VERSION "dbc-export 1 2025.20.8"

NS_ :

BS_:

BU_: ADSP APB APP APS BB BMS CC CP DAS DI DIF DIR EPAS3P EPAS3S EPBL EPBR GTW HVP ICR IDB PCS PM TCU UI UIS VC VCFRONT VCLEFT VCRIGHT VCSEC

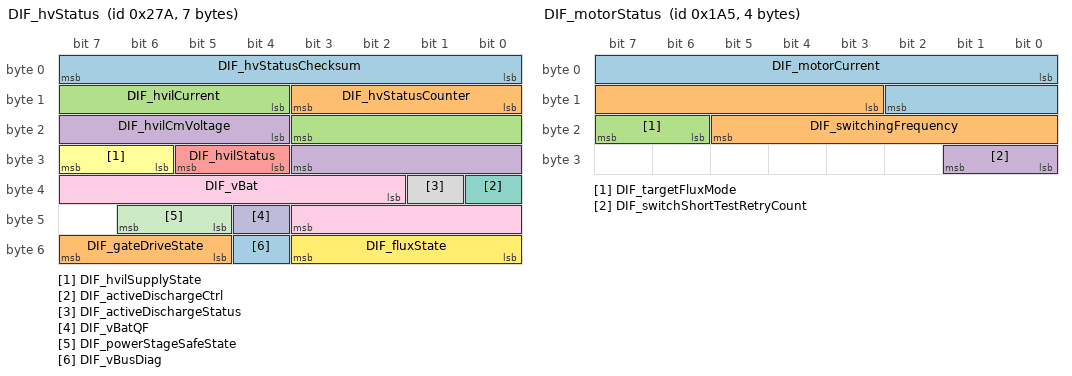
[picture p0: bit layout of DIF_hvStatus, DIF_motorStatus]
BO_ 634 DIF_hvStatus: 7 DIF
 SG_ DIF_hvStatusChecksum : 0|8@1+ (1,0) [0|255] "" Vector__XXX
 SG_ DIF_hvStatusCounter : 8|4@1+ (1,0) [0|15] "" Vector__XXX
 SG_ DIF_hvilCurrent : 12|8@1+ (0.1,0) [0|25.5] "mA" Vector__XXX
 SG_ DIF_hvilCmVoltage : 20|8@1+ (0.08,0) [0|20.4] "V" Vector__XXX
 SG_ DIF_hvilStatus : 28|2@1+ (1,0) [0|2] "" Vector__XXX
 SG_ DIF_hvilSupplyState : 30|2@1+ (1,0) [0|3] "" Vector__XXX
 SG_ DIF_activeDischargeCtrl : 32|1@1+ (1,0) [0|1] "" Vector__XXX
 SG_ DIF_activeDischargeStatus : 33|1@1+ (1,0) [0|1] "" Vector__XXX
 SG_ DIF_vBat : 34|10@1+ (1,0) [0|1023] "V" Vector__XXX
 SG_ DIF_vBatQF : 44|1@1+ (1,0) [0|1] "" Vector__XXX
 SG_ DIF_powerStageSafeState : 45|2@1+ (1,0) [0|3] "" Vector__XXX
 SG_ DIF_fluxState : 48|4@1+ (1,0) [0|15] "" Vector__XXX
 SG_ DIF_vBusDiag : 52|1@1+ (1,0) [0|1] "" Vector__XXX
 SG_ DIF_gateDriveState : 53|3@1+ (1,0) [0|7] "" Vector__XXX

BO_ 1622 DIF_info: 8 DIF
 SG_ DIF_infoIndex M : 0|8@1+ (1,0) [0|255] "" Vector__XXX
 SG_ DIF_buildType m10 : 8|3@1+ (1,0) [0|7] "" Vector__XXX
 SG_ DIF_buildConfigurationId m10 : 16|16@1+ (1,0) [0|65535] "" Vector__XXX
 SG_ DIF_hardwareId m10 : 32|8@1+ (1,0) [0|252] "" Vector__XXX
 SG_ DIF_componentId m10 : 48|16@1+ (1,0) [0|65535] "" Vector__XXX
 SG_ DIF_pcbaId m11 : 16|8@1+ (1,0) [0|255] "" Vector__XXX
 SG_ DIF_assemblyId m11 : 24|8@1+ (1,0) [0|255] "" Vector__XXX
 SG_ DIF_usageId m11 : 32|16@1+ (1,0) [0|65535] "" Vector__XXX
 SG_ DIF_subUsageId m11 : 48|16@1+ (1,0) [0|65535] "" Vector__XXX
 SG_ DIF_motorType m12 : 8|5@1+ (1,0) [1|31] "" Vector__XXX
 SG_ DIF_siliconType m12 : 16|1@1+ (1,0) [0|1] "" Vector__XXX
 SG_ DIF_mechSafeStateType m12 : 24|2@1+ (1,0) [1|3] "" Vector__XXX
 SG_ DIF_applicationCrc m13 : 32|32@1+ (1,0) [0|4294967295] "" Vector__XXX
 SG_ DIF_oilPumpBuildType m16 : 8|3@1+ (1,0) [0|7] "" Vector__XXX
 SG_ DIF_oilPumpAppCrc m16 : 16|32@1+ (1,0) [0|4294967295] "" Vector__XXX
 SG_ DIF_FPGA_version m16 : 48|8@1+ (1,0) [0|254] "" Vector__XXX
 SG_ DIF_appGitHash m17 : 8|56@1+ (1,0) [0|7.20575940379e+16] "" Vector__XXX
 SG_ DIF_bootGitHash m18 : 8|56@1+ (1,0) [0|7.20575940379e+16] "" Vector__XXX
 SG_ DIF_platformTyp m19 : 8|8@1+ (1,0) [0|255] "" Vector__XXX
 SG_ DIF_infoBootLdUdsProtocolVersion m20 : 8|8@1+ (1,0) [0|255] "" Vector__XXX
 SG_ DIF_bootloaderCrc m20 : 32|32@1+ (1,0) [0|4294967295] "" Vector__XXX
 SG_ DIF_oilPumpPcbaId m33 : 8|8@1+ (1,0) [0|255] "" Vector__XXX
 SG_ DIF_oilPumpAssemblyId m33 : 16|8@1+ (1,0) [0|255] "" Vector__XXX
 SG_ DIF_oilPumpUsageId m33 : 24|16@1+ (1,0) [0|65535] "" Vector__XXX
 SG_ DIF_refRotorFlux m35 : 8|16@1+ (0.0001,0) [0|6.5535] "Wb" Vector__XXX
 SG_ DIF_refRotorOffset m35 : 24|12@1- (0.1,0) [-180|180] "deg" Vector__XXX
 SG_ DIF_speedWearTotal m36 : 8|8@1+ (0.4,0) [0|100] "%" Vector__XXX
 SG_ DIF_torqueWearTotal m36 : 24|8@1+ (0.02,0) [0|5.08] "1" Vector__XXX

BO_ 421 DIF_motorStatus: 4 DIF
 SG_ DIF_motorCurrent : 0|11@1+ (1,0) [0|2047] "A" Vector__XXX
 SG_ DIF_switchingFrequency : 11|11@1+ (0.01,0) [0|20] "kHz" Vector__XXX
 SG_ DIF_targetFluxMode : 22|2@1+ (1,0) [0|3] "" Vector__XXX
 SG_ DIF_switchShortTestRetryCount : 24|2@1+ (1,0) [0|3] "" Vector__XXX

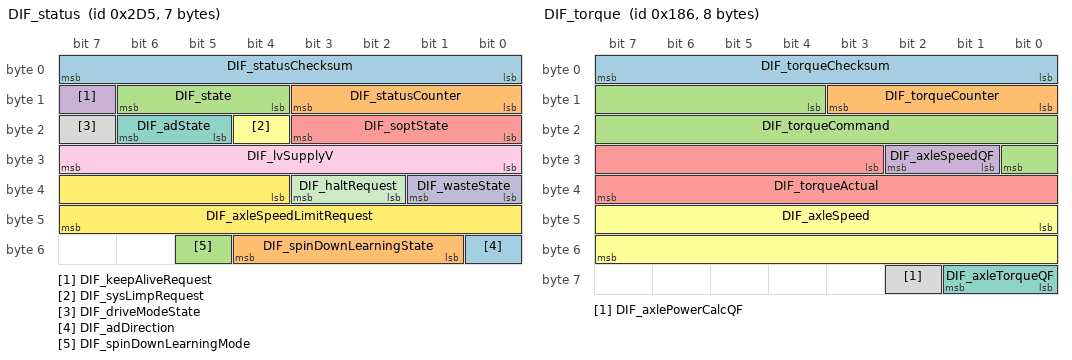
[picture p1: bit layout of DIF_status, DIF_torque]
BO_ 725 DIF_status: 7 DIF
 SG_ DIF_statusChecksum : 0|8@1+ (1,0) [0|255] "" Vector__XXX
 SG_ DIF_statusCounter : 8|4@1+ (1,0) [0|15] "" Vector__XXX
 SG_ DIF_state : 12|3@1+ (1,0) [0|7] "" Vector__XXX
 SG_ DIF_keepAliveRequest : 15|1@1+ (1,0) [0|1] "" Vector__XXX
 SG_ DIF_soptState : 16|4@1+ (1,0) [0|15] "" Vector__XXX
 SG_ DIF_sysLimpRequest : 20|1@1+ (1,0) [0|1] "" Vector__XXX
 SG_ DIF_adState : 21|2@1+ (1,0) [0|3] "" Vector__XXX
 SG_ DIF_driveModeState : 23|1@1+ (1,0) [0|1] "" Vector__XXX
 SG_ DIF_lvSupplyV : 24|8@1+ (0.1,0) [0|25.5] "V" Vector__XXX
 SG_ DIF_wasteState : 32|2@1+ (1,0) [0|3] "" Vector__XXX
 SG_ DIF_haltRequest : 34|2@1+ (1,0) [0|3] "" Vector__XXX
 SG_ DIF_axleSpeedLimitRequest : 36|12@1+ (1,40) [40|2750] "RPM" Vector__XXX
 SG_ DIF_adDirection : 48|1@1+ (1,0) [0|1] "" Vector__XXX
 SG_ DIF_spinDownLearningState : 49|4@1+ (1,0) [0|15] "" Vector__XXX
 SG_ DIF_spinDownLearningMode : 53|1@1+ (1,0) [0|1] "" Vector__XXX

BO_ 886 DIF_temperature: 8 DIF
 SG_ DIF_tempIndex M : 0|3@1+ (1,0) [0|7] "" Vector__XXX
 SG_ DIF_inverterTQF m0 : 3|2@1+ (1,0) [0|3] "" Vector__XXX
 SG_ DIF_pcbT m0 : 8|8@1+ (1,-40) [-39|215] "DegC" Vector__XXX
 SG_ DIF_inverterT m0 : 16|8@1+ (1,-40) [-40|215] "DegC" Vector__XXX
 SG_ DIF_statorT m0 : 24|8@1+ (1,-40) [-39|215] "DegC" Vector__XXX
 SG_ DIF_dcCapT m0 : 32|8@1+ (1,-40) [-39|215] "DegC" Vector__XXX
 SG_ DIF_heatsinkT m0 : 40|8@1+ (1,-40) [-39|215] "DegC" Vector__XXX
 SG_ DIF_inverterTpct m0 : 48|8@1+ (0.4,0) [0|100] "%" Vector__XXX
 SG_ DIF_statorTpct m0 : 56|8@1+ (0.4,0) [0|100] "%" Vector__XXX
 SG_ DIF_fluidInTemp m2 : 8|8@1+ (1,-40) [-39|215] "DegC" Vector__XXX
 SG_ DIF_normalFetBurnIn m2 : 16|16@1+ (0.00763,0) [0|500] "Hours" Vector__XXX
 SG_ DIF_additionalFetBurnIn m2 : 32|16@1+ (0.00763,0) [0|500] "Hours" Vector__XXX
 SG_ DIF_currentWeibullMiles m3 : 3|16@1+ (8,0) [0|500000] "miles" Vector__XXX
 SG_ DIF_endOfServiceWeibullMiles m3 : 19|16@1+ (8,0) [0|500000] "miles" Vector__XXX
 SG_ DIF_burnInDamageRatio m3 : 35|9@1+ (0.01,0) [0|5] "1" Vector__XXX
 SG_ DIF_inverterSensorEst m3 : 44|8@1+ (1,-40) [-40|120] "C" Vector__XXX
 SG_ DIF_inverterHS1Est m3 : 52|8@1+ (1,-40) [-40|120] "C" Vector__XXX
 SG_ DIF_initialBurnInVehicleOdometer m4 : 8|32@1+ (0.001,0) [0|4294967.294] "km" Vector__XXX
 SG_ DIF_inverterHS2Est m4 : 40|8@1+ (1,-40) [-40|120] "C" Vector__XXX
 SG_ DIF_inverterInletEst m4 : 48|8@1+ (1,-40) [-40|120] "C" Vector__XXX

BO_ 390 DIF_torque: 8 DIF
 SG_ DIF_torqueChecksum : 0|8@1+ (1,0) [0|255] "" Vector__XXX
 SG_ DIF_torqueCounter : 8|4@1+ (1,0) [0|15] "" Vector__XXX
 SG_ DIF_torqueCommand : 12|13@1- (2,0) [-7500|7500] "Nm" Vector__XXX
 SG_ DIF_axleSpeedQF : 25|2@1+ (1,0) [0|3] "" Vector__XXX
 SG_ DIF_torqueActual : 27|13@1- (2,0) [-7500|7500] "Nm" Vector__XXX
 SG_ DIF_axleSpeed : 40|16@1- (0.1,0) [-2750|2750] "RPM" Vector__XXX
 SG_ DIF_axleTorqueQF : 56|2@1+ (1,0) [0|3] "" Vector__XXX
 SG_ DIF_axlePowerCalcQF : 58|1@1+ (1,0) [0|1] "" Vector__XXX

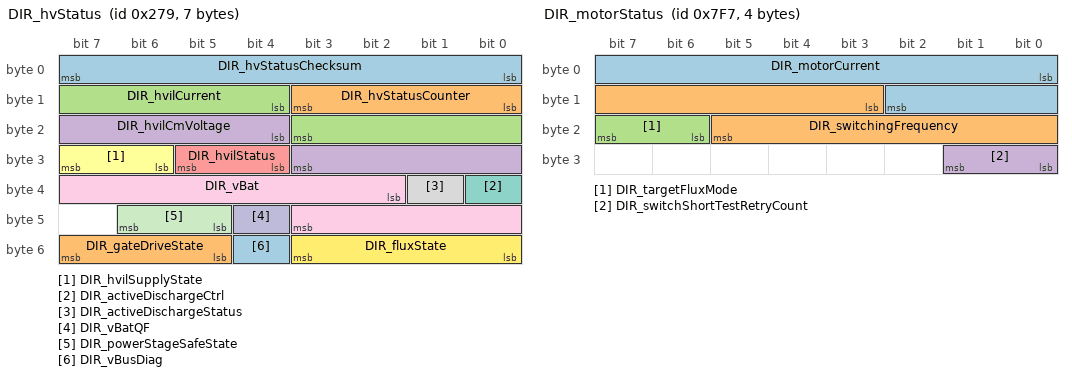
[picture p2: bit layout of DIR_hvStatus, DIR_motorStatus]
BO_ 633 DIR_hvStatus: 7 DIR
 SG_ DIR_hvStatusChecksum : 0|8@1+ (1,0) [0|255] "" Vector__XXX
 SG_ DIR_hvStatusCounter : 8|4@1+ (1,0) [0|15] "" Vector__XXX
 SG_ DIR_hvilCurrent : 12|8@1+ (0.1,0) [0|25.5] "mA" Vector__XXX
 SG_ DIR_hvilCmVoltage : 20|8@1+ (0.08,0) [0|20.4] "V" Vector__XXX
 SG_ DIR_hvilStatus : 28|2@1+ (1,0) [0|2] "" Vector__XXX
 SG_ DIR_hvilSupplyState : 30|2@1+ (1,0) [0|3] "" Vector__XXX
 SG_ DIR_activeDischargeCtrl : 32|1@1+ (1,0) [0|1] "" Vector__XXX
 SG_ DIR_activeDischargeStatus : 33|1@1+ (1,0) [0|1] "" Vector__XXX
 SG_ DIR_vBat : 34|10@1+ (1,0) [0|1023] "V" Vector__XXX
 SG_ DIR_vBatQF : 44|1@1+ (1,0) [0|1] "" Vector__XXX
 SG_ DIR_powerStageSafeState : 45|2@1+ (1,0) [0|3] "" Vector__XXX
 SG_ DIR_fluxState : 48|4@1+ (1,0) [0|15] "" Vector__XXX
 SG_ DIR_vBusDiag : 52|1@1+ (1,0) [0|1] "" Vector__XXX
 SG_ DIR_gateDriveState : 53|3@1+ (1,0) [0|7] "" Vector__XXX

BO_ 821 DIR_info: 8 DIR
 SG_ DIR_infoIndex M : 0|8@1+ (1,0) [0|255] "" Vector__XXX
 SG_ DIR_buildType m10 : 8|3@1+ (1,0) [0|7] "" Vector__XXX
 SG_ DIR_buildConfigurationId m10 : 16|16@1+ (1,0) [0|65535] "" Vector__XXX
 SG_ DIR_hardwareId m10 : 32|8@1+ (1,0) [0|252] "" Vector__XXX
 SG_ DIR_componentId m10 : 48|16@1+ (1,0) [0|65535] "" Vector__XXX
 SG_ DIR_pcbaId m11 : 16|8@1+ (1,0) [0|255] "" Vector__XXX
 SG_ DIR_assemblyId m11 : 24|8@1+ (1,0) [0|255] "" Vector__XXX
 SG_ DIR_usageId m11 : 32|16@1+ (1,0) [0|65535] "" Vector__XXX
 SG_ DIR_subUsageId m11 : 48|16@1+ (1,0) [0|65535] "" Vector__XXX
 SG_ DIR_motorType m12 : 8|5@1+ (1,0) [1|31] "" Vector__XXX
 SG_ DIR_siliconType m12 : 16|1@1+ (1,0) [0|1] "" Vector__XXX
 SG_ DIR_mechSafeStateType m12 : 24|2@1+ (1,0) [1|3] "" Vector__XXX
 SG_ DIR_applicationCrc m13 : 32|32@1+ (1,0) [0|4294967295] "" Vector__XXX
 SG_ DIR_oilPumpBuildType m16 : 8|3@1+ (1,0) [0|7] "" Vector__XXX
 SG_ DIR_oilPumpAppCrc m16 : 16|32@1+ (1,0) [0|4294967295] "" Vector__XXX
 SG_ DIR_FPGA_version m16 : 48|8@1+ (1,0) [0|254] "" Vector__XXX
 SG_ DIR_bootGitHash m18 : 8|56@1+ (1,0) [0|7.20575940379e+16] "" Vector__XXX
 SG_ DIR_infoBootLdUdsProtocolVersion m20 : 8|8@1+ (1,0) [0|255] "" Vector__XXX
 SG_ DIR_bootloaderCrc m20 : 32|32@1+ (1,0) [0|4294967295] "" Vector__XXX
 SG_ DIR_oilPumpPcbaId m33 : 8|8@1+ (1,0) [0|255] "" Vector__XXX
 SG_ DIR_oilPumpAssemblyId m33 : 16|8@1+ (1,0) [0|255] "" Vector__XXX
 SG_ DIR_oilPumpUsageId m33 : 24|16@1+ (1,0) [0|65535] "" Vector__XXX
 SG_ DIR_refRotorFlux m35 : 8|16@1+ (0.0001,0) [0|6.5535] "Wb" Vector__XXX
 SG_ DIR_refRotorOffset m35 : 24|12@1- (0.1,0) [-180|180] "deg" Vector__XXX
 SG_ DIR_speedWearTotal m36 : 8|8@1+ (0.4,0) [0|100] "%" Vector__XXX
 SG_ DIR_torqueWearTotal m36 : 24|8@1+ (0.02,0) [0|5.08] "1" Vector__XXX

BO_ 2039 DIR_motorStatus: 4 DIR
 SG_ DIR_motorCurrent : 0|11@1+ (1,0) [0|2047] "A" Vector__XXX
 SG_ DIR_switchingFrequency : 11|11@1+ (0.01,0) [0|20] "kHz" Vector__XXX
 SG_ DIR_targetFluxMode : 22|2@1+ (1,0) [0|3] "" Vector__XXX
 SG_ DIR_switchShortTestRetryCount : 24|2@1+ (1,0) [0|3] "" Vector__XXX

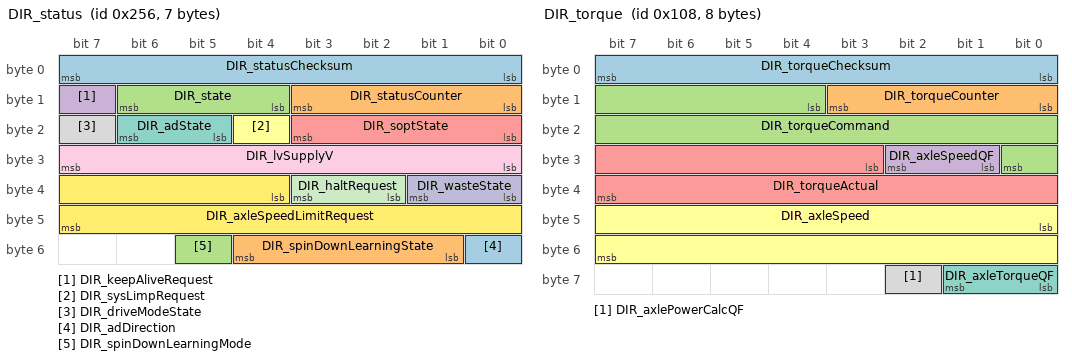
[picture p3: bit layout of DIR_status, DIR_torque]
BO_ 598 DIR_status: 7 DIR
 SG_ DIR_statusChecksum : 0|8@1+ (1,0) [0|255] "" Vector__XXX
 SG_ DIR_statusCounter : 8|4@1+ (1,0) [0|15] "" Vector__XXX
 SG_ DIR_state : 12|3@1+ (1,0) [0|7] "" Vector__XXX
 SG_ DIR_keepAliveRequest : 15|1@1+ (1,0) [0|1] "" Vector__XXX
 SG_ DIR_soptState : 16|4@1+ (1,0) [0|15] "" Vector__XXX
 SG_ DIR_sysLimpRequest : 20|1@1+ (1,0) [0|1] "" Vector__XXX
 SG_ DIR_adState : 21|2@1+ (1,0) [0|3] "" Vector__XXX
 SG_ DIR_driveModeState : 23|1@1+ (1,0) [0|1] "" Vector__XXX
 SG_ DIR_lvSupplyV : 24|8@1+ (0.1,0) [0|25.5] "V" Vector__XXX
 SG_ DIR_wasteState : 32|2@1+ (1,0) [0|3] "" Vector__XXX
 SG_ DIR_haltRequest : 34|2@1+ (1,0) [0|3] "" Vector__XXX
 SG_ DIR_axleSpeedLimitRequest : 36|12@1+ (1,40) [400|2750] "RPM" Vector__XXX
 SG_ DIR_adDirection : 48|1@1+ (1,0) [0|1] "" Vector__XXX
 SG_ DIR_spinDownLearningState : 49|4@1+ (1,0) [0|15] "" Vector__XXX
 SG_ DIR_spinDownLearningMode : 53|1@1+ (1,0) [0|1] "" Vector__XXX

BO_ 789 DIR_temperature: 8 DIR
 SG_ DIR_tempIndex M : 0|3@1+ (1,0) [0|7] "" Vector__XXX
 SG_ DIR_inverterTQF m0 : 3|2@1+ (1,0) [0|3] "" Vector__XXX
 SG_ DIR_pcbT m0 : 8|8@1+ (1,-40) [-39|215] "DegC" Vector__XXX
 SG_ DIR_inverterT m0 : 16|8@1+ (1,-40) [-40|215] "DegC" Vector__XXX
 SG_ DIR_statorT m0 : 24|8@1+ (1,-40) [-39|215] "DegC" Vector__XXX
 SG_ DIR_dcCapT m0 : 32|8@1+ (1,-40) [-39|215] "DegC" Vector__XXX
 SG_ DIR_heatsinkT m0 : 40|8@1+ (1,-40) [-39|215] "DegC" Vector__XXX
 SG_ DIR_inverterTpct m0 : 48|8@1+ (0.4,0) [0|100] "%" Vector__XXX
 SG_ DIR_statorTpct m0 : 56|8@1+ (0.4,0) [0|100] "%" Vector__XXX
 SG_ DIR_fluidInTemp m2 : 8|8@1+ (1,-40) [-39|215] "DegC" Vector__XXX
 SG_ DIR_normalFetBurnIn m2 : 16|16@1+ (0.00763,0) [0|500] "Hours" Vector__XXX
 SG_ DIR_additionalFetBurnIn m2 : 32|16@1+ (0.00763,0) [0|500] "Hours" Vector__XXX
 SG_ DIR_currentWeibullMiles m3 : 3|16@1+ (8,0) [0|500000] "miles" Vector__XXX
 SG_ DIR_endOfServiceWeibullMiles m3 : 19|16@1+ (8,0) [0|500000] "miles" Vector__XXX
 SG_ DIR_burnInDamageRatio m3 : 35|9@1+ (0.01,0) [0|5] "1" Vector__XXX
 SG_ DIR_inverterSensorEst m3 : 44|8@1+ (1,-40) [-40|120] "C" Vector__XXX
 SG_ DIR_inverterHS1Est m3 : 52|8@1+ (1,-40) [-40|120] "C" Vector__XXX
 SG_ DIR_initialBurnInVehicleOdometer m4 : 8|32@1+ (0.001,0) [0|4294967.294] "km" Vector__XXX
 SG_ DIR_inverterHS2Est m4 : 40|8@1+ (1,-40) [-40|120] "C" Vector__XXX
 SG_ DIR_inverterInletEst m4 : 48|8@1+ (1,-40) [-40|120] "C" Vector__XXX

BO_ 264 DIR_torque: 8 DIR
 SG_ DIR_torqueChecksum : 0|8@1+ (1,0) [0|255] "" Vector__XXX
 SG_ DIR_torqueCounter : 8|4@1+ (1,0) [0|15] "" Vector__XXX
 SG_ DIR_torqueCommand : 12|13@1- (2,0) [-7500|7500] "Nm" Vector__XXX
 SG_ DIR_axleSpeedQF : 25|2@1+ (1,0) [0|3] "" Vector__XXX
 SG_ DIR_torqueActual : 27|13@1- (2,0) [-7500|7500] "Nm" Vector__XXX
 SG_ DIR_axleSpeed : 40|16@1- (0.1,0) [-2750|2750] "RPM" Vector__XXX
 SG_ DIR_axleTorqueQF : 56|2@1+ (1,0) [0|3] "" Vector__XXX
 SG_ DIR_axlePowerCalcQF : 58|1@1+ (1,0) [0|1] "" Vector__XXX

BO_ 1861 DI_chassisControl2: 8 DI
 SG_ DI_gradeAngle : 0|6@1- (0.01,0) [-0.3125|0.31] "rad" Vector__XXX
 SG_ DI_bankAngle : 6|6@1- (0.01,0) [-0.3125|0.31] "rad" Vector__XXX
 SG_ DI_chassisControlVideoRequest : 12|4@1+ (1,0) [0|15] "" Vector__XXX
 SG_ DI_tireUtilizationRatioFrL : 17|5@1+ (0.0625,0) [0|1.9375] "-" Vector__XXX
 SG_ DI_tireUtilizationRatioFrR : 22|5@1+ (0.0625,0) [0|1.9375] "-" Vector__XXX
 SG_ DI_tireUtilizationRatioReL : 27|5@1+ (0.0625,0) [0|1.9375] "-" Vector__XXX
 SG_ DI_tireUtilizationRatioReR : 32|5@1+ (0.0625,0) [0|1.9375] "-" Vector__XXX
 SG_ DI_counterSteerTarget : 37|2@1+ (1,0) [0|3] "" Vector__XXX
 SG_ DI_splitMuProbability : 39|2@1+ (0.334,0) [0|1] "-" Vector__XXX
 SG_ DI_mzError : 41|2@1+ (1667,0) [0|5000] "Nm" Vector__XXX
 SG_ DI_slipDifferenceFrontRear : 43|3@1- (0.133,0) [-0.52|0.399] "rad" Vector__XXX
 SG_ DI_highFreqYawRate : 46|2@1+ (0.334,0) [0|1] "-" Vector__XXX
 SG_ DI_turnDirection : 48|1@1+ (1,0) [0|1] "" Vector__XXX
 SG_ DI_absolutePreControlRequest : 49|2@1+ (5000,0) [0|15000] "Nm" Vector__XXX
 SG_ DI_oppositeBuildDirFrontAxle : 51|1@1+ (1,0) [0|1] "" Vector__XXX
 SG_ DI_oppositeBuildDirRearAxle : 52|1@1+ (1,0) [0|1] "" Vector__XXX
 SG_ DI_saturatedEffectiveness : 53|1@1+ (1,0) [0|1] "" Vector__XXX
 SG_ DI_driverPanicIndex : 54|2@1+ (0.334,0) [0|1] "-" Vector__XXX
 SG_ DI_learnDownMu : 56|2@1+ (0.334,0) [0|1] "mu" Vector__XXX
 SG_ DI_preControlOpposingTurnDir : 58|1@1+ (1,0) [0|1] "" Vector__XXX
 SG_ DI_driverFxError : 59|2@1+ (1000,0) [0|3000] "N" Vector__XXX
 SG_ DI_targetSaturation : 61|3@1+ (0.572,0) [0|4] "G" Vector__XXX

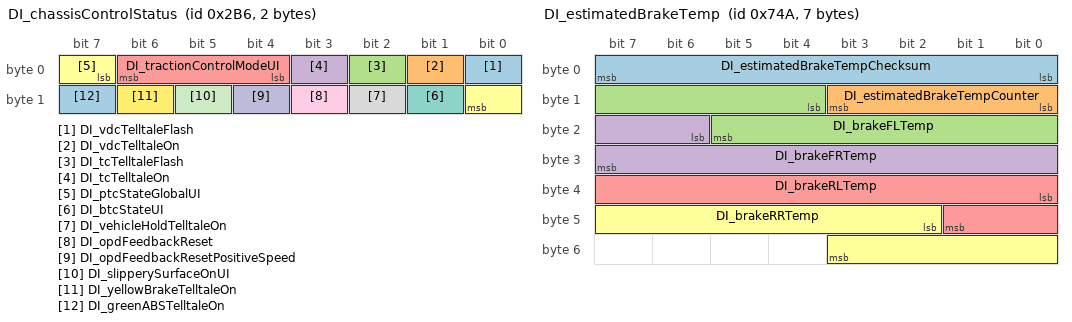
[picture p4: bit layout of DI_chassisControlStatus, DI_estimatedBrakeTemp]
BO_ 694 DI_chassisControlStatus: 2 DI
 SG_ DI_vdcTelltaleFlash : 0|1@1+ (1,0) [0|1] "" Vector__XXX
 SG_ DI_vdcTelltaleOn : 1|1@1+ (1,0) [0|1] "" Vector__XXX
 SG_ DI_tcTelltaleFlash : 2|1@1+ (1,0) [0|1] "" Vector__XXX
 SG_ DI_tcTelltaleOn : 3|1@1+ (1,0) [0|1] "" Vector__XXX
 SG_ DI_tractionControlModeUI : 4|3@1+ (1,0) [0|7] "" Vector__XXX
 SG_ DI_ptcStateGlobalUI : 7|2@1+ (1,0) [0|2] "" Vector__XXX
 SG_ DI_btcStateUI : 9|1@1+ (1,0) [0|1] "" Vector__XXX
 SG_ DI_vehicleHoldTelltaleOn : 10|1@1+ (1,0) [0|1] "" Vector__XXX
 SG_ DI_opdFeedbackReset : 11|1@1+ (1,0) [0|1] "" Vector__XXX
 SG_ DI_opdFeedbackResetPositiveSpeed : 12|1@1+ (1,0) [0|1] "" Vector__XXX
 SG_ DI_slipperySurfaceOnUI : 13|1@1+ (1,0) [0|1] "" Vector__XXX
 SG_ DI_yellowBrakeTelltaleOn : 14|1@1+ (1,0) [0|1] "" Vector__XXX
 SG_ DI_greenABSTelltaleOn : 15|1@1+ (1,0) [0|1] "" Vector__XXX

BO_ 1866 DI_estimatedBrakeTemp: 7 DI
 SG_ DI_estimatedBrakeTempChecksum : 0|8@1+ (1,0) [0|255] "" Vector__XXX
 SG_ DI_estimatedBrakeTempCounter : 8|4@1+ (1,0) [0|15] "" Vector__XXX
 SG_ DI_brakeFLTemp : 12|10@1+ (1,-40) [-40|982] "DegC" Vector__XXX
 SG_ DI_brakeFRTemp : 22|10@1+ (1,-40) [-40|982] "DegC" Vector__XXX
 SG_ DI_brakeRLTemp : 32|10@1+ (1,-40) [-40|982] "DegC" Vector__XXX
 SG_ DI_brakeRRTemp : 42|10@1+ (1,-40) [-40|982] "DegC" Vector__XXX

BO_ 1623 DI_info: 8 DI
 SG_ DI_infoIndex M : 0|8@1+ (1,0) [0|255] "" Vector__XXX
 SG_ DI_buildType m10 : 8|3@1+ (1,0) [0|7] "" Vector__XXX
 SG_ DI_buildConfigurationId m10 : 16|16@1+ (1,0) [0|65535] "" Vector__XXX
 SG_ DI_hardwareId m10 : 32|8@1+ (1,0) [0|252] "" Vector__XXX
 SG_ DI_componentId m10 : 48|16@1+ (1,0) [0|65535] "" Vector__XXX
 SG_ DI_pcbaId m11 : 16|8@1+ (1,0) [0|255] "" Vector__XXX
 SG_ DI_assemblyId m11 : 24|8@1+ (1,0) [0|255] "" Vector__XXX
 SG_ DI_usageId m11 : 32|16@1+ (1,0) [0|65535] "" Vector__XXX
 SG_ DI_subUsageId m11 : 48|16@1+ (1,0) [0|65535] "" Vector__XXX
 SG_ DI_applicationCrc m13 : 32|32@1+ (1,0) [0|4294967295] "" Vector__XXX
 SG_ DI_bootGitHash m18 : 8|56@1+ (1,0) [0|7.20575940379e+16] "" Vector__XXX

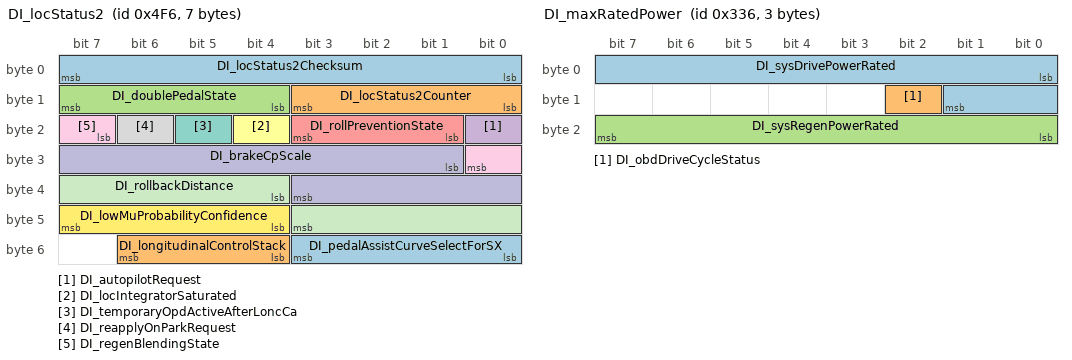
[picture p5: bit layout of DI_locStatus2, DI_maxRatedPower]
BO_ 1270 DI_locStatus2: 7 DI
 SG_ DI_locStatus2Checksum : 0|8@1+ (1,0) [0|255] "" Vector__XXX
 SG_ DI_locStatus2Counter : 8|4@1+ (1,0) [0|15] "" Vector__XXX
 SG_ DI_doublePedalState : 12|4@1+ (1,0) [0|15] "" Vector__XXX
 SG_ DI_autopilotRequest : 16|1@1+ (1,0) [0|1] "" Vector__XXX
 SG_ DI_rollPreventionState : 17|3@1+ (1,0) [0|7] "" Vector__XXX
 SG_ DI_locIntegratorSaturated : 20|1@1+ (1,0) [0|1] "" Vector__XXX
 SG_ DI_temporaryOpdActiveAfterLoncCa : 21|1@1+ (1,0) [0|1] "" Vector__XXX
 SG_ DI_reapplyOnParkRequest : 22|1@1+ (1,0) [0|1] "" Vector__XXX
 SG_ DI_regenBlendingState : 23|2@1+ (1,0) [0|3] "" Vector__XXX
 SG_ DI_brakeCpScale : 25|11@1+ (0.005,0) [0|10] "N/N" Vector__XXX
 SG_ DI_rollbackDistance : 36|8@1+ (0.005,0) [0|1.275] "m" Vector__XXX
 SG_ DI_lowMuProbabilityConfidence : 44|4@1+ (0.06666667,0) [0|1] "-" Vector__XXX
 SG_ DI_pedalAssistCurveSelectForSX : 48|4@1+ (1,0) [0|15] "" Vector__XXX
 SG_ DI_longitudinalControlStack : 52|3@1+ (1,0) [1|7] "" Vector__XXX

BO_ 822 DI_maxRatedPower: 3 DI
 SG_ DI_sysDrivePowerRated : 0|10@1+ (1,0) [0|1023] "kW" Vector__XXX
 SG_ DI_obdDriveCycleStatus : 10|1@1+ (1,0) [0|1] "" Vector__XXX
 SG_ DI_sysRegenPowerRated : 16|8@1+ (1,-100) [-100|0] "kW" Vector__XXX

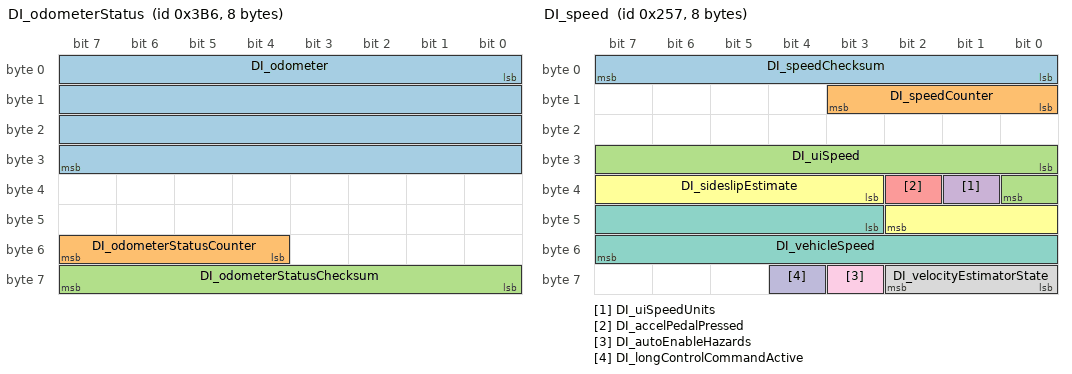
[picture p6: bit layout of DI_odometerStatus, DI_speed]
BO_ 950 DI_odometerStatus: 8 DI
 SG_ DI_odometer : 0|32@1+ (0.001,0) [0|4294967.294] "km" Vector__XXX
 SG_ DI_odometerStatusCounter : 52|4@1+ (1,0) [0|15] "" Vector__XXX
 SG_ DI_odometerStatusChecksum : 56|8@1+ (1,0) [0|255] "" Vector__XXX

BO_ 599 DI_speed: 8 DI
 SG_ DI_speedChecksum : 0|8@1+ (1,0) [0|255] "" Vector__XXX
 SG_ DI_speedCounter : 8|4@1+ (1,0) [0|15] "" Vector__XXX
 SG_ DI_uiSpeed : 24|9@1+ (1,0) [0|510] "" Vector__XXX
 SG_ DI_uiSpeedUnits : 33|1@1+ (1,0) [0|1] "" Vector__XXX
 SG_ DI_accelPedalPressed : 34|1@1+ (1,0) [0|1] "" Vector__XXX
 SG_ DI_sideslipEstimate : 35|8@1- (0.0025,0) [-0.32|0.3175] "rad" Vector__XXX
 SG_ DI_vehicleSpeed : 43|13@1+ (0.08,-40) [-40|480] "kph" Vector__XXX
 SG_ DI_velocityEstimatorState : 56|3@1+ (1,0) [0|7] "" Vector__XXX
 SG_ DI_autoEnableHazards : 59|1@1+ (1,0) [0|1] "" Vector__XXX
 SG_ DI_longControlCommandActive : 60|1@1+ (1,0) [0|1] "" Vector__XXX

BO_ 296 DI_systemLimits: 4 DI
 SG_ DI_limitRegenPower : 0|1@1+ (1,0) [0|1] "" Vector__XXX
 SG_ DI_limitIBat : 1|1@1+ (1,0) [0|1] "" Vector__XXX
 SG_ DI_limitVBatLow : 2|1@1+ (1,0) [0|1] "" Vector__XXX
 SG_ DI_limitVBatHigh : 3|1@1+ (1,0) [0|1] "" Vector__XXX
 SG_ DI_limitObstacleDetection : 4|1@1+ (1,0) [0|1] "" Vector__XXX
 SG_ DI_limitSystemLimp : 5|1@1+ (1,0) [0|1] "" Vector__XXX
 SG_ DI_limitSystemGPO : 6|1@1+ (1,0) [0|1] "" Vector__XXX
 SG_ DI_limitShift : 7|1@1+ (1,0) [0|1] "" Vector__XXX
 SG_ DI_limitDriveTorque : 8|1@1+ (1,0) [0|1] "" Vector__XXX
 SG_ DI_limitRegenTorque : 9|1@1+ (1,0) [0|1] "" Vector__XXX
 SG_ DI_limitVehicleSpeed : 10|1@1+ (1,0) [0|1] "" Vector__XXX
 SG_ DI_limitBmsMiaFreeze : 11|1@1+ (1,0) [0|1] "" Vector__XXX
 SG_ DI_limitSystemSpinDownLearning : 12|1@1+ (1,0) [0|1] "" Vector__XXX
 SG_ DI_limitCdp : 13|1@1+ (1,0) [0|1] "" Vector__XXX
 SG_ DI_vehicleSpeedLimitType : 14|2@1+ (1,0) [0|3] "" Vector__XXX
 SG_ DI_vehicleSpeedLimit : 16|9@1+ (1,0) [0|510] "kph" Vector__XXX
 SG_ DI_vehicleSpeedLimitReason : 25|4@1+ (1,0) [0|15] "" Vector__XXX
 SG_ DI_limitClosureNotClosed : 29|1@1+ (1,0) [0|1] "" Vector__XXX
 SG_ DI_proximity : 30|1@1+ (1,0) [0|1] "" Vector__XXX
 SG_ DI_undersideAbuse : 31|1@1+ (1,0) [0|1] "" Vector__XXX

BO_ 280 DI_systemStatus: 8 DI
 SG_ DI_systemStatusChecksum : 0|8@1+ (1,0) [0|255] "" Vector__XXX
 SG_ DI_systemStatusCounter : 8|4@1+ (1,0) [0|15] "" Vector__XXX
 SG_ DI_secondaryGearControlStatus : 12|1@1+ (1,0) [0|1] "" Vector__XXX
 SG_ DI_immobilizerState : 13|3@1+ (1,0) [1|7] "" Vector__XXX
 SG_ DI_systemState : 16|3@1+ (1,0) [0|7] "" Vector__XXX
 SG_ DI_brakePedalState : 19|2@1+ (1,0) [0|3] "" Vector__XXX
 SG_ DI_gear : 21|3@1+ (1,0) [0|6] "" Vector__XXX
 SG_ DI_driveBlocked : 24|3@1+ (1,0) [0|7] "" Vector__XXX
 SG_ DI_hvilSystemStatus : 27|2@1+ (1,0) [0|2] "" Vector__XXX
 SG_ DI_driveModeState : 29|1@1+ (1,0) [0|1] "" Vector__XXX
 SG_ DI_shiftRequestType : 30|2@1+ (1,0) [0|3] "" Vector__XXX
 SG_ DI_accelPedalPos : 32|8@1+ (0.4,0) [0|100] "%" Vector__XXX
 SG_ DI_tractionControlMode : 40|3@1+ (1,0) [0|7] "" Vector__XXX
 SG_ DI_dynoModeAvailable : 43|1@1+ (1,0) [0|1] "" Vector__XXX
 SG_ DI_epbRequest : 44|2@1+ (1,0) [0|3] "" Vector__XXX
 SG_ DI_eepDeliveryBitStatus : 46|1@1+ (1,0) [0|1] "" Vector__XXX
 SG_ DI_keepDrivePowerStateRequest : 47|1@1+ (1,0) [0|1] "" Vector__XXX
 SG_ DI_trackModeState : 48|2@1+ (1,0) [0|3] "" Vector__XXX
 SG_ DI_regenLight : 51|1@1+ (1,0) [0|1] "" Vector__XXX
 SG_ DI_vehicleAcceleration : 52|12@1- (0.01,0) [-20.47|20.47] "m/s^2" Vector__XXX

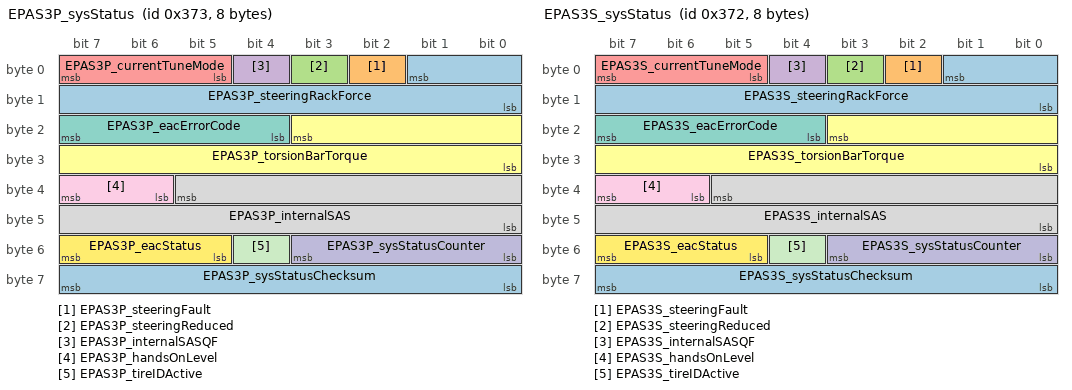
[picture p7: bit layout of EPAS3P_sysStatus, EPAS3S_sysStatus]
BO_ 883 EPAS3P_sysStatus: 8 EPAS3P
 SG_ EPAS3P_steeringRackForce : 1|10@0+ (50,-25575) [-25575|25525] "N" Vector__XXX
 SG_ EPAS3P_steeringFault : 2|1@1+ (1,0) [0|1] "" Vector__XXX
 SG_ EPAS3P_steeringReduced : 3|1@1+ (1,0) [0|1] "" Vector__XXX
 SG_ EPAS3P_internalSASQF : 4|1@1+ (1,0) [0|1] "" Vector__XXX
 SG_ EPAS3P_currentTuneMode : 5|3@1+ (1,0) [0|7] "" Vector__XXX
 SG_ EPAS3P_torsionBarTorque : 19|12@0+ (0.01,-20.5) [-20.5|20.44] "Nm" Vector__XXX
 SG_ EPAS3P_eacErrorCode : 20|4@1+ (1,0) [0|14] "" Vector__XXX
 SG_ EPAS3P_internalSAS : 37|14@0+ (0.1,-819.2) [-819.2|819] "deg" Vector__XXX
 SG_ EPAS3P_handsOnLevel : 38|2@1+ (1,0) [0|3] "" Vector__XXX
 SG_ EPAS3P_sysStatusCounter : 48|4@1+ (1,0) [0|15] "" Vector__XXX
 SG_ EPAS3P_tireIDActive : 52|1@1+ (1,0) [0|1] "" Vector__XXX
 SG_ EPAS3P_eacStatus : 53|3@1+ (1,0) [0|7] "" Vector__XXX
 SG_ EPAS3P_sysStatusChecksum : 56|8@1+ (1,0) [0|255] "" Vector__XXX

BO_ 882 EPAS3S_sysStatus: 8 EPAS3S
 SG_ EPAS3S_steeringRackForce : 1|10@0+ (50,-25575) [-25575|25525] "N" Vector__XXX
 SG_ EPAS3S_steeringFault : 2|1@1+ (1,0) [0|1] "" Vector__XXX
 SG_ EPAS3S_steeringReduced : 3|1@1+ (1,0) [0|1] "" Vector__XXX
 SG_ EPAS3S_internalSASQF : 4|1@1+ (1,0) [0|1] "" Vector__XXX
 SG_ EPAS3S_currentTuneMode : 5|3@1+ (1,0) [0|7] "" Vector__XXX
 SG_ EPAS3S_torsionBarTorque : 19|12@0+ (0.01,-20.5) [-20.5|20.44] "Nm" Vector__XXX
 SG_ EPAS3S_eacErrorCode : 20|4@1+ (1,0) [0|14] "" Vector__XXX
 SG_ EPAS3S_internalSAS : 37|14@0+ (0.1,-819.2) [-819.2|819] "deg" Vector__XXX
 SG_ EPAS3S_handsOnLevel : 38|2@1+ (1,0) [0|3] "" Vector__XXX
 SG_ EPAS3S_sysStatusCounter : 48|4@1+ (1,0) [0|15] "" Vector__XXX
 SG_ EPAS3S_tireIDActive : 52|1@1+ (1,0) [0|1] "" Vector__XXX
 SG_ EPAS3S_eacStatus : 53|3@1+ (1,0) [0|7] "" Vector__XXX
 SG_ EPAS3S_sysStatusChecksum : 56|8@1+ (1,0) [0|255] "" Vector__XXX

BO_ 681 EPBL_status: 8 EPBL
 SG_ EPBL_systemStatus : 0|4@1+ (1,0) [0|15] "" Vector__XXX
 SG_ EPBL_freeRollModeStatus : 4|2@1+ (1,0) [0|3] "" Vector__XXX
 SG_ EPBL_driverIsLeaving : 6|1@1+ (1,0) [0|1] "" Vector__XXX
 SG_ EPBL_driverIsLeavingAnySpeed : 7|1@1+ (1,0) [0|1] "" Vector__XXX
 SG_ EPBL_systemCdpAvailable : 8|1@1+ (1,0) [0|1] "" Vector__XXX
 SG_ EPBL_chimeRequest : 9|3@1+ (1,0) [0|7] "" Vector__XXX
 SG_ EPBL_telltale : 12|3@1+ (1,0) [0|6] "" Vector__XXX
 SG_ EPBL_contactorCycleNotNeededForW : 15|1@1+ (1,0) [0|1] "" Vector__XXX
 SG_ EPBL_redundantBrakingEnabled : 16|1@1+ (1,0) [0|1] "" Vector__XXX
 SG_ EPBL_summonEnabled : 17|1@1+ (1,0) [0|1] "" Vector__XXX
 SG_ EPBL_brakeLight : 18|1@1+ (1,0) [0|1] "" Vector__XXX
 SG_ EPBL_epbConfigMismatch : 19|1@1+ (1,0) [0|1] "" Vector__XXX
 SG_ EPBL_brakeConfirmedPressed : 20|1@1+ (1,0) [0|1] "" Vector__XXX
 SG_ EPBL_requestUserConfirmation : 21|1@1+ (1,0) [0|1] "" Vector__XXX
 SG_ EPBL_uiWinchModeMiscBlocking : 22|1@1+ (1,0) [0|1] "" Vector__XXX
 SG_ EPBL_winchModeActive : 23|1@1+ (1,0) [0|1] "" Vector__XXX
 SG_ EPBL_updateMode : 24|1@1+ (1,0) [0|1] "" Vector__XXX
 SG_ EPBL_winchModePermissive : 25|1@1+ (1,0) [0|1] "" Vector__XXX
 SG_ EPBL_winchModePending : 26|1@1+ (1,0) [0|1] "" Vector__XXX
 SG_ EPBL_cdpRequest : 27|1@1+ (1,0) [0|1] "" Vector__XXX
 SG_ EPBL_uiParkAvailable : 28|2@1+ (1,0) [0|3] "" Vector__XXX
 SG_ EPBL_brakeDiscWipeRequest : 30|2@1+ (1,0) [0|2] "" Vector__XXX
 SG_ EPBL_showUiGearShifter : 32|1@1+ (1,0) [0|1] "" Vector__XXX
 SG_ EPBL_uiWinchModeLvStatus : 33|2@1+ (1,0) [0|3] "" Vector__XXX
 SG_ EPBL_showStalkFaultedOnUi : 45|1@1+ (1,0) [0|1] "" Vector__XXX
 SG_ EPBL_espPowerRequest : 46|1@1+ (1,0) [0|1] "" Vector__XXX
 SG_ EPBL_okToPark : 47|1@1+ (1,0) [0|1] "" Vector__XXX
 SG_ EPBL_hornRequest : 48|1@1+ (1,0) [0|1] "" Vector__XXX
 SG_ EPBL_winchModeAvailable : 49|1@1+ (1,0) [0|1] "" Vector__XXX
 SG_ EPBL_bothDisconnected : 50|1@1+ (1,0) [0|1] "" Vector__XXX
 SG_ EPBL_blockDrive : 51|1@1+ (1,0) [0|1] "" Vector__XXX
 SG_ EPBL_statusCounter : 52|4@1+ (1,0) [0|15] "" Vector__XXX
 SG_ EPBL_statusChecksum : 56|8@1+ (1,0) [0|255] "" Vector__XXX

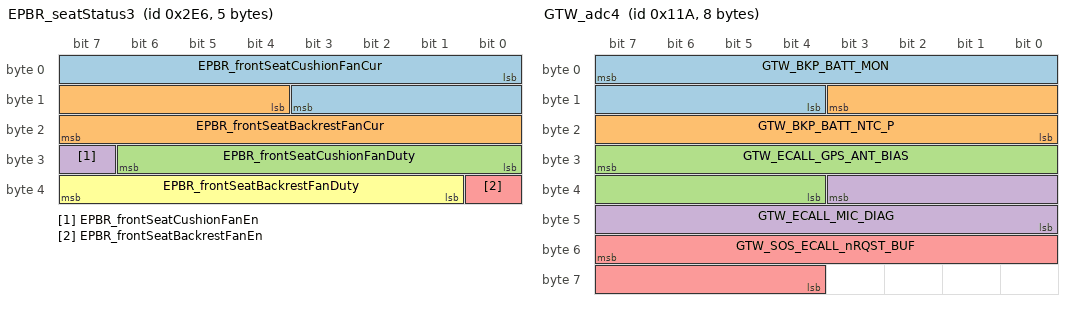
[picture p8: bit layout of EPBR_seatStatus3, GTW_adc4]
BO_ 742 EPBR_seatStatus3: 5 EPBR
 SG_ EPBR_frontSeatCushionFanCur : 0|12@1+ (0.01,0) [0|40.95] "A" Vector__XXX
 SG_ EPBR_frontSeatBackrestFanCur : 12|12@1+ (0.01,0) [0|40.95] "A" Vector__XXX
 SG_ EPBR_frontSeatCushionFanDuty : 24|7@1+ (1,0) [0|100] "%" Vector__XXX
 SG_ EPBR_frontSeatCushionFanEn : 31|1@1+ (1,0) [0|1] "" Vector__XXX
 SG_ EPBR_frontSeatBackrestFanEn : 32|1@1+ (1,0) [0|1] "" Vector__XXX
 SG_ EPBR_frontSeatBackrestFanDuty : 33|7@1+ (1,0) [0|100] "%" Vector__XXX

BO_ 744 EPBR_status: 8 EPBR
 SG_ EPBR_systemStatus : 0|4@1+ (1,0) [0|15] "" Vector__XXX
 SG_ EPBR_freeRollModeStatus : 4|2@1+ (1,0) [0|3] "" Vector__XXX
 SG_ EPBR_driverIsLeaving : 6|1@1+ (1,0) [0|1] "" Vector__XXX
 SG_ EPBR_driverIsLeavingAnySpeed : 7|1@1+ (1,0) [0|1] "" Vector__XXX
 SG_ EPBR_systemCdpAvailable : 8|1@1+ (1,0) [0|1] "" Vector__XXX
 SG_ EPBR_chimeRequest : 9|3@1+ (1,0) [0|7] "" Vector__XXX
 SG_ EPBR_telltale : 12|3@1+ (1,0) [0|6] "" Vector__XXX
 SG_ EPBR_audioCurrentSpikeDetected : 15|1@1+ (1,0) [0|1] "" Vector__XXX
 SG_ EPBR_redundantBrakingEnabled : 16|1@1+ (1,0) [0|1] "" Vector__XXX
 SG_ EPBR_summonEnabled : 17|1@1+ (1,0) [0|1] "" Vector__XXX
 SG_ EPBR_brakeLight : 18|1@1+ (1,0) [0|1] "" Vector__XXX
 SG_ EPBR_epbConfigMismatch : 19|1@1+ (1,0) [0|1] "" Vector__XXX
 SG_ EPBR_brakeConfirmedPressed : 20|1@1+ (1,0) [0|1] "" Vector__XXX
 SG_ EPBR_requestUserConfirmation : 21|1@1+ (1,0) [0|1] "" Vector__XXX
 SG_ EPBR_uiWinchModeMiscBlocking : 22|1@1+ (1,0) [0|1] "" Vector__XXX
 SG_ EPBR_winchModeActive : 23|1@1+ (1,0) [0|1] "" Vector__XXX
 SG_ EPBR_updateMode : 24|1@1+ (1,0) [0|1] "" Vector__XXX
 SG_ EPBR_winchModePermissive : 25|1@1+ (1,0) [0|1] "" Vector__XXX
 SG_ EPBR_winchModePending : 26|1@1+ (1,0) [0|1] "" Vector__XXX
 SG_ EPBR_cdpRequest : 27|1@1+ (1,0) [0|1] "" Vector__XXX
 SG_ EPBR_uiParkAvailable : 28|2@1+ (1,0) [0|3] "" Vector__XXX
 SG_ EPBR_brakeDiscWipeRequest : 30|2@1+ (1,0) [0|2] "" Vector__XXX
 SG_ EPBR_showUiGearShifter : 32|1@1+ (1,0) [0|1] "" Vector__XXX
 SG_ EPBR_uiWinchModeLvStatus : 33|2@1+ (1,0) [0|3] "" Vector__XXX
 SG_ EPBR_contactorCycleNotNeededForW : 35|1@1+ (1,0) [0|1] "" Vector__XXX
 SG_ EPBR_showStalkFaultedOnUi : 45|1@1+ (1,0) [0|1] "" Vector__XXX
 SG_ EPBR_espPowerRequest : 46|1@1+ (1,0) [0|1] "" Vector__XXX
 SG_ EPBR_okToPark : 47|1@1+ (1,0) [0|1] "" Vector__XXX
 SG_ EPBR_hornRequest : 48|1@1+ (1,0) [0|1] "" Vector__XXX
 SG_ EPBR_winchModeAvailable : 49|1@1+ (1,0) [0|1] "" Vector__XXX
 SG_ EPBR_bothDisconnected : 50|1@1+ (1,0) [0|1] "" Vector__XXX
 SG_ EPBR_blockDrive : 51|1@1+ (1,0) [0|1] "" Vector__XXX
 SG_ EPBR_statusCounter : 52|4@1+ (1,0) [0|15] "" Vector__XXX
 SG_ EPBR_statusChecksum : 56|8@1+ (1,0) [0|255] "" Vector__XXX

BO_ 888 GTW_ECall: 1 GTW
 SG_ GTW_GTW_SOS_ECALL_RQST : 0|1@1+ (1,0) [0|1] "" Vector__XXX
 SG_ GTW_LTE_ECALL_LOCK : 1|1@1+ (1,0) [0|1] "" Vector__XXX

BO_ 282 GTW_adc4: 8 GTW
 SG_ GTW_BKP_BATT_MON : 7|12@0+ (1,0) [0|4094] "mV" Vector__XXX
 SG_ GTW_BKP_BATT_NTC_P : 11|12@0+ (1,0) [0|4094] "mV" Vector__XXX
 SG_ GTW_ECALL_GPS_ANT_BIAS : 31|12@0+ (1,0) [0|4094] "mV" Vector__XXX
 SG_ GTW_ECALL_MIC_DIAG : 35|12@0+ (1,0) [0|4094] "mV" Vector__XXX
 SG_ GTW_SOS_ECALL_nRQST_BUF : 55|12@0+ (1,0) [0|4094] "mV" Vector__XXX

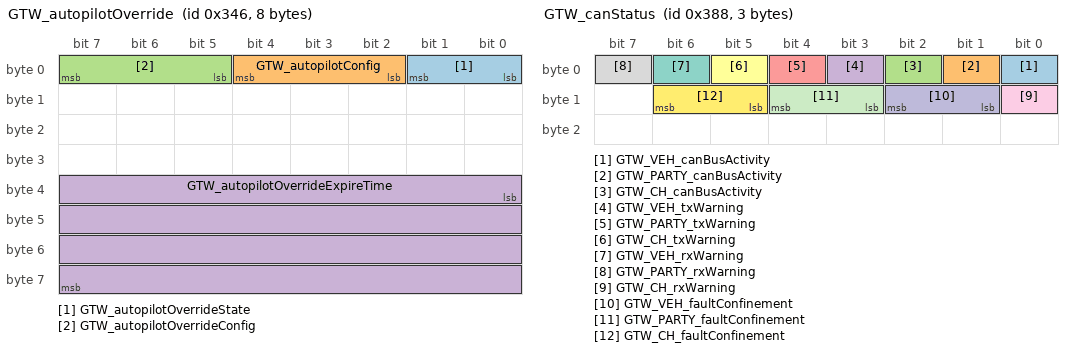
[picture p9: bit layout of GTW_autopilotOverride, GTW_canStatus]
BO_ 838 GTW_autopilotOverride: 8 GTW
 SG_ GTW_autopilotOverrideState : 0|2@1+ (1,0) [0|3] "" Vector__XXX
 SG_ GTW_autopilotConfig : 2|3@1+ (1,0) [0|7] "" Vector__XXX
 SG_ GTW_autopilotOverrideConfig : 5|3@1+ (1,0) [0|7] "" Vector__XXX
 SG_ GTW_autopilotOverrideExpireTime : 32|32@1+ (1,0) [0|4294967295] "" Vector__XXX

BO_ 904 GTW_canStatus: 3 GTW
 SG_ GTW_VEH_canBusActivity : 0|1@1+ (1,0) [0|1] "" Vector__XXX
 SG_ GTW_PARTY_canBusActivity : 1|1@1+ (1,0) [0|1] "" Vector__XXX
 SG_ GTW_CH_canBusActivity : 2|1@1+ (1,0) [0|1] "" Vector__XXX
 SG_ GTW_VEH_txWarning : 3|1@1+ (1,0) [0|1] "" Vector__XXX
 SG_ GTW_PARTY_txWarning : 4|1@1+ (1,0) [0|1] "" Vector__XXX
 SG_ GTW_CH_txWarning : 5|1@1+ (1,0) [0|1] "" Vector__XXX
 SG_ GTW_VEH_rxWarning : 6|1@1+ (1,0) [0|1] "" Vector__XXX
 SG_ GTW_PARTY_rxWarning : 7|1@1+ (1,0) [0|1] "" Vector__XXX
 SG_ GTW_CH_rxWarning : 8|1@1+ (1,0) [0|1] "" Vector__XXX
 SG_ GTW_VEH_faultConfinement : 9|2@1+ (1,0) [0|3] "" Vector__XXX
 SG_ GTW_PARTY_faultConfinement : 11|2@1+ (1,0) [0|3] "" Vector__XXX
 SG_ GTW_CH_faultConfinement : 13|2@1+ (1,0) [0|3] "" Vector__XXX

BO_ 2047 GTW_carConfig: 8 GTW
 SG_ GTW_carConfigMultiplexer M : 0|8@1+ (1,0) [0|255] "" Vector__XXX
 SG_ GTW_deliveryStatus m1 : 8|1@1+ (1,0) [0|1] "" Vector__XXX
 SG_ GTW_cabinPTCHeaterType m1 : 10|1@1+ (1,0) [0|1] "" Vector__XXX
 SG_ GTW_rightHandDrive m1 : 11|1@1+ (1,0) [0|1] "" Vector__XXX
 SG_ GTW_rearLightType m1 : 12|2@1+ (1,0) [0|3] "" Vector__XXX
 SG_ GTW_headlamps m1 : 14|2@1+ (1,0) [0|3] "" Vector__XXX
 SG_ GTW_country m1 : 16|16@1+ (1,0) [0|65535] "" Vector__XXX
 SG_ GTW_tireType m1 : 32|6@1+ (1,0) [0|63] "" Vector__XXX
 SG_ GTW_roofGlassType m1 : 38|2@1+ (1,0) [0|3] "" Vector__XXX
 SG_ GTW_dasHw m1 : 40|3@1+ (1,0) [3|5] "" Vector__XXX
 SG_ GTW_brakeHWType m1 : 43|5@1+ (1,0) [0|31] "" Vector__XXX
 SG_ GTW_restraintsHardwareType m1 : 48|8@1+ (1,0) [0|255] "" Vector__XXX
 SG_ GTW_drivetrainType m1 : 56|4@1+ (1,0) [0|4] "" Vector__XXX
 SG_ GTW_radarHeaterType m1 : 60|3@1+ (1,0) [0|5] "" Vector__XXX
 SG_ GTW_exteriorTrimType m2 : 8|1@1+ (1,0) [0|1] "" Vector__XXX
 SG_ GTW_frontSeatHeaters m2 : 9|1@1+ (1,0) [0|1] "" Vector__XXX
 SG_ GTW_rearSeatHeaters m2 : 10|1@1+ (1,0) [0|1] "" Vector__XXX
 SG_ GTW_eCallAntennaHW m2 : 12|1@1+ (1,0) [0|1] "" Vector__XXX
 SG_ GTW_homelinkType m2 : 13|1@1+ (1,0) [0|1] "" Vector__XXX
 SG_ GTW_vdcType m2 : 14|1@1+ (1,0) [0|1] "" Vector__XXX
 SG_ GTW_memoryMirrors m2 : 17|1@1+ (1,0) [0|1] "" Vector__XXX
 SG_ GTW_powerLiftgateType m2 : 18|2@1+ (1,0) [0|2] "" Vector__XXX
 SG_ GTW_lumbarECUType m2 : 20|4@1+ (1,0) [0|15] "" Vector__XXX
 SG_ GTW_rearSeatHeaterType m2 : 24|2@1+ (1,0) [0|3] "" Vector__XXX
 SG_ GTW_auxParkLamps m2 : 26|2@1+ (1,0) [0|3] "" Vector__XXX
 SG_ GTW_interiorCabinRadarType m2 : 28|1@1+ (1,0) [0|1] "" Vector__XXX
 SG_ GTW_hvacPanelVaneType m2 : 29|1@1+ (1,0) [0|1] "" Vector__XXX
 SG_ GTW_intakeAirFilterType m2 : 30|2@1+ (1,0) [0|2] "" Vector__XXX
 SG_ GTW_eBuckConfig m2 : 32|1@1+ (1,0) [0|1] "" Vector__XXX
 SG_ GTW_steeringHeaterEnabled m2 : 33|1@1+ (1,0) [0|1] "" Vector__XXX
 SG_ GTW_activeHighBeam m2 : 34|1@1+ (1,0) [0|1] "" Vector__XXX
 SG_ GTW_airbagCutoffSwitch m2 : 35|1@1+ (1,0) [0|1] "" Vector__XXX
 SG_ GTW_intrusionSensorType m2 : 36|1@1+ (1,0) [0|1] "" Vector__XXX
 SG_ GTW_spoilerType m2 : 37|1@1+ (1,0) [0|1] "" Vector__XXX
 SG_ GTW_rearFogLamps m2 : 39|1@1+ (1,0) [0|1] "" Vector__XXX
 SG_ GTW_roofType m2 : 40|1@1+ (1,0) [0|1] "" Vector__XXX
 SG_ GTW_thirdRowSeatType m2 : 41|1@1+ (1,0) [0|1] "" Vector__XXX
 SG_ GTW_autopilot m2 : 42|3@1+ (1,0) [0|7] "" Vector__XXX
 SG_ GTW_superchargingAccess m2 : 45|2@1+ (1,0) [0|3] "" Vector__XXX
 SG_ GTW_exteriorColor m2 : 48|5@1+ (1,0) [0|31] "" Vector__XXX
 SG_ GTW_pedestrianWarningSound m2 : 53|2@1+ (1,0) [0|3] "" Vector__XXX
 SG_ GTW_steeringColumnUJointType m2 : 55|1@1+ (1,0) [0|1] "" Vector__XXX
 SG_ GTW_bPillarNFCParam m2 : 56|1@1+ (1,0) [0|1] "" Vector__XXX
 SG_ GTW_interiorLighting m2 : 57|3@1+ (1,0) [0|7] "" Vector__XXX
 SG_ GTW_headlightLevelerType m2 : 60|2@1+ (1,0) [0|3] "" Vector__XXX
 SG_ GTW_numberHVILNodes m2 : 62|2@1+ (1,0) [0|3] "" Vector__XXX
 SG_ GTW_mapRegion m3 : 8|4@1+ (1,0) [0|15] "" Vector__XXX
 SG_ GTW_performancePackage m3 : 12|3@1+ (1,0) [0|7] "" Vector__XXX
 SG_ GTW_chassisType m3 : 18|4@1+ (1,0) [0|15] "" Vector__XXX
 SG_ GTW_airSuspension m3 : 22|2@1+ (1,0) [0|3] "" Vector__XXX
 SG_ GTW_centerConsoleControllerType m3 : 24|2@1+ (1,0) [0|3] "" Vector__XXX
 SG_ GTW_autopilotCameraType m3 : 26|1@1+ (1,0) [0|1] "" Vector__XXX
 SG_ GTW_connectivityPackage m3 : 27|1@1+ (1,0) [0|1] "" Vector__XXX
 SG_ GTW_plcSupportType m3 : 28|2@1+ (1,0) [0|3] "" Vector__XXX
 SG_ GTW_packEnergy m3 : 32|5@1+ (1,0) [0|31] "" Vector__XXX
 SG_ GTW_frontSeatReclinerHardware m3 : 37|2@1+ (1,0) [0|3] "" Vector__XXX
 SG_ GTW_brakeLineSwitchType m3 : 39|1@1+ (1,0) [0|1] "" Vector__XXX
 SG_ GTW_softRange m3 : 42|3@1+ (1,0) [0|7] "" Vector__XXX
 SG_ GTW_refrigerantType m3 : 45|2@1+ (1,0) [0|3] "" Vector__XXX
 SG_ GTW_wheelType m3 : 48|7@1+ (1,0) [0|127] "" Vector__XXX
 SG_ GTW_brakeActuationType m3 : 57|3@1+ (1,0) [0|4] "" Vector__XXX
 SG_ GTW_secondRowSeatType m3 : 60|3@1+ (1,0) [0|7] "" Vector__XXX
 SG_ GTW_secondRowSeatMotorType m3 : 63|1@1+ (1,0) [0|1] "" Vector__XXX
 SG_ GTW_birthday m4 : 8|32@1+ (1,0) [0|4294967295] "" Vector__XXX
 SG_ GTW_eCallEnabled m4 : 40|2@1+ (1,0) [0|3] "" Vector__XXX
 SG_ GTW_parkAssistECUType m4 : 42|2@1+ (1,0) [0|3] "" Vector__XXX
 SG_ GTW_passengerAirbagType m4 : 44|2@1+ (1,0) [0|3] "" Vector__XXX
 SG_ GTW_forwardRadarHw m4 : 46|2@1+ (1,0) [0|2] "" Vector__XXX
 SG_ GTW_frontSeatType m4 : 48|4@1+ (1,0) [0|15] "" Vector__XXX
 SG_ GTW_secondRowDisplayType m4 : 52|1@1+ (1,0) [0|1] "" Vector__XXX
 SG_ GTW_wirelessPhoneChargerType m4 : 53|2@1+ (1,0) [0|3] "" Vector__XXX
 SG_ GTW_ethernetTunerType m4 : 55|2@1+ (1,0) [0|3] "" Vector__XXX
 SG_ GTW_interiorTrimType m4 : 60|4@1+ (1,0) [0|15] "" Vector__XXX
 SG_ GTW_gloveboxUSBType m5 : 8|2@1+ (1,0) [0|3] "" Vector__XXX
 SG_ GTW_coolantPumpType m5 : 10|3@1+ (1,0) [0|7] "" Vector__XXX
 SG_ GTW_epblHwType m5 : 13|4@1+ (1,0) [0|15] "" Vector__XXX
 SG_ GTW_epbrHwType m5 : 17|4@1+ (1,0) [0|15] "" Vector__XXX
 SG_ GTW_blowerMotorType m5 : 21|2@1+ (1,0) [0|3] "" Vector__XXX
 SG_ GTW_frontUsbHubType m5 : 27|3@1+ (1,0) [0|5] "" Vector__XXX
 SG_ GTW_superManifoldType m5 : 30|2@1+ (1,0) [0|3] "" Vector__XXX
 SG_ GTW_rcmLocation m5 : 32|1@1+ (1,0) [0|1] "" Vector__XXX
 SG_ GTW_interiorCamFanType m5 : 33|2@1+ (1,0) [0|3] "" Vector__XXX
 SG_ GTW_sirenType m5 : 37|1@1+ (1,0) [0|1] "" Vector__XXX
 SG_ GTW_hornType m5 : 38|1@1+ (1,0) [0|1] "" Vector__XXX
 SG_ GTW_badgingVersion m5 : 40|1@1+ (1,0) [0|1] "" Vector__XXX
 SG_ GTW_steeringColumnMotorType m5 : 42|2@1+ (1,0) [0|3] "" Vector__XXX
 SG_ GTW_refrigACLineType m5 : 48|2@1+ (1,0) [0|3] "" Vector__XXX
 SG_ GTW_refrigFilterType m5 : 50|2@1+ (1,0) [0|3] "" Vector__XXX
 SG_ GTW_diBurnInType m5 : 52|1@1+ (1,0) [0|1] "" Vector__XXX
 SG_ GTW_specialBadgingType m5 : 53|2@1+ (1,0) [0|3] "" Vector__XXX
 SG_ GTW_chassisSubType m5 : 55|2@1+ (1,0) [0|3] "" Vector__XXX
 SG_ GTW_frontSeatVentilationType m5 : 57|1@1+ (1,0) [0|1] "" Vector__XXX
 SG_ GTW_towPackage m5 : 58|2@1+ (1,0) [0|3] "" Vector__XXX
 SG_ GTW_refrigLccType m5 : 60|1@1+ (1,0) [0|1] "" Vector__XXX
 SG_ GTW_caliperColorType m5 : 62|2@1+ (1,0) [0|3] "" Vector__XXX
 SG_ GTW_wiperMotorType m6 : 9|1@1+ (1,0) [0|1] "" Vector__XXX
 SG_ GTW_frontOverheadConsoleType m6 : 10|2@1+ (1,0) [0|3] "" Vector__XXX
 SG_ GTW_shifterType m6 : 12|1@1+ (1,0) [0|1] "" Vector__XXX
 SG_ GTW_compressorType m6 : 13|4@1+ (1,0) [0|15] "" Vector__XXX
 SG_ GTW_twelveVBatteryType m6 : 17|3@1+ (1,0) [0|7] "" Vector__XXX
 SG_ GTW_efuseSWConfig m6 : 20|3@1+ (1,0) [0|7] "" Vector__XXX
 SG_ GTW_tollCollectionModuleType m6 : 23|1@1+ (1,0) [0|1] "" Vector__XXX
 SG_ GTW_bleEndpointUpdateMethod m6 : 24|1@1+ (1,0) [0|1] "" Vector__XXX
 SG_ GTW_steeringWheelControllerType m6 : 25|3@1+ (1,0) [0|7] "" Vector__XXX
 SG_ GTW_frontSeatVentilationEnabled m6 : 28|1@1+ (1,0) [0|1] "" Vector__XXX
 SG_ GTW_gloveboxActuatorType m6 : 29|2@1+ (1,0) [0|3] "" Vector__XXX
 SG_ GTW_epasType m6 : 32|4@1+ (1,0) [0|11] "" Vector__XXX
 SG_ GTW_homologationRegionOverride m6 : 36|2@1+ (1,0) [0|3] "" Vector__XXX
 SG_ GTW_windowCommandsPermissionType m6 : 38|2@1+ (1,0) [0|3] "" Vector__XXX
 SG_ GTW_rgbInteriorLightingEnabled m6 : 43|2@1+ (1,0) [0|3] "" Vector__XXX
 SG_ GTW_windshieldWiperHeaterType m6 : 45|1@1+ (1,0) [0|1] "" Vector__XXX
 SG_ GTW_driveInterfaceType m6 : 47|1@1+ (1,0) [0|1] "" Vector__XXX
 SG_ GTW_efficiencyPackage m6 : 49|6@1+ (1,0) [0|63] "" Vector__XXX
 SG_ GTW_visorLightType m6 : 55|1@1+ (1,0) [0|1] "" Vector__XXX
 SG_ GTW_gnssAntennaType m6 : 58|2@1+ (1,0) [0|3] "" Vector__XXX
 SG_ GTW_frontSeatHeatersEnabled m6 : 62|1@1+ (1,0) [0|1] "" Vector__XXX
 SG_ GTW_windshieldWiperHeaterEnabled m6 : 63|1@1+ (1,0) [0|1] "" Vector__XXX
 SG_ GTW_tcuType m7 : 8|1@1+ (1,0) [0|1] "" Vector__XXX
 SG_ GTW_fasciaType m7 : 9|4@1+ (1,0) [0|15] "" Vector__XXX
 SG_ GTW_powerSteeringColumn m7 : 13|1@1+ (1,0) [0|1] "" Vector__XXX
 SG_ GTW_frontSeatHeaterType m7 : 14|1@1+ (1,0) [0|1] "" Vector__XXX
 SG_ GTW_softPerformanceLimit m7 : 15|4@1+ (1,0) [0|15] "" Vector__XXX
 SG_ GTW_alcoholInterlockType m7 : 22|1@1+ (1,0) [0|1] "" Vector__XXX
 SG_ GTW_immersiveAudio m7 : 23|2@1+ (1,0) [0|3] "" Vector__XXX
 SG_ GTW_passengerOccupancySensorType m7 : 26|3@1+ (1,0) [0|7] "" Vector__XXX
 SG_ GTW_packPerformanceDeviation m7 : 30|3@1+ (1,0) [0|7] "" Vector__XXX
 SG_ GTW_frontFogLamps m7 : 35|1@1+ (1,0) [0|1] "" Vector__XXX
 SG_ GTW_driverOccupancySensorType m7 : 36|1@1+ (1,0) [0|1] "" Vector__XXX
 SG_ GTW_audioType m7 : 37|3@1+ (1,0) [0|7] "" Vector__XXX
 SG_ GTW_occupancyClassificationFeatu m7 : 42|1@1+ (1,0) [0|1] "" Vector__XXX
 SG_ GTW_domeLightType m7 : 47|2@1+ (1,0) [0|3] "" Vector__XXX
 SG_ GTW_tpmsType m7 : 49|2@1+ (1,0) [0|3] "" Vector__XXX
 SG_ GTW_authenticationEndpointLayout m7 : 52|3@1+ (1,0) [0|6] "" Vector__XXX
 SG_ GTW_socSleepOverride m7 : 57|2@1+ (1,0) [0|3] "" Vector__XXX
 SG_ GTW_r79BehaviorOverride m7 : 59|1@1+ (1,0) [0|1] "" Vector__XXX
 SG_ GTW_steeringHeaterType m7 : 60|3@1+ (1,0) [0|7] "" Vector__XXX
 SG_ GTW_sohRegulatoryStatus m8 : 10|1@1+ (1,0) [0|1] "" Vector__XXX
 SG_ GTW_m3yBusArchitecture m8 : 17|2@1+ (1,0) [0|3] "" Vector__XXX
 SG_ GTW_blindSpotIndicatorLightType m8 : 20|1@1+ (1,0) [0|1] "" Vector__XXX
 SG_ GTW_hvacCaseDoorType m8 : 28|1@1+ (1,0) [0|1] "" Vector__XXX
 SG_ GTW_rduCableType m8 : 31|1@1+ (1,0) [0|1] "" Vector__XXX
 SG_ GTW_interiorCameraType m8 : 39|2@1+ (1,0) [0|2] "" Vector__XXX
 SG_ GTW_frontFasciaCameraType m8 : 41|2@1+ (1,0) [0|3] "" Vector__XXX

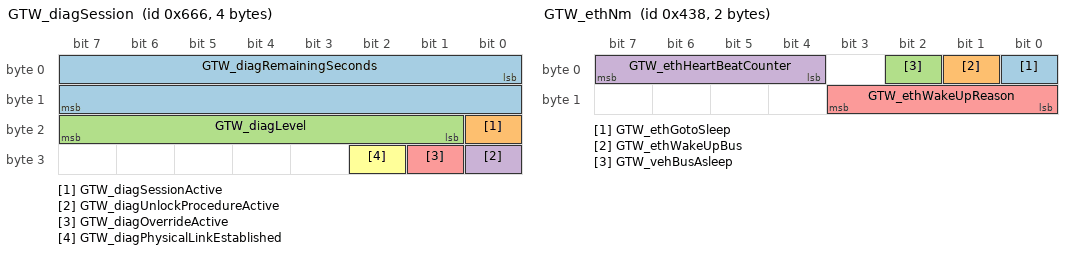
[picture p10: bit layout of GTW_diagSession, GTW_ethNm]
BO_ 1638 GTW_diagSession: 4 GTW
 SG_ GTW_diagRemainingSeconds : 0|16@1+ (1,0) [0|65535] "seconds" Vector__XXX
 SG_ GTW_diagSessionActive : 16|1@1+ (1,0) [0|1] "" Vector__XXX
 SG_ GTW_diagLevel : 17|7@1+ (1,0) [0|127] "" Vector__XXX
 SG_ GTW_diagUnlockProcedureActive : 24|1@1+ (1,0) [0|1] "" Vector__XXX
 SG_ GTW_diagOverrideActive : 25|1@1+ (1,0) [0|1] "" Vector__XXX
 SG_ GTW_diagPhysicalLinkEstablished : 26|1@1+ (1,0) [0|1] "" Vector__XXX

BO_ 1080 GTW_ethNm: 2 GTW
 SG_ GTW_ethGotoSleep : 0|1@1+ (1,0) [0|1] "" Vector__XXX
 SG_ GTW_ethWakeUpBus : 1|1@1+ (1,0) [0|1] "" Vector__XXX
 SG_ GTW_vehBusAsleep : 2|1@1+ (1,0) [0|1] "" Vector__XXX
 SG_ GTW_ethHeartBeatCounter : 4|4@1+ (1,0) [0|15] "" Vector__XXX
 SG_ GTW_ethWakeUpReason : 8|4@1+ (1,0) [0|15] "" Vector__XXX

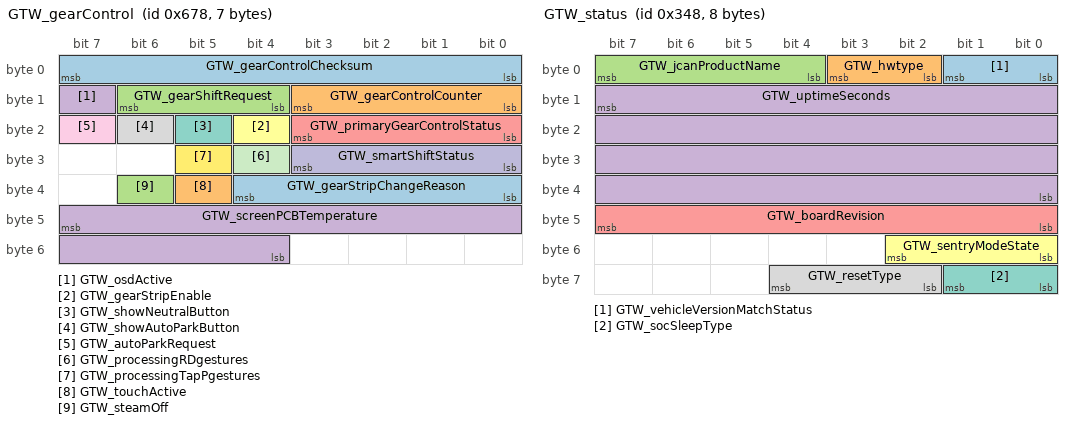
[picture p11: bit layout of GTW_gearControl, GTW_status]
BO_ 1656 GTW_gearControl: 7 GTW
 SG_ GTW_gearControlChecksum : 0|8@1+ (1,0) [0|255] "" Vector__XXX
 SG_ GTW_gearControlCounter : 8|4@1+ (1,0) [0|15] "" Vector__XXX
 SG_ GTW_gearShiftRequest : 12|3@1+ (1,0) [1|7] "" Vector__XXX
 SG_ GTW_osdActive : 15|1@1+ (1,0) [0|1] "" Vector__XXX
 SG_ GTW_primaryGearControlStatus : 16|4@1+ (1,0) [0|15] "" Vector__XXX
 SG_ GTW_gearStripEnable : 20|1@1+ (1,0) [0|1] "" Vector__XXX
 SG_ GTW_showNeutralButton : 21|1@1+ (1,0) [0|1] "" Vector__XXX
 SG_ GTW_showAutoParkButton : 22|1@1+ (1,0) [0|1] "" Vector__XXX
 SG_ GTW_autoParkRequest : 23|1@1+ (1,0) [0|1] "" Vector__XXX
 SG_ GTW_smartShiftStatus : 24|4@1+ (1,0) [1|15] "" Vector__XXX
 SG_ GTW_processingRDgestures : 28|1@1+ (1,0) [0|1] "" Vector__XXX
 SG_ GTW_processingTapPgestures : 29|1@1+ (1,0) [0|1] "" Vector__XXX
 SG_ GTW_gearStripChangeReason : 32|5@1+ (1,0) [1|31] "" Vector__XXX
 SG_ GTW_touchActive : 37|1@1+ (1,0) [0|1] "" Vector__XXX
 SG_ GTW_steamOff : 38|1@1+ (1,0) [0|1] "" Vector__XXX
 SG_ GTW_screenPCBTemperature : 47|12@0- (0.0625,0) [-128|127.875] "degC" Vector__XXX

BO_ 2033 GTW_hrl: 7 GTW
 SG_ GTW_hrlIndex M : 0|2@1+ (1,0) [0|3] "" Vector__XXX
 SG_ GTW_hrlState m2 : 2|1@1+ (1,0) [0|1] "" Vector__XXX
 SG_ GTW_hrlTriggerDuration m2 : 15|16@0+ (1,0) [0|65535] "seconds" Vector__XXX
 SG_ GTW_hrlTriggerType m2 : 24|4@1+ (1,0) [0|15] "" Vector__XXX
 SG_ GTW_hrlTriggerId m2 : 39|16@0+ (1,0) [0|65535] "" Vector__XXX
 SG_ GTW_hrlTriggerBus m2 : 53|3@1+ (1,0) [0|7] "" Vector__XXX

BO_ 60 GTW_info: 8 GTW
 SG_ GTW_infoIndex M : 0|8@1+ (1,0) [0|255] "" Vector__XXX
 SG_ GTW_buildType m10 : 8|3@1+ (1,0) [0|7] "" Vector__XXX
 SG_ GTW_hardwareId m10 : 32|16@1+ (1,0) [0|65535] "" Vector__XXX
 SG_ GTW_platformType m13 : 8|8@1+ (1,0) [0|255] "" Vector__XXX
 SG_ GTW_appCrc m13 : 32|32@1+ (1,0) [0|4294967295] "" Vector__XXX
 SG_ GTW_applicationGitHash m17 : 8|56@1+ (1,0) [0|7.20575940379e+16] "" Vector__XXX
 SG_ GTW_bootGitHash m18 : 8|56@1+ (1,0) [0|7.20575940379e+16] "" Vector__XXX

BO_ 1370 GTW_mismatchFault: 8 GTW
 SG_ GTW_mismatchFaultIndex M : 0|3@1+ (1,0) [0|7] "" Vector__XXX
 SG_ GTW_mismatchFaultChecksum : 3|8@1+ (1,0) [0|255] "" Vector__XXX
 SG_ GTW_mismatchFaultCounter : 11|4@1+ (1,0) [0|15] "" Vector__XXX
 SG_ GTW_GTWmismatchFault m1 : 15|1@1+ (1,0) [0|1] "" Vector__XXX
 SG_ GTW_BMSmismatchFault m1 : 16|1@1+ (1,0) [0|1] "" Vector__XXX
 SG_ GTW_APSmismatchFault m1 : 17|1@1+ (1,0) [0|1] "" Vector__XXX
 SG_ GTW_BLEEPCENTERmismatchFault m1 : 18|1@1+ (1,0) [0|1] "" Vector__XXX
 SG_ GTW_BLEEPLEFTmismatchFault m1 : 19|1@1+ (1,0) [0|1] "" Vector__XXX
 SG_ GTW_BLEEPREARmismatchFault m1 : 20|1@1+ (1,0) [0|1] "" Vector__XXX
 SG_ GTW_BLEEPRIGHTmismatchFault m1 : 21|1@1+ (1,0) [0|1] "" Vector__XXX
 SG_ GTW_CBCmismatchFault m1 : 22|1@1+ (1,0) [0|1] "" Vector__XXX
 SG_ GTW_CMPmismatchFault m1 : 23|1@1+ (1,0) [0|1] "" Vector__XXX
 SG_ GTW_CPmismatchFault m1 : 24|1@1+ (1,0) [0|1] "" Vector__XXX
 SG_ GTW_DIFmismatchFault m1 : 25|1@1+ (1,0) [0|1] "" Vector__XXX
 SG_ GTW_DIRmismatchFault m1 : 26|1@1+ (1,0) [0|1] "" Vector__XXX
 SG_ GTW_EPAS3PmismatchFault m1 : 27|1@1+ (1,0) [0|1] "" Vector__XXX
 SG_ GTW_EPAS3SmismatchFault m1 : 28|1@1+ (1,0) [0|1] "" Vector__XXX
 SG_ GTW_EPBLmismatchFault m1 : 29|1@1+ (1,0) [0|1] "" Vector__XXX
 SG_ GTW_EPBRmismatchFault m1 : 30|1@1+ (1,0) [0|1] "" Vector__XXX
 SG_ GTW_ESPCALmismatchFault m1 : 31|1@1+ (1,0) [0|1] "" Vector__XXX
 SG_ GTW_ESPmismatchFault m1 : 32|1@1+ (1,0) [0|1] "" Vector__XXX
 SG_ GTW_HCM3LmismatchFault m1 : 33|1@1+ (1,0) [0|1] "" Vector__XXX
 SG_ GTW_HCM3RmismatchFault m1 : 34|1@1+ (1,0) [0|1] "" Vector__XXX
 SG_ GTW_HCMLmismatchFault m1 : 35|1@1+ (1,0) [0|1] "" Vector__XXX
 SG_ GTW_HCMRmismatchFault m1 : 36|1@1+ (1,0) [0|1] "" Vector__XXX
 SG_ GTW_HVPmismatchFault m1 : 37|1@1+ (1,0) [0|1] "" Vector__XXX
 SG_ GTW_IBSTCALmismatchFault m1 : 38|1@1+ (1,0) [0|1] "" Vector__XXX
 SG_ GTW_IBSTmismatchFault m1 : 39|1@1+ (1,0) [0|1] "" Vector__XXX
 SG_ GTW_LVBMSmismatchFault m1 : 40|1@1+ (1,0) [0|1] "" Vector__XXX
 SG_ GTW_OCS1PmismatchFault m1 : 41|1@1+ (1,0) [0|1] "" Vector__XXX
 SG_ GTW_OPCFmismatchFault m1 : 42|1@1+ (1,0) [0|1] "" Vector__XXX
 SG_ GTW_OPCRmismatchFault m1 : 43|1@1+ (1,0) [0|1] "" Vector__XXX
 SG_ GTW_PARKmismatchFault m1 : 44|1@1+ (1,0) [0|1] "" Vector__XXX
 SG_ GTW_PCSCPU2mismatchFault m1 : 45|1@1+ (1,0) [0|1] "" Vector__XXX
 SG_ GTW_PCSmismatchFault m1 : 46|1@1+ (1,0) [0|1] "" Vector__XXX
 SG_ GTW_PMFmismatchFault m1 : 47|1@1+ (1,0) [0|1] "" Vector__XXX
 SG_ GTW_PMRmismatchFault m1 : 48|1@1+ (1,0) [0|1] "" Vector__XXX
 SG_ GTW_PTCmismatchFault m1 : 49|1@1+ (1,0) [0|1] "" Vector__XXX
 SG_ GTW_RCMCALmismatchFault m1 : 50|1@1+ (1,0) [0|1] "" Vector__XXX
 SG_ GTW_RCMmismatchFault m1 : 51|1@1+ (1,0) [0|1] "" Vector__XXX
 SG_ GTW_SCCMmismatchFault m1 : 52|1@1+ (1,0) [0|1] "" Vector__XXX
 SG_ GTW_SDCRmismatchFault m1 : 53|1@1+ (1,0) [0|1] "" Vector__XXX
 SG_ GTW_SWCmismatchFault m1 : 54|1@1+ (1,0) [0|1] "" Vector__XXX
 SG_ GTW_THSmismatchFault m1 : 55|1@1+ (1,0) [0|1] "" Vector__XXX
 SG_ GTW_VCFRONTmismatchFault m1 : 56|1@1+ (1,0) [0|1] "" Vector__XXX
 SG_ GTW_VCLEFTmismatchFault m1 : 57|1@1+ (1,0) [0|1] "" Vector__XXX
 SG_ GTW_VCRIGHTmismatchFault m1 : 58|1@1+ (1,0) [0|1] "" Vector__XXX
 SG_ GTW_VCSECmismatchFault m1 : 59|1@1+ (1,0) [0|1] "" Vector__XXX
 SG_ GTW_PMmismatchFault m1 : 60|1@1+ (1,0) [0|1] "" Vector__XXX

BO_ 840 GTW_status: 8 GTW
 SG_ GTW_vehicleVersionMatchStatus : 0|2@1+ (1,0) [0|3] "" Vector__XXX
 SG_ GTW_hwtype : 2|2@1+ (1,0) [1|3] "" Vector__XXX
 SG_ GTW_jcanProductName : 4|4@1+ (1,0) [1|15] "" Vector__XXX
 SG_ GTW_uptimeSeconds : 15|32@0+ (1,0) [0|4294967295] "s" Vector__XXX
 SG_ GTW_boardRevision : 40|8@1+ (1,0) [0|255] "" Vector__XXX
 SG_ GTW_sentryModeState : 48|3@1+ (1,0) [0|7] "" Vector__XXX
 SG_ GTW_socSleepType : 56|2@1+ (1,0) [1|3] "" Vector__XXX
 SG_ GTW_resetType : 58|3@1+ (1,0) [1|7] "" Vector__XXX

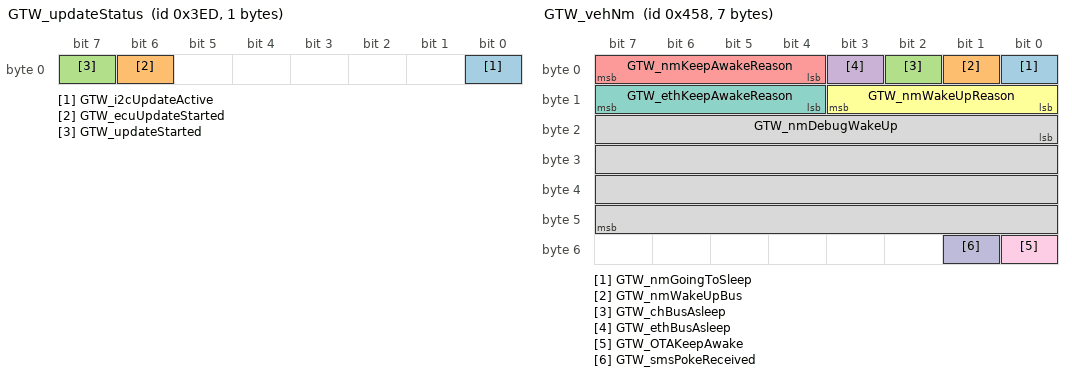
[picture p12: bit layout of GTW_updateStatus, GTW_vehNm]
BO_ 1005 GTW_updateStatus: 1 GTW
 SG_ GTW_i2cUpdateActive : 0|1@1+ (1,0) [0|1] "" Vector__XXX
 SG_ GTW_ecuUpdateStarted : 6|1@1+ (1,0) [0|1] "" Vector__XXX
 SG_ GTW_updateStarted : 7|1@1+ (1,0) [0|1] "" Vector__XXX

BO_ 1112 GTW_vehNm: 7 GTW
 SG_ GTW_nmGoingToSleep : 0|1@1+ (1,0) [0|1] "" Vector__XXX
 SG_ GTW_nmWakeUpBus : 1|1@1+ (1,0) [0|1] "" Vector__XXX
 SG_ GTW_chBusAsleep : 2|1@1+ (1,0) [0|1] "" Vector__XXX
 SG_ GTW_ethBusAsleep : 3|1@1+ (1,0) [0|1] "" Vector__XXX
 SG_ GTW_nmKeepAwakeReason : 4|4@1+ (1,0) [1|15] "" Vector__XXX
 SG_ GTW_nmWakeUpReason : 8|4@1+ (1,0) [0|15] "" Vector__XXX
 SG_ GTW_ethKeepAwakeReason : 12|4@1+ (1,0) [1|15] "" Vector__XXX
 SG_ GTW_nmDebugWakeUp : 16|32@1+ (1,0) [0|4294967295] "" Vector__XXX
 SG_ GTW_OTAKeepAwake : 48|1@1+ (1,0) [0|1] "" Vector__XXX
 SG_ GTW_smsPokeReceived : 49|1@1+ (1,0) [0|1] "" Vector__XXX

BO_TX_BU_ 634 : DIF;
BO_TX_BU_ 1622 : DIF;
BO_TX_BU_ 421 : DIF;
BO_TX_BU_ 725 : DIF;
BO_TX_BU_ 886 : DIF;
BO_TX_BU_ 390 : DIF;
BO_TX_BU_ 633 : DIR;
BO_TX_BU_ 821 : DIR;
BO_TX_BU_ 2039 : DIR;
BO_TX_BU_ 598 : DIR;
BO_TX_BU_ 789 : DIR;
BO_TX_BU_ 264 : DIR;
BO_TX_BU_ 1861 : DI;
BO_TX_BU_ 694 : DI;
BO_TX_BU_ 1866 : DI;
BO_TX_BU_ 1623 : DI;
BO_TX_BU_ 1270 : DI;
BO_TX_BU_ 822 : DI;
BO_TX_BU_ 950 : DI;
BO_TX_BU_ 599 : DI;
BO_TX_BU_ 296 : DI;
BO_TX_BU_ 280 : DI;
BO_TX_BU_ 883 : EPAS3P;
BO_TX_BU_ 882 : EPAS3S;
BO_TX_BU_ 681 : EPBL;
BO_TX_BU_ 742 : EPBR;
BO_TX_BU_ 744 : EPBR;
BO_TX_BU_ 888 : GTW;
BO_TX_BU_ 282 : GTW;
BO_TX_BU_ 838 : GTW;
BO_TX_BU_ 904 : GTW;
BO_TX_BU_ 2047 : GTW;
BO_TX_BU_ 1638 : GTW;
BO_TX_BU_ 1080 : GTW;
BO_TX_BU_ 1656 : GTW;
BO_TX_BU_ 2033 : GTW;
BO_TX_BU_ 60 : GTW;
BO_TX_BU_ 1370 : GTW;
BO_TX_BU_ 840 : GTW;
BO_TX_BU_ 1005 : GTW;
BO_TX_BU_ 1112 : GTW;
CM_ BO_ 634 "Front drive inverter message: hv status";
CM_ SG_ 634 DIF_hvStatusChecksum "Front drive inverter: hv status checksum";
CM_ SG_ 634 DIF_hvStatusCounter "Front drive inverter: hv status counter";
CM_ SG_ 634 DIF_hvilCurrent "HVIL Current";
CM_ SG_ 634 DIF_hvilCmVoltage "HVIL Common Mode Voltage";
CM_ SG_ 634 DIF_hvilStatus "Aggregated hardware and measured HVIL unit status; raw 3 = signal not available (SNA)";
CM_ SG_ 634 DIF_hvilSupplyState "Front drive inverter: hvil supply state";
CM_ SG_ 634 DIF_activeDischargeCtrl "Front drive inverter: active discharge ctrl";
CM_ SG_ 634 DIF_activeDischargeStatus "Active discharge status from HVIL_FAULT signal.";
CM_ SG_ 634 DIF_vBat "Reports the battery voltage measured by the Drive Inverter's local Analog to Digital Converter (ADC).";
CM_ SG_ 634 DIF_vBatQF "Front drive inverter: v bat QF";
CM_ SG_ 634 DIF_powerStageSafeState "Front drive inverter: power stage safe state";
CM_ SG_ 634 DIF_fluxState "Front drive inverter: flux state";
CM_ SG_ 634 DIF_vBusDiag "Front drive inverter: v bus diag";
CM_ SG_ 634 DIF_gateDriveState "Front drive inverter: gate drive state";
CM_ BO_ 1622 "Front drive inverter message: info";
CM_ SG_ 1622 DIF_infoIndex "Front drive inverter: info index";
CM_ SG_ 1622 DIF_buildType "Front drive inverter: build type";
CM_ SG_ 1622 DIF_buildConfigurationId "Front drive inverter: build configuration id";
CM_ SG_ 1622 DIF_hardwareId "Front drive inverter: hardware id";
CM_ SG_ 1622 DIF_componentId "Front drive inverter: component id";
CM_ SG_ 1622 DIF_pcbaId "Front drive inverter: pcba id";
CM_ SG_ 1622 DIF_assemblyId "Front drive inverter: assembly id";
CM_ SG_ 1622 DIF_usageId "Front drive inverter: usage id";
CM_ SG_ 1622 DIF_subUsageId "Front drive inverter: sub usage id";
CM_ SG_ 1622 DIF_motorType "Front drive inverter: motor type; raw 0 = signal not available (SNA)";
CM_ SG_ 1622 DIF_siliconType "Front drive inverter: silicon type";
CM_ SG_ 1622 DIF_mechSafeStateType "Front drive inverter: mech safe state type; raw 0 = signal not available (SNA)";
CM_ SG_ 1622 DIF_applicationCrc "Front drive inverter: application crc";
CM_ SG_ 1622 DIF_oilPumpBuildType "Front drive inverter: oil pump build type";
CM_ SG_ 1622 DIF_oilPumpAppCrc "Front drive inverter: oil pump app crc";
CM_ SG_ 1622 DIF_FPGA_version "Front drive inverter: FPGA version; raw 255 = signal not available (SNA)";
CM_ SG_ 1622 DIF_appGitHash "Front drive inverter: app git hash";
CM_ SG_ 1622 DIF_bootGitHash "Front drive inverter: boot git hash";
CM_ SG_ 1622 DIF_platformTyp "Front drive inverter: platform typ";
CM_ SG_ 1622 DIF_infoBootLdUdsProtocolVersion "Front drive inverter: info boot ld uds protocol version";
CM_ SG_ 1622 DIF_bootloaderCrc "Front drive inverter: bootloader crc";
CM_ SG_ 1622 DIF_oilPumpPcbaId "Front drive inverter: oil pump pcba id";
CM_ SG_ 1622 DIF_oilPumpAssemblyId "Front drive inverter: oil pump assembly id";
CM_ SG_ 1622 DIF_oilPumpUsageId "Front drive inverter: oil pump usage id";
CM_ SG_ 1622 DIF_refRotorFlux "Front drive inverter: ref rotor flux";
CM_ SG_ 1622 DIF_refRotorOffset "Front drive inverter: ref rotor offset; raw 2048 = signal not available (SNA)";
CM_ SG_ 1622 DIF_speedWearTotal "Front drive inverter: speed wear total; raw 255 = signal not available (SNA)";
CM_ SG_ 1622 DIF_torqueWearTotal "Front drive inverter: torque wear total; raw 255 = signal not available (SNA)";
CM_ BO_ 421 "Front drive inverter message: motor status";
CM_ SG_ 421 DIF_motorCurrent "Drive Inverer measured motor RMS phase current.";
CM_ SG_ 421 DIF_switchingFrequency "Front drive inverter: switching frequency";
CM_ SG_ 421 DIF_targetFluxMode "Front drive inverter: target flux mode";
CM_ SG_ 421 DIF_switchShortTestRetryCount "Front drive inverter: switch short test retry count";
CM_ BO_ 725 "Front drive inverter message: status";
CM_ SG_ 725 DIF_statusChecksum "Front drive inverter: status checksum";
CM_ SG_ 725 DIF_statusCounter "Front drive inverter: status counter";
CM_ SG_ 725 DIF_state "DI unit state machine state.";
CM_ SG_ 725 DIF_keepAliveRequest "Used to detect that the Drive Inverter (DI) expects 12V and High Voltage (HV) to be kept up in order to protect hardware.";
CM_ SG_ 725 DIF_soptState "Detects the state of the the Switch Off Path Test (SOPT); raw 8 = signal not available (SNA)";
CM_ SG_ 725 DIF_sysLimpRequest "Front drive inverter: sys limp request";
CM_ SG_ 725 DIF_adState "Front drive inverter: ad state";
CM_ SG_ 725 DIF_driveModeState "Reports the system drive mode state.";
CM_ SG_ 725 DIF_lvSupplyV "Front drive inverter: lv supply v";
CM_ SG_ 725 DIF_wasteState "Reports the Drive Inverter (DI) waste heat state.";
CM_ SG_ 725 DIF_haltRequest "Front drive inverter: halt request";
CM_ SG_ 725 DIF_axleSpeedLimitRequest "Front drive inverter: axle speed limit request";
CM_ SG_ 725 DIF_adDirection "Front drive inverter: ad direction";
CM_ SG_ 725 DIF_spinDownLearningState "Front drive inverter: spin down learning state";
CM_ SG_ 725 DIF_spinDownLearningMode "Front drive inverter: spin down learning mode";
CM_ BO_ 886 "Front drive inverter message: temperature";
CM_ SG_ 886 DIF_tempIndex "Front drive inverter: temp index";
CM_ SG_ 886 DIF_inverterTQF "Detects the Drive Inverter (DI) outlet temperature qualifier.";
CM_ SG_ 886 DIF_pcbT "Front drive inverter: pcb t; raw 0 = signal not available (SNA)";
CM_ SG_ 886 DIF_inverterT "Drive Inverter measured outlet temperature";
CM_ SG_ 886 DIF_statorT "Drive Inverter measured stator temperature; raw 0 = signal not available (SNA)";
CM_ SG_ 886 DIF_dcCapT "Front drive inverter: dc cap t; raw 0 = signal not available (SNA)";
CM_ SG_ 886 DIF_heatsinkT "Drive Inverter measured heatsink temperature; raw 0 = signal not available (SNA)";
CM_ SG_ 886 DIF_inverterTpct "Front drive inverter: inverter tpct";
CM_ SG_ 886 DIF_statorTpct "Front drive inverter: stator tpct";
CM_ SG_ 886 DIF_fluidInTemp "Inlet fluid temperature; raw 0 = signal not available (SNA)";
CM_ SG_ 886 DIF_normalFetBurnIn "Front drive inverter: normal fet burn in; raw 65535 = signal not available (SNA)";
CM_ SG_ 886 DIF_additionalFetBurnIn "Front drive inverter: additional fet burn in; raw 65535 = signal not available (SNA)";
CM_ SG_ 886 DIF_currentWeibullMiles "Front drive inverter: current weibull miles; raw 32767 = signal not available (SNA)";
CM_ SG_ 886 DIF_endOfServiceWeibullMiles "Front drive inverter: end of service weibull miles; raw 32767 = signal not available (SNA)";
CM_ SG_ 886 DIF_burnInDamageRatio "Front drive inverter: burn in damage ratio; raw 511 = signal not available (SNA)";
CM_ SG_ 886 DIF_inverterSensorEst "Front drive inverter: inverter sensor est";
CM_ SG_ 886 DIF_inverterHS1Est "Front drive inverter: inverter HS1 est";
CM_ SG_ 886 DIF_initialBurnInVehicleOdometer "Front drive inverter: initial burn in vehicle odometer; raw 4294967295 = signal not available (SNA)";
CM_ SG_ 886 DIF_inverterHS2Est "Front drive inverter: inverter HS2 est";
CM_ SG_ 886 DIF_inverterInletEst "Front drive inverter: inverter inlet est";
CM_ BO_ 390 "Front drive inverter message: torque";
CM_ SG_ 390 DIF_torqueChecksum "Front drive inverter: torque checksum";
CM_ SG_ 390 DIF_torqueCounter "Front drive inverter: torque counter";
CM_ SG_ 390 DIF_torqueCommand "Torque commanded to the drive unit, referred to the axle/wheel; raw 4096 = signal not available (SNA)";
CM_ SG_ 390 DIF_axleSpeedQF "Front drive inverter: axle speed QF";
CM_ SG_ 390 DIF_torqueActual "Actual torque the drive unit is controlling to referred to the axle/wheel; raw 4096 = signal not available (SNA)";
CM_ SG_ 390 DIF_axleSpeed "Drive Inverter motor speed normalized at axle level; raw 32768 = signal not available (SNA)";
CM_ SG_ 390 DIF_axleTorqueQF "Front drive inverter: axle torque QF";
CM_ SG_ 390 DIF_axlePowerCalcQF "Front drive inverter: axle power calc QF";
CM_ BO_ 633 "Rear drive inverter message: hv status";
CM_ SG_ 633 DIR_hvStatusChecksum "Rear drive inverter: hv status checksum";
CM_ SG_ 633 DIR_hvStatusCounter "Rear drive inverter: hv status counter";
CM_ SG_ 633 DIR_hvilCurrent "HVIL Current";
CM_ SG_ 633 DIR_hvilCmVoltage "HVIL Common Mode Voltage";
CM_ SG_ 633 DIR_hvilStatus "Aggregated hardware and measured HVIL unit status; raw 3 = signal not available (SNA)";
CM_ SG_ 633 DIR_hvilSupplyState "Rear drive inverter: hvil supply state";
CM_ SG_ 633 DIR_activeDischargeCtrl "Rear drive inverter: active discharge ctrl";
CM_ SG_ 633 DIR_activeDischargeStatus "Active discharge status from HVIL_FAULT signal.";
CM_ SG_ 633 DIR_vBat "Reports the battery voltage measured by the Drive Inverter's local Analog to Digital Converter (ADC).";
CM_ SG_ 633 DIR_vBatQF "Rear drive inverter: v bat QF";
CM_ SG_ 633 DIR_powerStageSafeState "Rear drive inverter: power stage safe state";
CM_ SG_ 633 DIR_fluxState "Rear drive inverter: flux state";
CM_ SG_ 633 DIR_vBusDiag "Rear drive inverter: v bus diag";
CM_ SG_ 633 DIR_gateDriveState "Rear drive inverter: gate drive state";
CM_ BO_ 821 "Rear drive inverter message: info";
CM_ SG_ 821 DIR_infoIndex "Rear drive inverter: info index";
CM_ SG_ 821 DIR_buildType "Rear drive inverter: build type";
CM_ SG_ 821 DIR_buildConfigurationId "Rear drive inverter: build configuration id";
CM_ SG_ 821 DIR_hardwareId "Rear drive inverter: hardware id";
CM_ SG_ 821 DIR_componentId "Rear drive inverter: component id";
CM_ SG_ 821 DIR_pcbaId "Rear drive inverter: pcba id";
CM_ SG_ 821 DIR_assemblyId "Rear drive inverter: assembly id";
CM_ SG_ 821 DIR_usageId "Rear drive inverter: usage id";
CM_ SG_ 821 DIR_subUsageId "Rear drive inverter: sub usage id";
CM_ SG_ 821 DIR_motorType "Rear drive inverter: motor type; raw 0 = signal not available (SNA)";
CM_ SG_ 821 DIR_siliconType "Rear drive inverter: silicon type";
CM_ SG_ 821 DIR_mechSafeStateType "Rear drive inverter: mech safe state type; raw 0 = signal not available (SNA)";
CM_ SG_ 821 DIR_applicationCrc "Rear drive inverter: application crc";
CM_ SG_ 821 DIR_oilPumpBuildType "Rear drive inverter: oil pump build type";
CM_ SG_ 821 DIR_oilPumpAppCrc "Rear drive inverter: oil pump app crc";
CM_ SG_ 821 DIR_FPGA_version "Rear drive inverter: FPGA version; raw 255 = signal not available (SNA)";
CM_ SG_ 821 DIR_bootGitHash "Rear drive inverter: boot git hash";
CM_ SG_ 821 DIR_infoBootLdUdsProtocolVersion "Rear drive inverter: info boot ld uds protocol version";
CM_ SG_ 821 DIR_bootloaderCrc "Rear drive inverter: bootloader crc";
CM_ SG_ 821 DIR_oilPumpPcbaId "Rear drive inverter: oil pump pcba id";
CM_ SG_ 821 DIR_oilPumpAssemblyId "Rear drive inverter: oil pump assembly id";
CM_ SG_ 821 DIR_oilPumpUsageId "Rear drive inverter: oil pump usage id";
CM_ SG_ 821 DIR_refRotorFlux "Rear drive inverter: ref rotor flux";
CM_ SG_ 821 DIR_refRotorOffset "Rear drive inverter: ref rotor offset; raw 2048 = signal not available (SNA)";
CM_ SG_ 821 DIR_speedWearTotal "Rear drive inverter: speed wear total; raw 255 = signal not available (SNA)";
CM_ SG_ 821 DIR_torqueWearTotal "Rear drive inverter: torque wear total; raw 255 = signal not available (SNA)";
CM_ BO_ 2039 "Rear drive inverter message: motor status";
CM_ SG_ 2039 DIR_motorCurrent "Drive Inverer measured motor RMS phase current.";
CM_ SG_ 2039 DIR_switchingFrequency "Rear drive inverter: switching frequency";
CM_ SG_ 2039 DIR_targetFluxMode "Rear drive inverter: target flux mode";
CM_ SG_ 2039 DIR_switchShortTestRetryCount "Rear drive inverter: switch short test retry count";
CM_ BO_ 598 "Rear drive inverter message: status";
CM_ SG_ 598 DIR_statusChecksum "Rear drive inverter: status checksum";
CM_ SG_ 598 DIR_statusCounter "Rear drive inverter: status counter";
CM_ SG_ 598 DIR_state "DI unit state machine state.";
CM_ SG_ 598 DIR_keepAliveRequest "Used to detect that the Drive Inverter (DI) expects 12V and High Voltage (HV) to be kept up in order to protect hardware.";
CM_ SG_ 598 DIR_soptState "Detects the state of the the Switch Off Path Test (SOPT); raw 8 = signal not available (SNA)";
CM_ SG_ 598 DIR_sysLimpRequest "Rear drive inverter: sys limp request";
CM_ SG_ 598 DIR_adState "Rear drive inverter: ad state";
CM_ SG_ 598 DIR_driveModeState "Rear drive inverter: drive mode state";
CM_ SG_ 598 DIR_lvSupplyV "Rear drive inverter: lv supply v";
CM_ SG_ 598 DIR_wasteState "Reports the Drive Inverter (DI) waste heat state.";
CM_ SG_ 598 DIR_haltRequest "Rear drive inverter: halt request";
CM_ SG_ 598 DIR_axleSpeedLimitRequest "Rear drive inverter: axle speed limit request";
CM_ SG_ 598 DIR_adDirection "Rear drive inverter: ad direction";
CM_ SG_ 598 DIR_spinDownLearningState "Rear drive inverter: spin down learning state";
CM_ SG_ 598 DIR_spinDownLearningMode "Rear drive inverter: spin down learning mode";
CM_ BO_ 789 "Rear drive inverter message: temperature";
CM_ SG_ 789 DIR_tempIndex "Rear drive inverter: temp index";
CM_ SG_ 789 DIR_inverterTQF "Detects the Drive Inverter (DI) outlet temperature qualifier.";
CM_ SG_ 789 DIR_pcbT "Rear drive inverter: pcb t; raw 0 = signal not available (SNA)";
CM_ SG_ 789 DIR_inverterT "Drive Inverter measured outlet temperature";
CM_ SG_ 789 DIR_statorT "Drive Inverter measured stator temperature; raw 0 = signal not available (SNA)";
CM_ SG_ 789 DIR_dcCapT "Rear drive inverter: dc cap t; raw 0 = signal not available (SNA)";
CM_ SG_ 789 DIR_heatsinkT "Drive Inverter measured heatsink temperature; raw 0 = signal not available (SNA)";
CM_ SG_ 789 DIR_inverterTpct "Rear drive inverter: inverter tpct";
CM_ SG_ 789 DIR_statorTpct "Rear drive inverter: stator tpct";
CM_ SG_ 789 DIR_fluidInTemp "Inlet fluid temperature; raw 0 = signal not available (SNA)";
CM_ SG_ 789 DIR_normalFetBurnIn "Rear drive inverter: normal fet burn in; raw 65535 = signal not available (SNA)";
CM_ SG_ 789 DIR_additionalFetBurnIn "Rear drive inverter: additional fet burn in; raw 65535 = signal not available (SNA)";
CM_ SG_ 789 DIR_currentWeibullMiles "Rear drive inverter: current weibull miles; raw 32767 = signal not available (SNA)";
CM_ SG_ 789 DIR_endOfServiceWeibullMiles "Rear drive inverter: end of service weibull miles; raw 32767 = signal not available (SNA)";
CM_ SG_ 789 DIR_burnInDamageRatio "Rear drive inverter: burn in damage ratio; raw 511 = signal not available (SNA)";
CM_ SG_ 789 DIR_inverterSensorEst "Rear drive inverter: inverter sensor est";
CM_ SG_ 789 DIR_inverterHS1Est "Rear drive inverter: inverter HS1 est";
CM_ SG_ 789 DIR_initialBurnInVehicleOdometer "Rear drive inverter: initial burn in vehicle odometer; raw 4294967295 = signal not available (SNA)";
CM_ SG_ 789 DIR_inverterHS2Est "Rear drive inverter: inverter HS2 est";
CM_ SG_ 789 DIR_inverterInletEst "Rear drive inverter: inverter inlet est";
CM_ BO_ 264 "Rear drive inverter message: torque";
CM_ SG_ 264 DIR_torqueChecksum "Rear drive inverter: torque checksum";
CM_ SG_ 264 DIR_torqueCounter "Rear drive inverter: torque counter";
CM_ SG_ 264 DIR_torqueCommand "Torque commanded to the drive unit, referred to the axle/wheel; raw 4096 = signal not available (SNA)";
CM_ SG_ 264 DIR_axleSpeedQF "Rear drive inverter: axle speed QF";
CM_ SG_ 264 DIR_torqueActual "Actual torque the drive unit is controlling to referred to the axle/wheel; raw 4096 = signal not available (SNA)";
CM_ SG_ 264 DIR_axleSpeed "Drive Inverter motor speed normalized at axle level; raw 32768 = signal not available (SNA)";
CM_ SG_ 264 DIR_axleTorqueQF "Rear drive inverter: axle torque QF";
CM_ SG_ 264 DIR_axlePowerCalcQF "Rear drive inverter: axle power calc QF";
CM_ BO_ 1861 "Drive inverter message: chassis control2";
CM_ SG_ 1861 DI_gradeAngle "Reports the grade angle.";
CM_ SG_ 1861 DI_bankAngle "Reports the bank angle.";
CM_ SG_ 1861 DI_chassisControlVideoRequest "Drive inverter: chassis control video request";
CM_ SG_ 1861 DI_tireUtilizationRatioFrL "Drive inverter: tire utilization ratio fr l";
CM_ SG_ 1861 DI_tireUtilizationRatioFrR "Drive inverter: tire utilization ratio fr r";
CM_ SG_ 1861 DI_tireUtilizationRatioReL "Drive inverter: tire utilization ratio re l";
CM_ SG_ 1861 DI_tireUtilizationRatioReR "Drive inverter: tire utilization ratio re r";
CM_ SG_ 1861 DI_counterSteerTarget "Drive inverter: counter steer target";
CM_ SG_ 1861 DI_splitMuProbability "Drive inverter: split mu probability";
CM_ SG_ 1861 DI_mzError "Drive inverter: mz error";
CM_ SG_ 1861 DI_slipDifferenceFrontRear "Drive inverter: slip difference front rear";
CM_ SG_ 1861 DI_highFreqYawRate "Drive inverter: high freq yaw rate";
CM_ SG_ 1861 DI_turnDirection "Drive inverter: turn direction";
CM_ SG_ 1861 DI_absolutePreControlRequest "Drive inverter: absolute pre control request";
CM_ SG_ 1861 DI_oppositeBuildDirFrontAxle "Drive inverter: opposite build dir front axle";
CM_ SG_ 1861 DI_oppositeBuildDirRearAxle "Drive inverter: opposite build dir rear axle";
CM_ SG_ 1861 DI_saturatedEffectiveness "Drive inverter: saturated effectiveness";
CM_ SG_ 1861 DI_driverPanicIndex "Drive inverter: driver panic index";
CM_ SG_ 1861 DI_learnDownMu "Drive inverter: learn down mu";
CM_ SG_ 1861 DI_preControlOpposingTurnDir "Drive inverter: pre control opposing turn dir";
CM_ SG_ 1861 DI_driverFxError "Drive inverter: driver fx error";
CM_ SG_ 1861 DI_targetSaturation "Drive inverter: target saturation";
CM_ BO_ 694 "Drive inverter message: chassis control status";
CM_ SG_ 694 DI_vdcTelltaleFlash "Request to flash telltale in UI when VDC is active";
CM_ SG_ 694 DI_vdcTelltaleOn "Request to turn telltale ON in UI when VDC is faulted";
CM_ SG_ 694 DI_tcTelltaleFlash "Request to flash telltale in UI when TC is active";
CM_ SG_ 694 DI_tcTelltaleOn "Request to turn telltale ON in UI when TC is faulted";
CM_ SG_ 694 DI_tractionControlModeUI "Drive inverter: traction control mode UI";
CM_ SG_ 694 DI_ptcStateGlobalUI "Drive inverter: ptc state global UI; raw 3 = signal not available (SNA)";
CM_ SG_ 694 DI_btcStateUI "Drive inverter: btc state UI";
CM_ SG_ 694 DI_vehicleHoldTelltaleOn "Drive inverter: vehicle hold telltale on";
CM_ SG_ 694 DI_opdFeedbackReset "Drive inverter: opd feedback reset";
CM_ SG_ 694 DI_opdFeedbackResetPositiveSpeed "Drive inverter: opd feedback reset positive speeds";
CM_ SG_ 694 DI_slipperySurfaceOnUI "Drive inverter: slippery surface on UI";
CM_ SG_ 694 DI_yellowBrakeTelltaleOn "Request to turn yellow BRAKE telltale ON in UI";
CM_ SG_ 694 DI_greenABSTelltaleOn "Drive inverter: green ABS telltale on";
CM_ BO_ 1866 "Drive inverter message: estimated brake temp";
CM_ SG_ 1866 DI_estimatedBrakeTempChecksum "Drive inverter: estimated brake temp checksum";
CM_ SG_ 1866 DI_estimatedBrakeTempCounter "Drive inverter: estimated brake temp counter";
CM_ SG_ 1866 DI_brakeFLTemp "Drive inverter: brake FL temp; raw 1023 = signal not available (SNA)";
CM_ SG_ 1866 DI_brakeFRTemp "Drive inverter: brake FR temp; raw 1023 = signal not available (SNA)";
CM_ SG_ 1866 DI_brakeRLTemp "Drive inverter: brake RL temp; raw 1023 = signal not available (SNA)";
CM_ SG_ 1866 DI_brakeRRTemp "Drive inverter: brake RR temp; raw 1023 = signal not available (SNA)";
CM_ BO_ 1623 "Drive inverter message: info";
CM_ SG_ 1623 DI_infoIndex "Drive inverter: info index";
CM_ SG_ 1623 DI_buildType "Drive inverter: build type";
CM_ SG_ 1623 DI_buildConfigurationId "Drive inverter: build configuration id";
CM_ SG_ 1623 DI_hardwareId "Drive inverter: hardware id";
CM_ SG_ 1623 DI_componentId "Drive inverter: component id";
CM_ SG_ 1623 DI_pcbaId "Drive inverter: pcba id";
CM_ SG_ 1623 DI_assemblyId "Drive inverter: assembly id";
CM_ SG_ 1623 DI_usageId "Drive inverter: usage id";
CM_ SG_ 1623 DI_subUsageId "Drive inverter: sub usage id";
CM_ SG_ 1623 DI_applicationCrc "Drive inverter: application crc";
CM_ SG_ 1623 DI_bootGitHash "Drive inverter: boot git hash";
CM_ BO_ 1270 "Drive inverter message: loc status2";
CM_ SG_ 1270 DI_locStatus2Checksum "Drive inverter: loc status2 checksum";
CM_ SG_ 1270 DI_locStatus2Counter "Drive inverter: loc status2 counter";
CM_ SG_ 1270 DI_doublePedalState "Drive inverter: double pedal state";
CM_ SG_ 1270 DI_autopilotRequest "Drive inverter: autopilot request";
CM_ SG_ 1270 DI_rollPreventionState "Drive inverter: roll prevention state";
CM_ SG_ 1270 DI_locIntegratorSaturated "Drive inverter: loc integrator saturated";
CM_ SG_ 1270 DI_temporaryOpdActiveAfterLoncCa "Drive inverter: temporary opd active after lonc cancel";
CM_ SG_ 1270 DI_reapplyOnParkRequest "Drive inverter: reapply on park request";
CM_ SG_ 1270 DI_regenBlendingState "Drive inverter: regen blending state";
CM_ SG_ 1270 DI_brakeCpScale "Drive inverter: brake cp scale";
CM_ SG_ 1270 DI_rollbackDistance "Maximum vehicle rollback distance in current stopping event when OPD/Cruise is active";
CM_ SG_ 1270 DI_lowMuProbabilityConfidence "Drive inverter: low mu probability confidence";
CM_ SG_ 1270 DI_pedalAssistCurveSelectForSX "Drive inverter: pedal assist curve select for SX";
CM_ SG_ 1270 DI_longitudinalControlStack "Drive inverter: longitudinal control stack; raw 0 = signal not available (SNA)";
CM_ BO_ 822 "Drive inverter message: max rated power";
CM_ SG_ 822 DI_sysDrivePowerRated "Drive inverter: sys drive power rated; raw 511 = signal not available (SNA)";
CM_ SG_ 822 DI_obdDriveCycleStatus "OBD qualified drive cycle status";
CM_ SG_ 822 DI_sysRegenPowerRated "Drive inverter: sys regen power rated; raw 255 = signal not available (SNA)";
CM_ BO_ 950 "Drive inverter message: odometer status";
CM_ SG_ 950 DI_odometer "Total traveled distance; raw 4294967295 = signal not available (SNA)";
CM_ SG_ 950 DI_odometerStatusCounter "Drive inverter: odometer status counter";
CM_ SG_ 950 DI_odometerStatusChecksum "Drive inverter: odometer status checksum";
CM_ BO_ 599 "Drive inverter message: speed";
CM_ SG_ 599 DI_speedChecksum "Drive inverter: speed checksum";
CM_ SG_ 599 DI_speedCounter "Drive inverter: speed counter";
CM_ SG_ 599 DI_uiSpeed "Drive inverter: ui speed; raw 511 = signal not available (SNA)";
CM_ SG_ 599 DI_uiSpeedUnits "Drive inverter: ui speed units";
CM_ SG_ 599 DI_accelPedalPressed "TRUE when the calibrated accel pedal position > 0.0";
CM_ SG_ 599 DI_sideslipEstimate "Drive inverter: sideslip estimate";
CM_ SG_ 599 DI_vehicleSpeed "Reports vehicle speed; raw 8191 = signal not available (SNA)";
CM_ SG_ 599 DI_velocityEstimatorState "Drive inverter: velocity estimator state";
CM_ SG_ 599 DI_autoEnableHazards "Drive inverter: auto enable hazards";
CM_ SG_ 599 DI_longControlCommandActive "Drive inverter: long control command active";
CM_ BO_ 296 "Drive inverter message: system limits";
CM_ SG_ 296 DI_limitRegenPower "TRUE when torque is limited due to regen power limit.";
CM_ SG_ 296 DI_limitIBat "TRUE when torque is limited due to battery current.";
CM_ SG_ 296 DI_limitVBatLow "Drive inverter: limit v bat low";
CM_ SG_ 296 DI_limitVBatHigh "Drive inverter: limit v bat high";
CM_ SG_ 296 DI_limitObstacleDetection "TRUE when torque is limited due to obstacle detected in vehicle path.";
CM_ SG_ 296 DI_limitSystemLimp "Drive inverter: limit system limp";
CM_ SG_ 296 DI_limitSystemGPO "Drive inverter: limit system GPO";
CM_ SG_ 296 DI_limitShift "Drive inverter: limit shift";
CM_ SG_ 296 DI_limitDriveTorque "TRUE when drive torque is limited due to driver torque limit command";
CM_ SG_ 296 DI_limitRegenTorque "TRUE when regen torque is limited due to driver torque limit command";
CM_ SG_ 296 DI_limitVehicleSpeed "Drive inverter: limit vehicle speed";
CM_ SG_ 296 DI_limitBmsMiaFreeze "Drive inverter: limit bms mia freeze";
CM_ SG_ 296 DI_limitSystemSpinDownLearning "Drive inverter: limit system spin down learning";
CM_ SG_ 296 DI_limitCdp "Drive inverter: limit cdp";
CM_ SG_ 296 DI_vehicleSpeedLimitType "Speed limit source/type of DI_vehicleSpeedLimit.";
CM_ SG_ 296 DI_vehicleSpeedLimit "Vehicle speed limit (including powertrain limits) being enforced by the DI and published to the UI; raw 511 = signal not available (SNA)";
CM_ SG_ 296 DI_vehicleSpeedLimitReason "Speed limit reason of DI_vehicleSpeedLimit.";
CM_ SG_ 296 DI_limitClosureNotClosed "Drive inverter: limit closure not closed";
CM_ SG_ 296 DI_proximity "TRUE if the proximity hardware input signal is active.";
CM_ SG_ 296 DI_undersideAbuse "Drive inverter: underside abuse";
CM_ BO_ 280 "Drive inverter message: system status";
CM_ SG_ 280 DI_systemStatusChecksum "Drive inverter: system status checksum";
CM_ SG_ 280 DI_systemStatusCounter "Drive inverter: system status counter";
CM_ SG_ 280 DI_secondaryGearControlStatus "Indicates if gear control through PRND is being honored";
CM_ SG_ 280 DI_immobilizerState "Detects state of the Drive Inverter (DI) immobilizer; raw 0 = signal not available (SNA)";
CM_ SG_ 280 DI_systemState "DI system state machine state.";
CM_ SG_ 280 DI_brakePedalState "Brake pedal switch signal sensed at the drive inverter.";
CM_ SG_ 280 DI_gear "Detects the current operating gear reported by the drive inverter; raw 7 = signal not available (SNA)";
CM_ SG_ 280 DI_driveBlocked "Reason drive unit is blocked from entering enable";
CM_ SG_ 280 DI_hvilSystemStatus "Aggregated HVIL system status; raw 3 = signal not available (SNA)";
CM_ SG_ 280 DI_driveModeState "System drive mode state";
CM_ SG_ 280 DI_shiftRequestType "Type of most recent shift request";
CM_ SG_ 280 DI_accelPedalPos "Drive Inverter measured accelerator pedal position; raw 255 = signal not available (SNA)";
CM_ SG_ 280 DI_tractionControlMode "Active traction control mode as requested by the driver.";
CM_ SG_ 280 DI_dynoModeAvailable "Reports to the vehicle if the Drive Inverter (DI) will accept a request to enter dyno mode.";
CM_ SG_ 280 DI_epbRequest "Reports Electronic Parking Brake (EPB) requests.";
CM_ SG_ 280 DI_eepDeliveryBitStatus "Drive inverter: eep delivery bit status";
CM_ SG_ 280 DI_keepDrivePowerStateRequest "Reports that the Drive Inverter (DI) expects vehicle power state to remain in drive.";
CM_ SG_ 280 DI_trackModeState "Indicates state of Track mode";
CM_ SG_ 280 DI_regenLight "Drive inverter: regen light";
CM_ SG_ 280 DI_vehicleAcceleration "Drive inverter: vehicle acceleration; raw 2048 = signal not available (SNA)";
CM_ BO_ 883 "Electric power steering (primary) message: sys status";
CM_ SG_ 883 EPAS3P_steeringRackForce "The real time, estimated force applied by the steering rack to the tie rods; raw 1023 = signal not available (SNA)";
CM_ SG_ 883 EPAS3P_steeringFault "Electric power steering (primary): steering fault";
CM_ SG_ 883 EPAS3P_steeringReduced "Electric power steering (primary): steering reduced";
CM_ SG_ 883 EPAS3P_internalSASQF "This signal identifies the validity of the EPAS3P_internalSAS signal.";
CM_ SG_ 883 EPAS3P_currentTuneMode "Electric power steering (primary): current tune mode";
CM_ SG_ 883 EPAS3P_torsionBarTorque "The measurement of the steering wheel torque input. If the value is positive the steering wheel torque is applied in the clockwise direction; raw 4095 = signal not available (SNA)";
CM_ SG_ 883 EPAS3P_eacErrorCode "Electric power steering (primary): eac error code; raw 15 = signal not available (SNA)";
CM_ SG_ 883 EPAS3P_internalSAS "The measurement of the steering wheel angle that is calculated by electronic power steering assist steering. Clockwise positive.";
CM_ SG_ 883 EPAS3P_handsOnLevel "Electric power steering (primary): hands on level";
CM_ SG_ 883 EPAS3P_sysStatusCounter "Electric power steering (primary): sys status counter";
CM_ SG_ 883 EPAS3P_tireIDActive "Electric power steering (primary): tire ID active";
CM_ SG_ 883 EPAS3P_eacStatus "Electric power steering (primary): eac status";
CM_ SG_ 883 EPAS3P_sysStatusChecksum "Electric power steering (primary): sys status checksum";
CM_ BO_ 882 "Electric power steering (secondary) message: sys status";
CM_ SG_ 882 EPAS3S_steeringRackForce "The real time, estimated force applied by the steering rack to the tie rods; raw 1023 = signal not available (SNA)";
CM_ SG_ 882 EPAS3S_steeringFault "Electric power steering (secondary): steering fault";
CM_ SG_ 882 EPAS3S_steeringReduced "Electric power steering (secondary): steering reduced";
CM_ SG_ 882 EPAS3S_internalSASQF "This signal identifies the validity of the EPAS3P_internalSAS signal.";
CM_ SG_ 882 EPAS3S_currentTuneMode "Electric power steering (secondary): current tune mode";
CM_ SG_ 882 EPAS3S_torsionBarTorque "The measurement of the steering wheel torque input. If the value is positive the steering wheel torque is applied in the clockwise direction; raw 4095 = signal not available (SNA)";
CM_ SG_ 882 EPAS3S_eacErrorCode "Electric power steering (secondary): eac error code; raw 15 = signal not available (SNA)";
CM_ SG_ 882 EPAS3S_internalSAS "The measurement of the steering wheel angle that is calculated by electronic power steering assist steering. Clockwise positive.";
CM_ SG_ 882 EPAS3S_handsOnLevel "Electric power steering (secondary): hands on level";
CM_ SG_ 882 EPAS3S_sysStatusCounter "Electric power steering (secondary): sys status counter";
CM_ SG_ 882 EPAS3S_tireIDActive "Electric power steering (secondary): tire ID active";
CM_ SG_ 882 EPAS3S_eacStatus "Electric power steering (secondary): eac status";
CM_ SG_ 882 EPAS3S_sysStatusChecksum "Electric power steering (secondary): sys status checksum";
CM_ BO_ 681 "Left electric parking brake message: status";
CM_ SG_ 681 EPBL_systemStatus "Coordinated state representing the vehicle level parking brake state.";
CM_ SG_ 681 EPBL_freeRollModeStatus "Left electric parking brake: free roll mode status";
CM_ SG_ 681 EPBL_driverIsLeaving "Left electric parking brake: driver is leaving";
CM_ SG_ 681 EPBL_driverIsLeavingAnySpeed "Left electric parking brake: driver is leaving any speed";
CM_ SG_ 681 EPBL_systemCdpAvailable "Left electric parking brake: system cdp available";
CM_ SG_ 681 EPBL_chimeRequest "Left electric parking brake: chime request";
CM_ SG_ 681 EPBL_telltale "Controls the telltale illumination on the instrument cluster; raw 7 = signal not available (SNA)";
CM_ SG_ 681 EPBL_contactorCycleNotNeededForW "Left electric parking brake: contactor cycle not needed for winch entry";
CM_ SG_ 681 EPBL_redundantBrakingEnabled "Left electric parking brake: redundant braking enabled";
CM_ SG_ 681 EPBL_summonEnabled "Left electric parking brake: summon enabled";
CM_ SG_ 681 EPBL_brakeLight "Left electric parking brake: brake light";
CM_ SG_ 681 EPBL_epbConfigMismatch "Left electric parking brake: epb config mismatch";
CM_ SG_ 681 EPBL_brakeConfirmedPressed "Left electric parking brake: brake confirmed pressed";
CM_ SG_ 681 EPBL_requestUserConfirmation "Left electric parking brake: request user confirmation";
CM_ SG_ 681 EPBL_uiWinchModeMiscBlocking "Reports the expected appearance of system error message on User Interface (UI) winch mode panel.";
CM_ SG_ 681 EPBL_winchModeActive "Left electric parking brake: winch mode active";
CM_ SG_ 681 EPBL_updateMode "Left electric parking brake: update mode";
CM_ SG_ 681 EPBL_winchModePermissive "Left electric parking brake: winch mode permissive";
CM_ SG_ 681 EPBL_winchModePending "Left electric parking brake: winch mode pending";
CM_ SG_ 681 EPBL_cdpRequest "Left electric parking brake: cdp request";
CM_ SG_ 681 EPBL_uiParkAvailable "Reports the expected availability and appearance of the park button on User Interface (UI) safety panel.";
CM_ SG_ 681 EPBL_brakeDiscWipeRequest "Left electric parking brake: brake disc wipe request; raw 3 = signal not available (SNA)";
CM_ SG_ 681 EPBL_showUiGearShifter "Left electric parking brake: show ui gear shifter";
CM_ SG_ 681 EPBL_uiWinchModeLvStatus "Reports the expected availability and appearance of Low Voltage (LV) system status on UI winch mode panel.";
CM_ SG_ 681 EPBL_showStalkFaultedOnUi "Left electric parking brake: show stalk faulted on ui";
CM_ SG_ 681 EPBL_espPowerRequest "Left electric parking brake: esp power request";
CM_ SG_ 681 EPBL_okToPark "Left electric parking brake: ok to park";
CM_ SG_ 681 EPBL_hornRequest "Left electric parking brake: horn request";
CM_ SG_ 681 EPBL_winchModeAvailable "Left electric parking brake: winch mode available";
CM_ SG_ 681 EPBL_bothDisconnected "Left electric parking brake: both disconnected";
CM_ SG_ 681 EPBL_blockDrive "Left electric parking brake: block drive";
CM_ SG_ 681 EPBL_statusCounter "Left electric parking brake: status counter";
CM_ SG_ 681 EPBL_statusChecksum "Left electric parking brake: status checksum";
CM_ BO_ 742 "Right electric parking brake message: seat status3";
CM_ SG_ 742 EPBR_frontSeatCushionFanCur "Right electric parking brake: front seat cushion fan cur";
CM_ SG_ 742 EPBR_frontSeatBackrestFanCur "Right electric parking brake: front seat backrest fan cur";
CM_ SG_ 742 EPBR_frontSeatCushionFanDuty "Right electric parking brake: front seat cushion fan duty";
CM_ SG_ 742 EPBR_frontSeatCushionFanEn "Right electric parking brake: front seat cushion fan en";
CM_ SG_ 742 EPBR_frontSeatBackrestFanEn "Right electric parking brake: front seat backrest fan en";
CM_ SG_ 742 EPBR_frontSeatBackrestFanDuty "Right electric parking brake: front seat backrest fan duty";
CM_ BO_ 744 "Right electric parking brake message: status";
CM_ SG_ 744 EPBR_systemStatus "Coordinated state representing the vehicle level parking brake state.";
CM_ SG_ 744 EPBR_freeRollModeStatus "Right electric parking brake: free roll mode status";
CM_ SG_ 744 EPBR_driverIsLeaving "Right electric parking brake: driver is leaving";
CM_ SG_ 744 EPBR_driverIsLeavingAnySpeed "Right electric parking brake: driver is leaving any speed";
CM_ SG_ 744 EPBR_systemCdpAvailable "Right electric parking brake: system cdp available";
CM_ SG_ 744 EPBR_chimeRequest "Right electric parking brake: chime request";
CM_ SG_ 744 EPBR_telltale "Controls the telltale illumination on the instrument cluster; raw 7 = signal not available (SNA)";
CM_ SG_ 744 EPBR_audioCurrentSpikeDetected "Right electric parking brake: audio current spike detected";
CM_ SG_ 744 EPBR_redundantBrakingEnabled "Right electric parking brake: redundant braking enabled";
CM_ SG_ 744 EPBR_summonEnabled "Right electric parking brake: summon enabled";
CM_ SG_ 744 EPBR_brakeLight "Right electric parking brake: brake light";
CM_ SG_ 744 EPBR_epbConfigMismatch "Right electric parking brake: epb config mismatch";
CM_ SG_ 744 EPBR_brakeConfirmedPressed "Right electric parking brake: brake confirmed pressed";
CM_ SG_ 744 EPBR_requestUserConfirmation "Right electric parking brake: request user confirmation";
CM_ SG_ 744 EPBR_uiWinchModeMiscBlocking "Reports the expected appearance of system error message on User Interface (UI) winch mode panel.";
CM_ SG_ 744 EPBR_winchModeActive "Right electric parking brake: winch mode active";
CM_ SG_ 744 EPBR_updateMode "Right electric parking brake: update mode";
CM_ SG_ 744 EPBR_winchModePermissive "Right electric parking brake: winch mode permissive";
CM_ SG_ 744 EPBR_winchModePending "Right electric parking brake: winch mode pending";
CM_ SG_ 744 EPBR_cdpRequest "Right electric parking brake: cdp request";
CM_ SG_ 744 EPBR_uiParkAvailable "Reports the expected availability and appearance of the park button on User Interface (UI) safety panel.";
CM_ SG_ 744 EPBR_brakeDiscWipeRequest "Right electric parking brake: brake disc wipe request; raw 3 = signal not available (SNA)";
CM_ SG_ 744 EPBR_showUiGearShifter "Right electric parking brake: show ui gear shifter";
CM_ SG_ 744 EPBR_uiWinchModeLvStatus "Reports the expected availability and appearance of Low Voltage (LV) system status on UI winch mode panel.";
CM_ SG_ 744 EPBR_contactorCycleNotNeededForW "Right electric parking brake: contactor cycle not needed for winch entry";
CM_ SG_ 744 EPBR_showStalkFaultedOnUi "Right electric parking brake: show stalk faulted on ui";
CM_ SG_ 744 EPBR_espPowerRequest "Right electric parking brake: esp power request";
CM_ SG_ 744 EPBR_okToPark "Right electric parking brake: ok to park";
CM_ SG_ 744 EPBR_hornRequest "Right electric parking brake: horn request";
CM_ SG_ 744 EPBR_winchModeAvailable "Right electric parking brake: winch mode available";
CM_ SG_ 744 EPBR_bothDisconnected "Right electric parking brake: both disconnected";
CM_ SG_ 744 EPBR_blockDrive "Right electric parking brake: block drive";
CM_ SG_ 744 EPBR_statusCounter "Right electric parking brake: status counter";
CM_ SG_ 744 EPBR_statusChecksum "Right electric parking brake: status checksum";
CM_ BO_ 888 "Gateway message: e call";
CM_ SG_ 888 GTW_GTW_SOS_ECALL_RQST "State of the GTW-SOS-ECALL-RQST pin";
CM_ SG_ 888 GTW_LTE_ECALL_LOCK "State of the LTE-ECALL-LOCK pin";
CM_ BO_ 282 "Gateway message: adc4";
CM_ SG_ 282 GTW_BKP_BATT_MON "Gateway: BKP BATT MON; raw 4095 = signal not available (SNA)";
CM_ SG_ 282 GTW_BKP_BATT_NTC_P "BKP_BATT_NTC_P pni voltage; raw 4095 = signal not available (SNA)";
CM_ SG_ 282 GTW_ECALL_GPS_ANT_BIAS "Gateway: ECALL GPS ANT BIAS; raw 4095 = signal not available (SNA)";
CM_ SG_ 282 GTW_ECALL_MIC_DIAG "ECALL_MIC_DIAG voltage; raw 4095 = signal not available (SNA)";
CM_ SG_ 282 GTW_SOS_ECALL_nRQST_BUF "SOS_ECALL_nRQST_BUF voltage; raw 4095 = signal not available (SNA)";
CM_ BO_ 838 "Gateway message: autopilot override";
CM_ SG_ 838 GTW_autopilotOverrideState "Signals whether an autopilot trial or subscription is active";
CM_ SG_ 838 GTW_autopilotConfig "Current level of permanent Autopilot firmware";
CM_ SG_ 838 GTW_autopilotOverrideConfig "Current level of trial or subscription Autopilot firmware";
CM_ SG_ 838 GTW_autopilotOverrideExpireTime "Expiration time for the currently active autopilot trial or subscription";
CM_ BO_ 904 "Gateway message: can status";
CM_ SG_ 904 GTW_VEH_canBusActivity "Active if any frame detected on the bus";
CM_ SG_ 904 GTW_PARTY_canBusActivity "Active if any frame detected on the bus";
CM_ SG_ 904 GTW_CH_canBusActivity "Active if any frame detected on the bus";
CM_ SG_ 904 GTW_VEH_txWarning "Gateway: VEH tx warning";
CM_ SG_ 904 GTW_PARTY_txWarning "Gateway: PARTY tx warning";
CM_ SG_ 904 GTW_CH_txWarning "Gateway: CH tx warning";
CM_ SG_ 904 GTW_VEH_rxWarning "Gateway: VEH rx warning";
CM_ SG_ 904 GTW_PARTY_rxWarning "Gateway: PARTY rx warning";
CM_ SG_ 904 GTW_CH_rxWarning "Gateway: CH rx warning";
CM_ SG_ 904 GTW_VEH_faultConfinement "Fault confinement as per CAN spec";
CM_ SG_ 904 GTW_PARTY_faultConfinement "Fault confinement as per CAN spec";
CM_ SG_ 904 GTW_CH_faultConfinement "Fault confinement as per CAN spec";
CM_ BO_ 2047 "Gateway message: car config";
CM_ SG_ 2047 GTW_carConfigMultiplexer "Gateway: car config multiplexer";
CM_ SG_ 2047 GTW_deliveryStatus "Indicates whether the vehicle has been marked delivered to the customer in Tesla backend systems.";
CM_ SG_ 2047 GTW_cabinPTCHeaterType "Gateway: cabin PTC heater type";
CM_ SG_ 2047 GTW_rightHandDrive "Gateway: right hand drive";
CM_ SG_ 2047 GTW_rearLightType "Gateway: rear light type";
CM_ SG_ 2047 GTW_headlamps "Gateway: headlamps";
CM_ SG_ 2047 GTW_country "Gateway: country";
CM_ SG_ 2047 GTW_tireType "Gateway: tire type";
CM_ SG_ 2047 GTW_roofGlassType "Gateway: roof glass type";
CM_ SG_ 2047 GTW_dasHw "Indicates the Driver Assistance System (DAS) hardware installed.";
CM_ SG_ 2047 GTW_brakeHWType "Gateway: brake HW type";
CM_ SG_ 2047 GTW_restraintsHardwareType "Gateway: restraints hardware type";
CM_ SG_ 2047 GTW_drivetrainType "Gateway: drivetrain type";
CM_ SG_ 2047 GTW_radarHeaterType "Gateway: radar heater type";
CM_ SG_ 2047 GTW_exteriorTrimType "Gateway: exterior trim type";
CM_ SG_ 2047 GTW_frontSeatHeaters "Gateway: front seat heaters";
CM_ SG_ 2047 GTW_rearSeatHeaters "Gateway: rear seat heaters";
CM_ SG_ 2047 GTW_eCallAntennaHW "Gateway: e call antenna HW";
CM_ SG_ 2047 GTW_homelinkType "Gateway: homelink type";
CM_ SG_ 2047 GTW_vdcType "Gateway: vdc type";
CM_ SG_ 2047 GTW_memoryMirrors "Gateway: memory mirrors";
CM_ SG_ 2047 GTW_powerLiftgateType "Gateway: power liftgate type";
CM_ SG_ 2047 GTW_lumbarECUType "Gateway: lumbar ECU type";
CM_ SG_ 2047 GTW_rearSeatHeaterType "Gateway: rear seat heater type";
CM_ SG_ 2047 GTW_auxParkLamps "Gateway: aux park lamps";
CM_ SG_ 2047 GTW_interiorCabinRadarType "Gateway: interior cabin radar type";
CM_ SG_ 2047 GTW_hvacPanelVaneType "Gateway: hvac panel vane type";
CM_ SG_ 2047 GTW_intakeAirFilterType "Gateway: intake air filter type";
CM_ SG_ 2047 GTW_eBuckConfig "Gateway: e buck config";
CM_ SG_ 2047 GTW_steeringHeaterEnabled "Gateway: steering heater enabled";
CM_ SG_ 2047 GTW_activeHighBeam "Gateway: active high beam";
CM_ SG_ 2047 GTW_airbagCutoffSwitch "Gateway: airbag cutoff switch";
CM_ SG_ 2047 GTW_intrusionSensorType "Gateway: intrusion sensor type";
CM_ SG_ 2047 GTW_spoilerType "Gateway: spoiler type";
CM_ SG_ 2047 GTW_rearFogLamps "Gateway: rear fog lamps";
CM_ SG_ 2047 GTW_roofType "Gateway: roof type";
CM_ SG_ 2047 GTW_thirdRowSeatType "Gateway: third row seat type";
CM_ SG_ 2047 GTW_autopilot "Gateway: autopilot";
CM_ SG_ 2047 GTW_superchargingAccess "Gateway: supercharging access";
CM_ SG_ 2047 GTW_exteriorColor "Gateway: exterior color";
CM_ SG_ 2047 GTW_pedestrianWarningSound "Gateway: pedestrian warning sound";
CM_ SG_ 2047 GTW_steeringColumnUJointType "Gateway: steering column u joint type";
CM_ SG_ 2047 GTW_bPillarNFCParam "Gateway: b pillar NFC param";
CM_ SG_ 2047 GTW_interiorLighting "Gateway: interior lighting";
CM_ SG_ 2047 GTW_headlightLevelerType "Gateway: headlight leveler type";
CM_ SG_ 2047 GTW_numberHVILNodes "Gateway: number HVIL nodes";
CM_ SG_ 2047 GTW_mapRegion "Gateway: map region";
CM_ SG_ 2047 GTW_performancePackage "Gateway: performance package";
CM_ SG_ 2047 GTW_chassisType "Indicates the chassis type, which determines physical aspects such as suspension geometry, track width, wheel base, baseline tire size, and trailer capability.";
CM_ SG_ 2047 GTW_airSuspension "Gateway: air suspension";
CM_ SG_ 2047 GTW_centerConsoleControllerType "Gateway: center console controller type";
CM_ SG_ 2047 GTW_autopilotCameraType "Gateway: autopilot camera type";
CM_ SG_ 2047 GTW_connectivityPackage "Gateway: connectivity package";
CM_ SG_ 2047 GTW_plcSupportType "Gateway: plc support type";
CM_ SG_ 2047 GTW_packEnergy "Gateway: pack energy";
CM_ SG_ 2047 GTW_frontSeatReclinerHardware "Gateway: front seat recliner hardware";
CM_ SG_ 2047 GTW_brakeLineSwitchType "Gateway: brake line switch type";
CM_ SG_ 2047 GTW_softRange "Gateway: soft range";
CM_ SG_ 2047 GTW_refrigerantType "Gateway: refrigerant type";
CM_ SG_ 2047 GTW_wheelType "Gateway: wheel type";
CM_ SG_ 2047 GTW_brakeActuationType "Gateway: brake actuation type";
CM_ SG_ 2047 GTW_secondRowSeatType "Gateway: second row seat type";
CM_ SG_ 2047 GTW_secondRowSeatMotorType "Gateway: second row seat motor type";
CM_ SG_ 2047 GTW_birthday "Gateway: birthday";
CM_ SG_ 2047 GTW_eCallEnabled "Gateway: e call enabled";
CM_ SG_ 2047 GTW_parkAssistECUType "Gateway: park assist ECU type";
CM_ SG_ 2047 GTW_passengerAirbagType "Gateway: passenger airbag type";
CM_ SG_ 2047 GTW_forwardRadarHw "Gateway: forward radar hw";
CM_ SG_ 2047 GTW_frontSeatType "Gateway: front seat type";
CM_ SG_ 2047 GTW_secondRowDisplayType "Gateway: second row display type";
CM_ SG_ 2047 GTW_wirelessPhoneChargerType "Gateway: wireless phone charger type";
CM_ SG_ 2047 GTW_ethernetTunerType "Gateway: ethernet tuner type";
CM_ SG_ 2047 GTW_interiorTrimType "Gateway: interior trim type";
CM_ SG_ 2047 GTW_gloveboxUSBType "Gateway: glovebox USB type";
CM_ SG_ 2047 GTW_coolantPumpType "Gateway: coolant pump type";
CM_ SG_ 2047 GTW_epblHwType "Gateway: epbl hw type";
CM_ SG_ 2047 GTW_epbrHwType "Gateway: epbr hw type";
CM_ SG_ 2047 GTW_blowerMotorType "Gateway: blower motor type";
CM_ SG_ 2047 GTW_frontUsbHubType "Gateway: front usb hub type";
CM_ SG_ 2047 GTW_superManifoldType "Type of HVAC super manifold installed";
CM_ SG_ 2047 GTW_rcmLocation "Gateway: rcm location";
CM_ SG_ 2047 GTW_interiorCamFanType "Gateway: interior cam fan type";
CM_ SG_ 2047 GTW_sirenType "Gateway: siren type";
CM_ SG_ 2047 GTW_hornType "Gateway: horn type";
CM_ SG_ 2047 GTW_badgingVersion "Gateway: badging version";
CM_ SG_ 2047 GTW_steeringColumnMotorType "Gateway: steering column motor type";
CM_ SG_ 2047 GTW_refrigACLineType "Gateway: refrig AC line type";
CM_ SG_ 2047 GTW_refrigFilterType "Gateway: refrig filter type";
CM_ SG_ 2047 GTW_diBurnInType "Gateway: di burn in type";
CM_ SG_ 2047 GTW_specialBadgingType "Gateway: special badging type";
CM_ SG_ 2047 GTW_chassisSubType "Reports chassis sub-variant type.";
CM_ SG_ 2047 GTW_frontSeatVentilationType "Gateway: front seat ventilation type";
CM_ SG_ 2047 GTW_towPackage "Gateway: tow package";
CM_ SG_ 2047 GTW_refrigLccType "Gateway: refrig lcc type";
CM_ SG_ 2047 GTW_caliperColorType "Gateway: caliper color type";
CM_ SG_ 2047 GTW_wiperMotorType "Gateway: wiper motor type";
CM_ SG_ 2047 GTW_frontOverheadConsoleType "Gateway: front overhead console type";
CM_ SG_ 2047 GTW_shifterType "Gateway: shifter type";
CM_ SG_ 2047 GTW_compressorType "Gateway: compressor type";
CM_ SG_ 2047 GTW_twelveVBatteryType "Gateway: twelve v battery type";
CM_ SG_ 2047 GTW_efuseSWConfig "Gateway: efuse SW config";
CM_ SG_ 2047 GTW_tollCollectionModuleType "Gateway: toll collection module type";
CM_ SG_ 2047 GTW_bleEndpointUpdateMethod "Gateway: ble endpoint update method";
CM_ SG_ 2047 GTW_steeringWheelControllerType "Gateway: steering wheel controller type";
CM_ SG_ 2047 GTW_frontSeatVentilationEnabled "Gateway: front seat ventilation enabled";
CM_ SG_ 2047 GTW_gloveboxActuatorType "Gateway: glovebox actuator type";
CM_ SG_ 2047 GTW_epasType "Gateway: epas type";
CM_ SG_ 2047 GTW_homologationRegionOverride "Gateway: homologation region override";
CM_ SG_ 2047 GTW_windowCommandsPermissionType "Gateway: window commands permission type";
CM_ SG_ 2047 GTW_rgbInteriorLightingEnabled "Gateway: rgb interior lighting enabled";
CM_ SG_ 2047 GTW_windshieldWiperHeaterType "Gateway: windshield wiper heater type";
CM_ SG_ 2047 GTW_driveInterfaceType "Gateway: drive interface type";
CM_ SG_ 2047 GTW_efficiencyPackage "Gateway: efficiency package";
CM_ SG_ 2047 GTW_visorLightType "Gateway: visor light type";
CM_ SG_ 2047 GTW_gnssAntennaType "Gateway: gnss antenna type";
CM_ SG_ 2047 GTW_frontSeatHeatersEnabled "Gateway: front seat heaters enabled";
CM_ SG_ 2047 GTW_windshieldWiperHeaterEnabled "Gateway: windshield wiper heater enabled";
CM_ SG_ 2047 GTW_tcuType "Gateway: tcu type";
CM_ SG_ 2047 GTW_fasciaType "Gateway: fascia type";
CM_ SG_ 2047 GTW_powerSteeringColumn "Gateway: power steering column";
CM_ SG_ 2047 GTW_frontSeatHeaterType "Gateway: front seat heater type";
CM_ SG_ 2047 GTW_softPerformanceLimit "Gateway: soft performance limit";
CM_ SG_ 2047 GTW_alcoholInterlockType "Gateway: alcohol interlock type";
CM_ SG_ 2047 GTW_immersiveAudio "Gateway: immersive audio";
CM_ SG_ 2047 GTW_passengerOccupancySensorType "Gateway: passenger occupancy sensor type";
CM_ SG_ 2047 GTW_packPerformanceDeviation "Measures deviation from standard pack mass or power output capability associated with the vehicle packEnergy configuration.";
CM_ SG_ 2047 GTW_frontFogLamps "Gateway: front fog lamps";
CM_ SG_ 2047 GTW_driverOccupancySensorType "Gateway: driver occupancy sensor type";
CM_ SG_ 2047 GTW_audioType "Gateway: audio type";
CM_ SG_ 2047 GTW_occupancyClassificationFeatu "Gateway: occupancy classification feature type";
CM_ SG_ 2047 GTW_domeLightType "Gateway: dome light type";
CM_ SG_ 2047 GTW_tpmsType "Gateway: tpms type";
CM_ SG_ 2047 GTW_authenticationEndpointLayout "Gateway: authentication endpoint layout";
CM_ SG_ 2047 GTW_socSleepOverride "Gateway: soc sleep override";
CM_ SG_ 2047 GTW_r79BehaviorOverride "Gateway: r79 behavior override";
CM_ SG_ 2047 GTW_steeringHeaterType "Gateway: steering heater type";
CM_ SG_ 2047 GTW_sohRegulatoryStatus "Gateway: soh regulatory status";
CM_ SG_ 2047 GTW_m3yBusArchitecture "Reports notable features of vehicle communication bus architecture. Used for firmware artifact selection during update installation process.";
CM_ SG_ 2047 GTW_blindSpotIndicatorLightType "Gateway: blind spot indicator light type";
CM_ SG_ 2047 GTW_hvacCaseDoorType "Gateway: hvac case door type";
CM_ SG_ 2047 GTW_rduCableType "Indicates type of rear drive unit cable installed on vehicle.";
CM_ SG_ 2047 GTW_interiorCameraType "Gateway: interior camera type";
CM_ SG_ 2047 GTW_frontFasciaCameraType "Reports type of forward facing fascia camera installed.";
CM_ BO_ 1638 "Gateway message: diag session";
CM_ SG_ 1638 GTW_diagRemainingSeconds "Seconds remaining for the diagnostics session";
CM_ SG_ 1638 GTW_diagSessionActive "UDS Session Active";
CM_ SG_ 1638 GTW_diagLevel "Current diagnostics level";
CM_ SG_ 1638 GTW_diagUnlockProcedureActive "GTW diag unlock procedure active";
CM_ SG_ 1638 GTW_diagOverrideActive "GTW diag level override active";
CM_ SG_ 1638 GTW_diagPhysicalLinkEstablished "Physical diag cable connected to the switch and link established";
CM_ BO_ 1080 "Gateway message: eth nm";
CM_ SG_ 1080 GTW_ethGotoSleep "ETH bus sleep commanded";
CM_ SG_ 1080 GTW_ethWakeUpBus "Gateway: eth wake up bus";
CM_ SG_ 1080 GTW_vehBusAsleep "VEH bus sleep state";
CM_ SG_ 1080 GTW_ethHeartBeatCounter "Gateway: eth heart beat counter";
CM_ SG_ 1080 GTW_ethWakeUpReason "Tracks the cause of why the gateway wakes up the ethernet bus";
CM_ BO_ 1656 "Gateway message: gear control";
CM_ SG_ 1656 GTW_gearControlChecksum "Gateway: gear control checksum";
CM_ SG_ 1656 GTW_gearControlCounter "Gateway: gear control counter";
CM_ SG_ 1656 GTW_gearShiftRequest "Request to change gear state from center display UI control; raw 0 = signal not available (SNA)";
CM_ SG_ 1656 GTW_osdActive "Whether OSD is active";
CM_ SG_ 1656 GTW_primaryGearControlStatus "Status of the center display UI control";
CM_ SG_ 1656 GTW_gearStripEnable "UI control for showing and or activating the primary gear strip interface";
CM_ SG_ 1656 GTW_showNeutralButton "Tell UI that it is time to animate the N button to be shown";
CM_ SG_ 1656 GTW_showAutoParkButton "Tell UI that it is time to animate the autopark button to be shown";
CM_ SG_ 1656 GTW_autoParkRequest "Request to auto park from center display UI control";
CM_ SG_ 1656 GTW_smartShiftStatus "Based on the status of the infotainment system smart shift feature should be disabled; raw 0 = signal not available (SNA)";
CM_ SG_ 1656 GTW_processingRDgestures "Is GTW processing R and D swipe gestures";
CM_ SG_ 1656 GTW_processingTapPgestures "Is GTW processing contextual tap-to-park gestures";
CM_ SG_ 1656 GTW_gearStripChangeReason "Gateway: gear strip change reason; raw 0 = signal not available (SNA)";
CM_ SG_ 1656 GTW_touchActive "User present as touch on display is active";
CM_ SG_ 1656 GTW_steamOff "Let UI know to turn Steam off";
CM_ SG_ 1656 GTW_screenPCBTemperature "Reading from display i2c temperature sensor; raw 2047 = signal not available (SNA)";
CM_ BO_ 2033 "Gateway message: hrl";
CM_ SG_ 2033 GTW_hrlIndex "Gateway: hrl index";
CM_ SG_ 2033 GTW_hrlState "GTW hrl state";
CM_ SG_ 2033 GTW_hrlTriggerDuration "HRL duration";
CM_ SG_ 2033 GTW_hrlTriggerType "HRL trigger type";
CM_ SG_ 2033 GTW_hrlTriggerId "HRL trigger ID. A unique ID representing the signal conditions causing the HRL event to occur.";
CM_ SG_ 2033 GTW_hrlTriggerBus "Gateway: hrl trigger bus";
CM_ BO_ 60 "Gateway message: info";
CM_ SG_ 60 GTW_infoIndex "Gateway: info index";
CM_ SG_ 60 GTW_buildType "Gateway: build type";
CM_ SG_ 60 GTW_hardwareId "GTW hardware ID";
CM_ SG_ 60 GTW_platformType "Gateway: platform type";
CM_ SG_ 60 GTW_appCrc "Gateway: app crc";
CM_ SG_ 60 GTW_applicationGitHash "Gateway: application git hash";
CM_ SG_ 60 GTW_bootGitHash "Gateway: boot git hash";
CM_ BO_ 1370 "Gateway message: mismatch fault";
CM_ SG_ 1370 GTW_mismatchFaultIndex "Gateway: mismatch fault index";
CM_ SG_ 1370 GTW_mismatchFaultChecksum "Gateway: mismatch fault checksum";
CM_ SG_ 1370 GTW_mismatchFaultCounter "Gateway: mismatch fault counter";
CM_ SG_ 1370 GTW_GTWmismatchFault "Reports the Gateway (GTW) running a firmware version that does not match the rest of the vehicle";
CM_ SG_ 1370 GTW_BMSmismatchFault "Reports the high voltage Battery Management System (BMS) electronic control unit (ECU) running a firmware version that does not match the rest of the vehicle";
CM_ SG_ 1370 GTW_APSmismatchFault "Reports the Autopilot Processor Secondary (APS) electronic control unit (ECU) running a firmware version that does not match the rest of the vehicle";
CM_ SG_ 1370 GTW_BLEEPCENTERmismatchFault "Reports the Bluetooth Low Energy End Point Center (BLEEPCENTER) electronic control unit (ECU) running a firmware version that does not match the rest of the vehicle";
CM_ SG_ 1370 GTW_BLEEPLEFTmismatchFault "Reports the Bluetooth Low Energy End Point Left (BLEEPLEFT) electronic control unit (ECU) running a firmware version that does not match the rest of the vehicle";
CM_ SG_ 1370 GTW_BLEEPREARmismatchFault "Reports the Bluetooth Low Energy End Point Rear (BLEEPREAR) electronic control unit (ECU) running a firmware version that does not match the rest of the vehicle";
CM_ SG_ 1370 GTW_BLEEPRIGHTmismatchFault "Reports the Bluetooth Low Energy End Point Right (BLEEPRIGHT) electronic control unit (ECU) running a firmware version that does not match the rest of the vehicle";
CM_ SG_ 1370 GTW_CBCmismatchFault "Reports the Cabin Blower Controller (CBC) electronic control unit (ECU) running a firmware version that does not match the rest of the vehicle";
CM_ SG_ 1370 GTW_CMPmismatchFault "Reports the air conditioning compressor (CMP) electronic control unit (ECU) running a firmware version that does not match the rest of the vehicle";
CM_ SG_ 1370 GTW_CPmismatchFault "Reports the Charge Port (CP) electronic control unit (ECU) running a firmware version that does not match the rest of the vehicle";
CM_ SG_ 1370 GTW_DIFmismatchFault "Reports the front drive inverter (DIF) electronic control unit (ECU) running a firmware version that does not match the rest of the vehicle";
CM_ SG_ 1370 GTW_DIRmismatchFault "Reports the rear drive inverter (DIR) electronic control unit (ECU) running a firmware version that does not match the rest of the vehicle";
CM_ SG_ 1370 GTW_EPAS3PmismatchFault "Reports the primary Electronic Power Assisted Steering (EPAS3P) electronic control unit (ECU) running a firmware version that does not match the rest of the vehicle";
CM_ SG_ 1370 GTW_EPAS3SmismatchFault "Reports the secondary Electronic Power Assisted Steering (EPAS3S) electronic control unit (ECU) running a firmware version that does not match the rest of the vehicle";
CM_ SG_ 1370 GTW_EPBLmismatchFault "Reports the left Electronic Park Brake (EPBL) electronic control unit (ECU) running a firmware version that does not match the rest of the vehicle";
CM_ SG_ 1370 GTW_EPBRmismatchFault "Reports the right Electronic Park Brake (EPBR) electronic control unit (ECU) running a firmware version that does not match the rest of the vehicle";
CM_ SG_ 1370 GTW_ESPCALmismatchFault "Reports the Electronic Stability Program Calibration (ESPCAL) electronic control unit (ECU) running a firmware version that does not match the rest of the vehicle";
CM_ SG_ 1370 GTW_ESPmismatchFault "Reports the Electronic Stability Program (ESP) electronic control unit (ECU) running a firmware version that does not match the rest of the vehicle";
CM_ SG_ 1370 GTW_HCM3LmismatchFault "Reports the left LED matrix Headlamp Control Module (HCM3L) electronic control unit (ECU) running a firmware version that does not match the rest of the vehicle";
CM_ SG_ 1370 GTW_HCM3RmismatchFault "Reports the right LED matrix Headlamp Control Module (HCM3R) electronic control unit (ECU) running a firmware version that does not match the rest of the vehicle";
CM_ SG_ 1370 GTW_HCMLmismatchFault "Reports the left Headlamp Control Module (HCML) electronic control unit (ECU) running a firmware version that does not match the rest of the vehicle";
CM_ SG_ 1370 GTW_HCMRmismatchFault "Reports the right Headlamp Control Module (HCMR) electronic control unit (ECU) running a firmware version that does not match the rest of the vehicle";
CM_ SG_ 1370 GTW_HVPmismatchFault "Reports the High Voltage Processor (HVP) electronic control unit (ECU) running a firmware version that does not match the rest of the vehicle";
CM_ SG_ 1370 GTW_IBSTCALmismatchFault "Reports the electromechanical brake booster calibration, or iBooster Calibration (IBSTCAL), electronic control unit (ECU) running a firmware version that does not match the rest of the vehicle";
CM_ SG_ 1370 GTW_IBSTmismatchFault "Reports the electromechanical brake booster, or iBooster (IBST), electronic control unit (ECU) running a firmware version that does not match the rest of the vehicle";
CM_ SG_ 1370 GTW_LVBMSmismatchFault "Reports the Low Voltage Battery Management System (LVBMS) electronic control unit (ECU) running a firmware version that does not match the rest of the vehicle";
CM_ SG_ 1370 GTW_OCS1PmismatchFault "Reports the Occupancy Classification System - 1st Row Passenger (OCS1P) electronic control unit (ECU) running a firmware version that does not match the rest of the vehicle";
CM_ SG_ 1370 GTW_OPCFmismatchFault "Reports the front Oil Pump Controller (OPCF) electronic control unit (ECU) running a firmware version that does not match the rest of the vehicle";
CM_ SG_ 1370 GTW_OPCRmismatchFault "Reports the rear Oil Pump Controller (OPCR) electronic control unit (ECU) running a firmware version that does not match the rest of the vehicle";
CM_ SG_ 1370 GTW_PARKmismatchFault "Reports the Park Assist (PARK) electronic control unit (ECU) running a firmware version that does not match the rest of the vehicle";
CM_ SG_ 1370 GTW_PCSCPU2mismatchFault "Reports the Power Conversion System AC charging core (PCSCPU2) electronic control unit (ECU) running a firmware version that does not match the rest of the vehicle";
CM_ SG_ 1370 GTW_PCSmismatchFault "Reports the Power Conversion System (PCS) electronic control unit (ECU) running a firmware version that does not match the rest of the vehicle";
CM_ SG_ 1370 GTW_PMFmismatchFault "Reports the front Pedal Monitor (PMF) electronic control unit (ECU) running a firmware version that does not match the rest of the vehicle";
CM_ SG_ 1370 GTW_PMRmismatchFault "Reports the rear Pedal Monitor (PMR) electronic control unit (ECU) running a firmware version that does not match the rest of the vehicle";
CM_ SG_ 1370 GTW_PTCmismatchFault "Reports the Positive Temperature Coefficient (PTC) heater electronic control unit (ECU) running a firmware version that does not match the rest of the vehicle";
CM_ SG_ 1370 GTW_RCMCALmismatchFault "Reports the Restraint Control Module Calibration (RCMCAL) electronic control unit (ECU) running a firmware version that does not match the rest of the vehicle";
CM_ SG_ 1370 GTW_RCMmismatchFault "Reports the Restraint Control Module (RCM) electronic control unit (ECU) running a firmware version that does not match the rest of the vehicle";
CM_ SG_ 1370 GTW_SCCMmismatchFault "Reports the Steering Column Control Module (SCCM) electronic control unit (ECU) running a firmware version that does not match the rest of the vehicle";
CM_ SG_ 1370 GTW_SDCRmismatchFault "Reports the Secondary Disconnect Controller (SDCR) electronic control unit (ECU) running a firmware version that does not match the rest of the vehicle";
CM_ SG_ 1370 GTW_SWCmismatchFault "Reports the Steering Wheel Controller (SWC) electronic control unit (ECU) running a firmware version that does not match the rest of the vehicle";
CM_ SG_ 1370 GTW_THSmismatchFault "Reports the Temperature Humidity Sensor (THS) electronic control unit (ECU) running a firmware version that does not match the rest of the vehicle";
CM_ SG_ 1370 GTW_VCFRONTmismatchFault "Reports the front vehicle controller (VCFRONT) electronic control unit (ECU) running a firmware version that does not match the rest of the vehicle";
CM_ SG_ 1370 GTW_VCLEFTmismatchFault "Reports the left vehicle controller (VCLEFT) electronic control unit (ECU) running a firmware version that does not match the rest of the vehicle";
CM_ SG_ 1370 GTW_VCRIGHTmismatchFault "Reports the right vehicle controller (VCRIGHT) electronic control unit (ECU) running a firmware version that does not match the rest of the vehicle";
CM_ SG_ 1370 GTW_VCSECmismatchFault "Reports the vehicle security controller (VCSEC) electronic control unit (ECU) running a firmware version that does not match the rest of the vehicle";
CM_ SG_ 1370 GTW_PMmismatchFault "Reports the Pedal Monitor (PM) electronic control unit (ECU) running a firmware version that does not match the rest of the vehicle";
CM_ BO_ 840 "Gateway message: status";
CM_ SG_ 840 GTW_vehicleVersionMatchStatus "Signal to indicate if the vehicle ECUs are all on a matched production version";
CM_ SG_ 840 GTW_hwtype "Describes the chip GTW is running on; raw 0 = signal not available (SNA)";
CM_ SG_ 840 GTW_jcanProductName "Describes the JCAN reference (product) name; raw 0 = signal not available (SNA)";
CM_ SG_ 840 GTW_uptimeSeconds "GTW uptime in seconds";
CM_ SG_ 840 GTW_boardRevision "Board revision ID of the MCU PCBA";
CM_ SG_ 840 GTW_sentryModeState "Sentry Mode state; raw 6 = signal not available (SNA)";
CM_ SG_ 840 GTW_socSleepType "Describes the sleep type GTW is expecting from the SoC; raw 0 = signal not available (SNA)";
CM_ SG_ 840 GTW_resetType "Describes the type of reset GTW experienced; raw 0 = signal not available (SNA)";
CM_ BO_ 1005 "Gateway message: update status";
CM_ SG_ 1005 GTW_i2cUpdateActive "Gateway: i2c update active";
CM_ SG_ 1005 GTW_ecuUpdateStarted "Reports whether Electronic Control Unit (ECU) update phase is active.";
CM_ SG_ 1005 GTW_updateStarted "Main update in progress bit";
CM_ BO_ 1112 "Gateway message: veh nm";
CM_ SG_ 1112 GTW_nmGoingToSleep "Network management - Going to sleep state";
CM_ SG_ 1112 GTW_nmWakeUpBus "Gateway: nm wake up bus";
CM_ SG_ 1112 GTW_chBusAsleep "Chassis bus sleep state";
CM_ SG_ 1112 GTW_ethBusAsleep "ETH bus sleep state";
CM_ SG_ 1112 GTW_nmKeepAwakeReason "Network management - Keep awake reason; raw 0 = signal not available (SNA)";
CM_ SG_ 1112 GTW_nmWakeUpReason "Network management - Wakeup reason";
CM_ SG_ 1112 GTW_ethKeepAwakeReason "Reason GTW is keeping ETH bus awake; raw 0 = signal not available (SNA)";
CM_ SG_ 1112 GTW_nmDebugWakeUp "Gateway: nm debug wake up";
CM_ SG_ 1112 GTW_OTAKeepAwake "Signals that the vehicle buses should remain awake for an ongoing OTA update";
CM_ SG_ 1112 GTW_smsPokeReceived "The modem indicated it received an SMS poke";
BA_DEF_ BO_ "GenMsgCycleTime" INT 0 3600000;
BA_DEF_ BO_ "GenMsgSendType" ENUM "Cyclic","NotUsed","NotUsed","NotUsed","NotUsed","NotUsed","NotUsed","IfActive","NoMsgSendType","NotUsed";
BA_DEF_ BO_ "VFrameFormat" ENUM "StandardCAN","ExtendedCAN","reserved","J1939PG","reserved","reserved","reserved","reserved","reserved","reserved","reserved","reserved","reserved","reserved","StandardCAN_FD","ExtendedCAN_FD";
BA_DEF_ BO_ "CANFD_BRS" ENUM "0","1";
BA_DEF_ SG_ "GenSigSNA" STRING;
BA_DEF_ SG_ "SystemSignalLongSymbol" STRING;
BA_DEF_ SG_ "Confidence" ENUM "validated","plausible","layout-only","contradicted";
BA_DEF_DEF_ "GenMsgCycleTime" 0;
BA_DEF_DEF_ "GenMsgSendType" "NoMsgSendType";
BA_DEF_DEF_ "VFrameFormat" "StandardCAN";
BA_DEF_DEF_ "CANFD_BRS" "1";
BA_DEF_DEF_ "GenSigSNA" "";
BA_DEF_DEF_ "SystemSignalLongSymbol" "";
BA_DEF_DEF_ "Confidence" "layout-only";
BA_ "GenMsgCycleTime" BO_ 634 100;
BA_ "GenMsgSendType" BO_ 634 0;
BA_ "GenMsgCycleTime" BO_ 1622 1000;
BA_ "GenMsgSendType" BO_ 1622 0;
BA_ "GenMsgCycleTime" BO_ 421 100;
BA_ "GenMsgSendType" BO_ 421 0;
BA_ "GenMsgCycleTime" BO_ 725 10;
BA_ "GenMsgSendType" BO_ 725 0;
BA_ "GenMsgCycleTime" BO_ 886 1000;
BA_ "GenMsgSendType" BO_ 886 0;
BA_ "GenMsgCycleTime" BO_ 390 100;
BA_ "GenMsgSendType" BO_ 390 0;
BA_ "GenMsgCycleTime" BO_ 633 100;
BA_ "GenMsgSendType" BO_ 633 0;
BA_ "GenMsgCycleTime" BO_ 821 1000;
BA_ "GenMsgSendType" BO_ 821 0;
BA_ "GenMsgCycleTime" BO_ 2039 100;
BA_ "GenMsgSendType" BO_ 2039 0;
BA_ "GenMsgCycleTime" BO_ 598 10;
BA_ "GenMsgSendType" BO_ 598 0;
BA_ "GenMsgCycleTime" BO_ 789 1000;
BA_ "GenMsgSendType" BO_ 789 0;
BA_ "GenMsgCycleTime" BO_ 264 10;
BA_ "GenMsgSendType" BO_ 264 0;
BA_ "GenMsgCycleTime" BO_ 1861 100;
BA_ "GenMsgSendType" BO_ 1861 0;
BA_ "GenMsgCycleTime" BO_ 694 100;
BA_ "GenMsgSendType" BO_ 694 0;
BA_ "GenMsgCycleTime" BO_ 1866 1000;
BA_ "GenMsgSendType" BO_ 1866 0;
BA_ "GenMsgCycleTime" BO_ 1623 1000;
BA_ "GenMsgSendType" BO_ 1623 0;
BA_ "GenMsgCycleTime" BO_ 1270 100;
BA_ "GenMsgSendType" BO_ 1270 0;
BA_ "GenMsgCycleTime" BO_ 822 1000;
BA_ "GenMsgSendType" BO_ 822 0;
BA_ "GenMsgCycleTime" BO_ 950 1000;
BA_ "GenMsgSendType" BO_ 950 0;
BA_ "GenMsgCycleTime" BO_ 599 20;
BA_ "GenMsgSendType" BO_ 599 0;
BA_ "GenMsgCycleTime" BO_ 296 100;
BA_ "GenMsgSendType" BO_ 296 0;
BA_ "GenMsgCycleTime" BO_ 280 10;
BA_ "GenMsgSendType" BO_ 280 0;
BA_ "GenMsgCycleTime" BO_ 883 10;
BA_ "GenMsgSendType" BO_ 883 0;
BA_ "GenMsgCycleTime" BO_ 882 10;
BA_ "GenMsgSendType" BO_ 882 0;
BA_ "GenMsgCycleTime" BO_ 681 100;
BA_ "GenMsgSendType" BO_ 681 0;
BA_ "GenMsgCycleTime" BO_ 742 1000;
BA_ "GenMsgSendType" BO_ 742 0;
BA_ "GenMsgCycleTime" BO_ 744 100;
BA_ "GenMsgSendType" BO_ 744 0;
BA_ "GenMsgCycleTime" BO_ 888 1000;
BA_ "GenMsgSendType" BO_ 888 0;
BA_ "GenMsgCycleTime" BO_ 282 1000;
BA_ "GenMsgSendType" BO_ 282 0;
BA_ "GenMsgCycleTime" BO_ 838 1000;
BA_ "GenMsgSendType" BO_ 838 0;
BA_ "GenMsgCycleTime" BO_ 904 1000;
BA_ "GenMsgSendType" BO_ 904 0;
BA_ "GenMsgCycleTime" BO_ 2047 100;
BA_ "GenMsgSendType" BO_ 2047 0;
BA_ "GenMsgCycleTime" BO_ 1638 250;
BA_ "GenMsgSendType" BO_ 1638 0;
BA_ "GenMsgCycleTime" BO_ 1080 100;
BA_ "GenMsgSendType" BO_ 1080 0;
BA_ "GenMsgCycleTime" BO_ 1656 100;
BA_ "GenMsgSendType" BO_ 1656 0;
BA_ "GenMsgCycleTime" BO_ 2033 2000;
BA_ "GenMsgSendType" BO_ 2033 0;
BA_ "GenMsgCycleTime" BO_ 60 2000;
BA_ "GenMsgSendType" BO_ 60 0;
BA_ "GenMsgCycleTime" BO_ 1370 250;
BA_ "GenMsgSendType" BO_ 1370 0;
BA_ "GenMsgCycleTime" BO_ 840 1000;
BA_ "GenMsgSendType" BO_ 840 0;
BA_ "GenMsgCycleTime" BO_ 1005 1000;
BA_ "GenMsgSendType" BO_ 1005 0;
BA_ "GenMsgCycleTime" BO_ 1112 100;
BA_ "GenMsgSendType" BO_ 1112 0;
BA_ "Confidence" SG_ 634 DIF_hvStatusChecksum 0;
BA_ "Confidence" SG_ 634 DIF_hvStatusCounter 0;
BA_ "Confidence" SG_ 634 DIF_hvilCurrent 0;
BA_ "Confidence" SG_ 634 DIF_hvilCmVoltage 0;
BA_ "Confidence" SG_ 634 DIF_hvilStatus 0;
BA_ "GenSigSNA" SG_ 634 DIF_hvilStatus "3";
BA_ "Confidence" SG_ 634 DIF_hvilSupplyState 0;
BA_ "Confidence" SG_ 634 DIF_activeDischargeCtrl 0;
BA_ "Confidence" SG_ 634 DIF_activeDischargeStatus 0;
BA_ "Confidence" SG_ 634 DIF_vBat 0;
BA_ "Confidence" SG_ 634 DIF_vBatQF 0;
BA_ "Confidence" SG_ 634 DIF_powerStageSafeState 0;
BA_ "Confidence" SG_ 634 DIF_fluxState 0;
BA_ "Confidence" SG_ 634 DIF_vBusDiag 0;
BA_ "Confidence" SG_ 634 DIF_gateDriveState 0;
BA_ "Confidence" SG_ 1622 DIF_infoIndex 1;
BA_ "Confidence" SG_ 1622 DIF_buildType 0;
BA_ "Confidence" SG_ 1622 DIF_buildConfigurationId 0;
BA_ "Confidence" SG_ 1622 DIF_hardwareId 0;
BA_ "Confidence" SG_ 1622 DIF_componentId 0;
BA_ "Confidence" SG_ 1622 DIF_pcbaId 0;
BA_ "Confidence" SG_ 1622 DIF_assemblyId 0;
BA_ "Confidence" SG_ 1622 DIF_usageId 0;
BA_ "Confidence" SG_ 1622 DIF_subUsageId 0;
BA_ "Confidence" SG_ 1622 DIF_motorType 1;
BA_ "GenSigSNA" SG_ 1622 DIF_motorType "0";
BA_ "Confidence" SG_ 1622 DIF_siliconType 0;
BA_ "Confidence" SG_ 1622 DIF_mechSafeStateType 0;
BA_ "GenSigSNA" SG_ 1622 DIF_mechSafeStateType "0";
BA_ "Confidence" SG_ 1622 DIF_applicationCrc 0;
BA_ "Confidence" SG_ 1622 DIF_oilPumpBuildType 0;
BA_ "Confidence" SG_ 1622 DIF_oilPumpAppCrc 0;
BA_ "Confidence" SG_ 1622 DIF_FPGA_version 0;
BA_ "GenSigSNA" SG_ 1622 DIF_FPGA_version "255";
BA_ "Confidence" SG_ 1622 DIF_appGitHash 0;
BA_ "Confidence" SG_ 1622 DIF_bootGitHash 0;
BA_ "Confidence" SG_ 1622 DIF_platformTyp 0;
BA_ "Confidence" SG_ 1622 DIF_infoBootLdUdsProtocolVersion 0;
BA_ "Confidence" SG_ 1622 DIF_bootloaderCrc 0;
BA_ "Confidence" SG_ 1622 DIF_oilPumpPcbaId 0;
BA_ "Confidence" SG_ 1622 DIF_oilPumpAssemblyId 0;
BA_ "Confidence" SG_ 1622 DIF_oilPumpUsageId 0;
BA_ "Confidence" SG_ 1622 DIF_refRotorFlux 0;
BA_ "Confidence" SG_ 1622 DIF_refRotorOffset 0;
BA_ "GenSigSNA" SG_ 1622 DIF_refRotorOffset "2048";
BA_ "Confidence" SG_ 1622 DIF_speedWearTotal 0;
BA_ "GenSigSNA" SG_ 1622 DIF_speedWearTotal "255";
BA_ "Confidence" SG_ 1622 DIF_torqueWearTotal 0;
BA_ "GenSigSNA" SG_ 1622 DIF_torqueWearTotal "255";
BA_ "Confidence" SG_ 421 DIF_motorCurrent 0;
BA_ "Confidence" SG_ 421 DIF_switchingFrequency 0;
BA_ "Confidence" SG_ 421 DIF_targetFluxMode 0;
BA_ "Confidence" SG_ 421 DIF_switchShortTestRetryCount 0;
BA_ "Confidence" SG_ 725 DIF_statusChecksum 0;
BA_ "Confidence" SG_ 725 DIF_statusCounter 0;
BA_ "Confidence" SG_ 725 DIF_state 0;
BA_ "Confidence" SG_ 725 DIF_keepAliveRequest 1;
BA_ "Confidence" SG_ 725 DIF_soptState 1;
BA_ "GenSigSNA" SG_ 725 DIF_soptState "8";
BA_ "Confidence" SG_ 725 DIF_adState 0;
BA_ "Confidence" SG_ 725 DIF_driveModeState 0;
BA_ "Confidence" SG_ 725 DIF_lvSupplyV 0;
BA_ "Confidence" SG_ 725 DIF_wasteState 0;
BA_ "Confidence" SG_ 725 DIF_haltRequest 0;
BA_ "Confidence" SG_ 725 DIF_axleSpeedLimitRequest 0;
BA_ "Confidence" SG_ 725 DIF_adDirection 0;
BA_ "Confidence" SG_ 725 DIF_spinDownLearningState 0;
BA_ "Confidence" SG_ 725 DIF_spinDownLearningMode 1;
BA_ "Confidence" SG_ 886 DIF_tempIndex 1;
BA_ "Confidence" SG_ 886 DIF_inverterTQF 0;
BA_ "Confidence" SG_ 886 DIF_pcbT 0;
BA_ "GenSigSNA" SG_ 886 DIF_pcbT "0";
BA_ "Confidence" SG_ 886 DIF_inverterT 0;
BA_ "Confidence" SG_ 886 DIF_statorT 0;
BA_ "GenSigSNA" SG_ 886 DIF_statorT "0";
BA_ "Confidence" SG_ 886 DIF_dcCapT 0;
BA_ "GenSigSNA" SG_ 886 DIF_dcCapT "0";
BA_ "Confidence" SG_ 886 DIF_heatsinkT 0;
BA_ "GenSigSNA" SG_ 886 DIF_heatsinkT "0";
BA_ "Confidence" SG_ 886 DIF_inverterTpct 0;
BA_ "Confidence" SG_ 886 DIF_statorTpct 0;
BA_ "Confidence" SG_ 886 DIF_fluidInTemp 0;
BA_ "GenSigSNA" SG_ 886 DIF_fluidInTemp "0";
BA_ "Confidence" SG_ 886 DIF_normalFetBurnIn 0;
BA_ "GenSigSNA" SG_ 886 DIF_normalFetBurnIn "65535";
BA_ "Confidence" SG_ 886 DIF_additionalFetBurnIn 0;
BA_ "GenSigSNA" SG_ 886 DIF_additionalFetBurnIn "65535";
BA_ "Confidence" SG_ 886 DIF_currentWeibullMiles 0;
BA_ "GenSigSNA" SG_ 886 DIF_currentWeibullMiles "32767";
BA_ "Confidence" SG_ 886 DIF_endOfServiceWeibullMiles 0;
BA_ "GenSigSNA" SG_ 886 DIF_endOfServiceWeibullMiles "32767";
BA_ "Confidence" SG_ 886 DIF_burnInDamageRatio 0;
BA_ "GenSigSNA" SG_ 886 DIF_burnInDamageRatio "511";
BA_ "Confidence" SG_ 886 DIF_inverterSensorEst 0;
BA_ "Confidence" SG_ 886 DIF_inverterHS1Est 0;
BA_ "Confidence" SG_ 886 DIF_initialBurnInVehicleOdometer 0;
BA_ "GenSigSNA" SG_ 886 DIF_initialBurnInVehicleOdometer "4294967295";
BA_ "Confidence" SG_ 886 DIF_inverterHS2Est 0;
BA_ "Confidence" SG_ 886 DIF_inverterInletEst 0;
BA_ "Confidence" SG_ 390 DIF_torqueChecksum 0;
BA_ "Confidence" SG_ 390 DIF_torqueCounter 0;
BA_ "Confidence" SG_ 390 DIF_torqueCommand 0;
BA_ "GenSigSNA" SG_ 390 DIF_torqueCommand "4096";
BA_ "Confidence" SG_ 390 DIF_axleSpeedQF 0;
BA_ "Confidence" SG_ 390 DIF_torqueActual 0;
BA_ "GenSigSNA" SG_ 390 DIF_torqueActual "4096";
BA_ "Confidence" SG_ 390 DIF_axleSpeed 0;
BA_ "GenSigSNA" SG_ 390 DIF_axleSpeed "32768";
BA_ "Confidence" SG_ 390 DIF_axleTorqueQF 0;
BA_ "Confidence" SG_ 390 DIF_axlePowerCalcQF 0;
BA_ "Confidence" SG_ 633 DIR_hvStatusChecksum 0;
BA_ "Confidence" SG_ 633 DIR_hvStatusCounter 0;
BA_ "Confidence" SG_ 633 DIR_hvilCurrent 0;
BA_ "Confidence" SG_ 633 DIR_hvilCmVoltage 0;
BA_ "Confidence" SG_ 633 DIR_hvilStatus 0;
BA_ "GenSigSNA" SG_ 633 DIR_hvilStatus "3";
BA_ "Confidence" SG_ 633 DIR_hvilSupplyState 0;
BA_ "Confidence" SG_ 633 DIR_activeDischargeCtrl 0;
BA_ "Confidence" SG_ 633 DIR_activeDischargeStatus 0;
BA_ "Confidence" SG_ 633 DIR_vBat 0;
BA_ "Confidence" SG_ 633 DIR_vBatQF 0;
BA_ "Confidence" SG_ 633 DIR_powerStageSafeState 0;
BA_ "Confidence" SG_ 633 DIR_fluxState 0;
BA_ "Confidence" SG_ 633 DIR_vBusDiag 0;
BA_ "Confidence" SG_ 633 DIR_gateDriveState 0;
BA_ "Confidence" SG_ 821 DIR_infoIndex 1;
BA_ "Confidence" SG_ 821 DIR_buildType 0;
BA_ "Confidence" SG_ 821 DIR_buildConfigurationId 0;
BA_ "Confidence" SG_ 821 DIR_hardwareId 0;
BA_ "Confidence" SG_ 821 DIR_componentId 0;
BA_ "Confidence" SG_ 821 DIR_pcbaId 0;
BA_ "Confidence" SG_ 821 DIR_assemblyId 0;
BA_ "Confidence" SG_ 821 DIR_usageId 0;
BA_ "Confidence" SG_ 821 DIR_subUsageId 0;
BA_ "Confidence" SG_ 821 DIR_motorType 1;
BA_ "GenSigSNA" SG_ 821 DIR_motorType "0";
BA_ "Confidence" SG_ 821 DIR_siliconType 0;
BA_ "Confidence" SG_ 821 DIR_mechSafeStateType 0;
BA_ "GenSigSNA" SG_ 821 DIR_mechSafeStateType "0";
BA_ "Confidence" SG_ 821 DIR_applicationCrc 0;
BA_ "Confidence" SG_ 821 DIR_oilPumpBuildType 0;
BA_ "Confidence" SG_ 821 DIR_oilPumpAppCrc 0;
BA_ "Confidence" SG_ 821 DIR_FPGA_version 0;
BA_ "GenSigSNA" SG_ 821 DIR_FPGA_version "255";
BA_ "Confidence" SG_ 821 DIR_bootGitHash 0;
BA_ "Confidence" SG_ 821 DIR_infoBootLdUdsProtocolVersion 0;
BA_ "Confidence" SG_ 821 DIR_bootloaderCrc 0;
BA_ "Confidence" SG_ 821 DIR_oilPumpPcbaId 0;
BA_ "Confidence" SG_ 821 DIR_oilPumpAssemblyId 0;
BA_ "Confidence" SG_ 821 DIR_oilPumpUsageId 0;
BA_ "Confidence" SG_ 821 DIR_refRotorFlux 0;
BA_ "Confidence" SG_ 821 DIR_refRotorOffset 0;
BA_ "GenSigSNA" SG_ 821 DIR_refRotorOffset "2048";
BA_ "Confidence" SG_ 821 DIR_speedWearTotal 0;
BA_ "GenSigSNA" SG_ 821 DIR_speedWearTotal "255";
BA_ "Confidence" SG_ 821 DIR_torqueWearTotal 0;
BA_ "GenSigSNA" SG_ 821 DIR_torqueWearTotal "255";
BA_ "Confidence" SG_ 2039 DIR_motorCurrent 0;
BA_ "Confidence" SG_ 2039 DIR_switchingFrequency 0;
BA_ "Confidence" SG_ 2039 DIR_targetFluxMode 0;
BA_ "Confidence" SG_ 2039 DIR_switchShortTestRetryCount 0;
BA_ "Confidence" SG_ 598 DIR_statusChecksum 0;
BA_ "Confidence" SG_ 598 DIR_statusCounter 0;
BA_ "Confidence" SG_ 598 DIR_state 0;
BA_ "Confidence" SG_ 598 DIR_keepAliveRequest 1;
BA_ "Confidence" SG_ 598 DIR_soptState 1;
BA_ "GenSigSNA" SG_ 598 DIR_soptState "8";
BA_ "Confidence" SG_ 598 DIR_adState 0;
BA_ "Confidence" SG_ 598 DIR_driveModeState 0;
BA_ "Confidence" SG_ 598 DIR_lvSupplyV 0;
BA_ "Confidence" SG_ 598 DIR_wasteState 0;
BA_ "Confidence" SG_ 598 DIR_haltRequest 0;
BA_ "Confidence" SG_ 598 DIR_axleSpeedLimitRequest 0;
BA_ "Confidence" SG_ 598 DIR_adDirection 0;
BA_ "Confidence" SG_ 598 DIR_spinDownLearningState 0;
BA_ "Confidence" SG_ 598 DIR_spinDownLearningMode 1;
BA_ "Confidence" SG_ 789 DIR_tempIndex 1;
BA_ "Confidence" SG_ 789 DIR_inverterTQF 0;
BA_ "Confidence" SG_ 789 DIR_pcbT 0;
BA_ "GenSigSNA" SG_ 789 DIR_pcbT "0";
BA_ "Confidence" SG_ 789 DIR_inverterT 0;
BA_ "Confidence" SG_ 789 DIR_statorT 0;
BA_ "GenSigSNA" SG_ 789 DIR_statorT "0";
BA_ "Confidence" SG_ 789 DIR_dcCapT 0;
BA_ "GenSigSNA" SG_ 789 DIR_dcCapT "0";
BA_ "Confidence" SG_ 789 DIR_heatsinkT 0;
BA_ "GenSigSNA" SG_ 789 DIR_heatsinkT "0";
BA_ "Confidence" SG_ 789 DIR_inverterTpct 0;
BA_ "Confidence" SG_ 789 DIR_statorTpct 0;
BA_ "Confidence" SG_ 789 DIR_fluidInTemp 0;
BA_ "GenSigSNA" SG_ 789 DIR_fluidInTemp "0";
BA_ "Confidence" SG_ 789 DIR_normalFetBurnIn 0;
BA_ "GenSigSNA" SG_ 789 DIR_normalFetBurnIn "65535";
BA_ "Confidence" SG_ 789 DIR_additionalFetBurnIn 0;
BA_ "GenSigSNA" SG_ 789 DIR_additionalFetBurnIn "65535";
BA_ "Confidence" SG_ 789 DIR_currentWeibullMiles 0;
BA_ "GenSigSNA" SG_ 789 DIR_currentWeibullMiles "32767";
BA_ "Confidence" SG_ 789 DIR_endOfServiceWeibullMiles 0;
BA_ "GenSigSNA" SG_ 789 DIR_endOfServiceWeibullMiles "32767";
BA_ "Confidence" SG_ 789 DIR_burnInDamageRatio 0;
BA_ "GenSigSNA" SG_ 789 DIR_burnInDamageRatio "511";
BA_ "Confidence" SG_ 789 DIR_inverterSensorEst 0;
BA_ "Confidence" SG_ 789 DIR_inverterHS1Est 0;
BA_ "Confidence" SG_ 789 DIR_initialBurnInVehicleOdometer 0;
BA_ "GenSigSNA" SG_ 789 DIR_initialBurnInVehicleOdometer "4294967295";
BA_ "Confidence" SG_ 789 DIR_inverterHS2Est 0;
BA_ "Confidence" SG_ 789 DIR_inverterInletEst 0;
BA_ "Confidence" SG_ 264 DIR_torqueChecksum 0;
BA_ "Confidence" SG_ 264 DIR_torqueCounter 0;
BA_ "Confidence" SG_ 264 DIR_torqueCommand 0;
BA_ "GenSigSNA" SG_ 264 DIR_torqueCommand "4096";
BA_ "Confidence" SG_ 264 DIR_axleSpeedQF 0;
BA_ "Confidence" SG_ 264 DIR_torqueActual 0;
BA_ "GenSigSNA" SG_ 264 DIR_torqueActual "4096";
BA_ "Confidence" SG_ 264 DIR_axleSpeed 0;
BA_ "GenSigSNA" SG_ 264 DIR_axleSpeed "32768";
BA_ "Confidence" SG_ 264 DIR_axleTorqueQF 0;
BA_ "Confidence" SG_ 264 DIR_axlePowerCalcQF 0;
BA_ "Confidence" SG_ 1861 DI_gradeAngle 0;
BA_ "Confidence" SG_ 1861 DI_bankAngle 0;
BA_ "Confidence" SG_ 1861 DI_chassisControlVideoRequest 0;
BA_ "Confidence" SG_ 1861 DI_tireUtilizationRatioFrL 0;
BA_ "Confidence" SG_ 1861 DI_tireUtilizationRatioFrR 0;
BA_ "Confidence" SG_ 1861 DI_tireUtilizationRatioReL 0;
BA_ "Confidence" SG_ 1861 DI_tireUtilizationRatioReR 0;
BA_ "Confidence" SG_ 1861 DI_counterSteerTarget 0;
BA_ "Confidence" SG_ 1861 DI_splitMuProbability 0;
BA_ "Confidence" SG_ 1861 DI_mzError 0;
BA_ "Confidence" SG_ 1861 DI_slipDifferenceFrontRear 0;
BA_ "Confidence" SG_ 1861 DI_highFreqYawRate 0;
BA_ "Confidence" SG_ 1861 DI_turnDirection 0;
BA_ "Confidence" SG_ 1861 DI_absolutePreControlRequest 0;
BA_ "Confidence" SG_ 1861 DI_oppositeBuildDirFrontAxle 0;
BA_ "Confidence" SG_ 1861 DI_oppositeBuildDirRearAxle 0;
BA_ "Confidence" SG_ 1861 DI_saturatedEffectiveness 0;
BA_ "Confidence" SG_ 1861 DI_driverPanicIndex 0;
BA_ "Confidence" SG_ 1861 DI_learnDownMu 0;
BA_ "Confidence" SG_ 1861 DI_preControlOpposingTurnDir 0;
BA_ "Confidence" SG_ 1861 DI_driverFxError 0;
BA_ "Confidence" SG_ 1861 DI_targetSaturation 0;
BA_ "Confidence" SG_ 694 DI_vdcTelltaleFlash 0;
BA_ "Confidence" SG_ 694 DI_vdcTelltaleOn 0;
BA_ "Confidence" SG_ 694 DI_tcTelltaleFlash 0;
BA_ "Confidence" SG_ 694 DI_tcTelltaleOn 0;
BA_ "Confidence" SG_ 694 DI_tractionControlModeUI 0;
BA_ "Confidence" SG_ 694 DI_ptcStateGlobalUI 0;
BA_ "GenSigSNA" SG_ 694 DI_ptcStateGlobalUI "3";
BA_ "Confidence" SG_ 694 DI_btcStateUI 0;
BA_ "Confidence" SG_ 694 DI_vehicleHoldTelltaleOn 0;
BA_ "Confidence" SG_ 694 DI_opdFeedbackReset 0;
BA_ "Confidence" SG_ 694 DI_opdFeedbackResetPositiveSpeed 0;
BA_ "SystemSignalLongSymbol" SG_ 694 DI_opdFeedbackResetPositiveSpeed "DI_opdFeedbackResetPositiveSpeeds";
BA_ "Confidence" SG_ 694 DI_slipperySurfaceOnUI 0;
BA_ "Confidence" SG_ 694 DI_yellowBrakeTelltaleOn 0;
BA_ "Confidence" SG_ 694 DI_greenABSTelltaleOn 0;
BA_ "Confidence" SG_ 1866 DI_estimatedBrakeTempChecksum 0;
BA_ "Confidence" SG_ 1866 DI_estimatedBrakeTempCounter 0;
BA_ "Confidence" SG_ 1866 DI_brakeFLTemp 0;
BA_ "GenSigSNA" SG_ 1866 DI_brakeFLTemp "1023";
BA_ "Confidence" SG_ 1866 DI_brakeFRTemp 0;
BA_ "GenSigSNA" SG_ 1866 DI_brakeFRTemp "1023";
BA_ "Confidence" SG_ 1866 DI_brakeRLTemp 0;
BA_ "GenSigSNA" SG_ 1866 DI_brakeRLTemp "1023";
BA_ "Confidence" SG_ 1866 DI_brakeRRTemp 0;
BA_ "GenSigSNA" SG_ 1866 DI_brakeRRTemp "1023";
BA_ "Confidence" SG_ 1623 DI_infoIndex 1;
BA_ "Confidence" SG_ 1623 DI_buildType 0;
BA_ "Confidence" SG_ 1623 DI_buildConfigurationId 0;
BA_ "Confidence" SG_ 1623 DI_hardwareId 0;
BA_ "Confidence" SG_ 1623 DI_componentId 0;
BA_ "Confidence" SG_ 1623 DI_pcbaId 0;
BA_ "Confidence" SG_ 1623 DI_assemblyId 0;
BA_ "Confidence" SG_ 1623 DI_usageId 0;
BA_ "Confidence" SG_ 1623 DI_subUsageId 0;
BA_ "Confidence" SG_ 1623 DI_applicationCrc 0;
BA_ "Confidence" SG_ 1623 DI_bootGitHash 0;
BA_ "Confidence" SG_ 1270 DI_locStatus2Checksum 0;
BA_ "Confidence" SG_ 1270 DI_locStatus2Counter 0;
BA_ "Confidence" SG_ 1270 DI_doublePedalState 0;
BA_ "Confidence" SG_ 1270 DI_autopilotRequest 0;
BA_ "Confidence" SG_ 1270 DI_rollPreventionState 0;
BA_ "Confidence" SG_ 1270 DI_locIntegratorSaturated 0;
BA_ "Confidence" SG_ 1270 DI_temporaryOpdActiveAfterLoncCa 0;
BA_ "SystemSignalLongSymbol" SG_ 1270 DI_temporaryOpdActiveAfterLoncCa "DI_temporaryOpdActiveAfterLoncCancel";
BA_ "Confidence" SG_ 1270 DI_reapplyOnParkRequest 0;
BA_ "Confidence" SG_ 1270 DI_regenBlendingState 1;
BA_ "Confidence" SG_ 1270 DI_brakeCpScale 0;
BA_ "Confidence" SG_ 1270 DI_rollbackDistance 0;
BA_ "Confidence" SG_ 1270 DI_lowMuProbabilityConfidence 0;
BA_ "Confidence" SG_ 1270 DI_pedalAssistCurveSelectForSX 0;
BA_ "Confidence" SG_ 1270 DI_longitudinalControlStack 0;
BA_ "GenSigSNA" SG_ 1270 DI_longitudinalControlStack "0";
BA_ "Confidence" SG_ 822 DI_sysDrivePowerRated 0;
BA_ "GenSigSNA" SG_ 822 DI_sysDrivePowerRated "511";
BA_ "Confidence" SG_ 822 DI_obdDriveCycleStatus 1;
BA_ "Confidence" SG_ 822 DI_sysRegenPowerRated 0;
BA_ "GenSigSNA" SG_ 822 DI_sysRegenPowerRated "255";
BA_ "Confidence" SG_ 950 DI_odometer 0;
BA_ "GenSigSNA" SG_ 950 DI_odometer "4294967295";
BA_ "Confidence" SG_ 950 DI_odometerStatusCounter 0;
BA_ "Confidence" SG_ 950 DI_odometerStatusChecksum 0;
BA_ "Confidence" SG_ 599 DI_speedChecksum 0;
BA_ "Confidence" SG_ 599 DI_speedCounter 0;
BA_ "Confidence" SG_ 599 DI_uiSpeed 0;
BA_ "GenSigSNA" SG_ 599 DI_uiSpeed "511";
BA_ "Confidence" SG_ 599 DI_uiSpeedUnits 0;
BA_ "Confidence" SG_ 599 DI_accelPedalPressed 0;
BA_ "Confidence" SG_ 599 DI_sideslipEstimate 0;
BA_ "Confidence" SG_ 599 DI_vehicleSpeed 0;
BA_ "GenSigSNA" SG_ 599 DI_vehicleSpeed "8191";
BA_ "Confidence" SG_ 599 DI_velocityEstimatorState 0;
BA_ "Confidence" SG_ 599 DI_autoEnableHazards 0;
BA_ "Confidence" SG_ 599 DI_longControlCommandActive 0;
BA_ "Confidence" SG_ 296 DI_limitRegenPower 0;
BA_ "Confidence" SG_ 296 DI_limitIBat 0;
BA_ "Confidence" SG_ 296 DI_limitVBatLow 0;
BA_ "Confidence" SG_ 296 DI_limitVBatHigh 0;
BA_ "Confidence" SG_ 296 DI_limitObstacleDetection 0;
BA_ "Confidence" SG_ 296 DI_limitSystemLimp 0;
BA_ "Confidence" SG_ 296 DI_limitSystemGPO 0;
BA_ "Confidence" SG_ 296 DI_limitShift 0;
BA_ "Confidence" SG_ 296 DI_limitDriveTorque 0;
BA_ "Confidence" SG_ 296 DI_limitRegenTorque 0;
BA_ "Confidence" SG_ 296 DI_limitVehicleSpeed 0;
BA_ "Confidence" SG_ 296 DI_limitBmsMiaFreeze 0;
BA_ "Confidence" SG_ 296 DI_limitSystemSpinDownLearning 0;
BA_ "Confidence" SG_ 296 DI_limitCdp 0;
BA_ "Confidence" SG_ 296 DI_vehicleSpeedLimitType 0;
BA_ "Confidence" SG_ 296 DI_vehicleSpeedLimit 0;
BA_ "GenSigSNA" SG_ 296 DI_vehicleSpeedLimit "511";
BA_ "Confidence" SG_ 296 DI_vehicleSpeedLimitReason 1;
BA_ "Confidence" SG_ 296 DI_proximity 0;
BA_ "Confidence" SG_ 280 DI_systemStatusChecksum 0;
BA_ "Confidence" SG_ 280 DI_systemStatusCounter 0;
BA_ "Confidence" SG_ 280 DI_secondaryGearControlStatus 0;
BA_ "Confidence" SG_ 280 DI_immobilizerState 0;
BA_ "GenSigSNA" SG_ 280 DI_immobilizerState "0";
BA_ "Confidence" SG_ 280 DI_systemState 0;
BA_ "Confidence" SG_ 280 DI_brakePedalState 0;
BA_ "Confidence" SG_ 280 DI_gear 0;
BA_ "GenSigSNA" SG_ 280 DI_gear "7";
BA_ "Confidence" SG_ 280 DI_driveBlocked 0;
BA_ "Confidence" SG_ 280 DI_hvilSystemStatus 0;
BA_ "GenSigSNA" SG_ 280 DI_hvilSystemStatus "3";
BA_ "Confidence" SG_ 280 DI_driveModeState 0;
BA_ "Confidence" SG_ 280 DI_shiftRequestType 0;
BA_ "Confidence" SG_ 280 DI_accelPedalPos 0;
BA_ "GenSigSNA" SG_ 280 DI_accelPedalPos "255";
BA_ "Confidence" SG_ 280 DI_tractionControlMode 0;
BA_ "Confidence" SG_ 280 DI_dynoModeAvailable 0;
BA_ "Confidence" SG_ 280 DI_epbRequest 0;
BA_ "Confidence" SG_ 280 DI_keepDrivePowerStateRequest 0;
BA_ "Confidence" SG_ 280 DI_trackModeState 0;
BA_ "Confidence" SG_ 280 DI_regenLight 0;
BA_ "Confidence" SG_ 280 DI_vehicleAcceleration 0;
BA_ "GenSigSNA" SG_ 280 DI_vehicleAcceleration "2048";
BA_ "Confidence" SG_ 883 EPAS3P_steeringRackForce 1;
BA_ "GenSigSNA" SG_ 883 EPAS3P_steeringRackForce "1023";
BA_ "Confidence" SG_ 883 EPAS3P_steeringFault 1;
BA_ "Confidence" SG_ 883 EPAS3P_steeringReduced 1;
BA_ "Confidence" SG_ 883 EPAS3P_internalSASQF 1;
BA_ "Confidence" SG_ 883 EPAS3P_currentTuneMode 1;
BA_ "Confidence" SG_ 883 EPAS3P_torsionBarTorque 1;
BA_ "GenSigSNA" SG_ 883 EPAS3P_torsionBarTorque "4095";
BA_ "Confidence" SG_ 883 EPAS3P_eacErrorCode 1;
BA_ "GenSigSNA" SG_ 883 EPAS3P_eacErrorCode "15";
BA_ "Confidence" SG_ 883 EPAS3P_internalSAS 1;
BA_ "Confidence" SG_ 883 EPAS3P_handsOnLevel 1;
BA_ "Confidence" SG_ 883 EPAS3P_eacStatus 1;
BA_ "Confidence" SG_ 882 EPAS3S_steeringRackForce 1;
BA_ "GenSigSNA" SG_ 882 EPAS3S_steeringRackForce "1023";
BA_ "Confidence" SG_ 882 EPAS3S_steeringFault 1;
BA_ "Confidence" SG_ 882 EPAS3S_steeringReduced 1;
BA_ "Confidence" SG_ 882 EPAS3S_internalSASQF 1;
BA_ "Confidence" SG_ 882 EPAS3S_currentTuneMode 1;
BA_ "Confidence" SG_ 882 EPAS3S_torsionBarTorque 1;
BA_ "GenSigSNA" SG_ 882 EPAS3S_torsionBarTorque "4095";
BA_ "Confidence" SG_ 882 EPAS3S_eacErrorCode 1;
BA_ "GenSigSNA" SG_ 882 EPAS3S_eacErrorCode "15";
BA_ "Confidence" SG_ 882 EPAS3S_internalSAS 1;
BA_ "Confidence" SG_ 882 EPAS3S_handsOnLevel 1;
BA_ "Confidence" SG_ 882 EPAS3S_eacStatus 1;
BA_ "Confidence" SG_ 681 EPBL_systemStatus 0;
BA_ "Confidence" SG_ 681 EPBL_freeRollModeStatus 0;
BA_ "Confidence" SG_ 681 EPBL_driverIsLeaving 0;
BA_ "Confidence" SG_ 681 EPBL_driverIsLeavingAnySpeed 0;
BA_ "Confidence" SG_ 681 EPBL_systemCdpAvailable 0;
BA_ "Confidence" SG_ 681 EPBL_chimeRequest 0;
BA_ "Confidence" SG_ 681 EPBL_telltale 0;
BA_ "GenSigSNA" SG_ 681 EPBL_telltale "7";
BA_ "Confidence" SG_ 681 EPBL_contactorCycleNotNeededForW 0;
BA_ "SystemSignalLongSymbol" SG_ 681 EPBL_contactorCycleNotNeededForW "EPBL_contactorCycleNotNeededForWinchEntry";
BA_ "Confidence" SG_ 681 EPBL_redundantBrakingEnabled 0;
BA_ "Confidence" SG_ 681 EPBL_summonEnabled 0;
BA_ "Confidence" SG_ 681 EPBL_brakeLight 0;
BA_ "Confidence" SG_ 681 EPBL_epbConfigMismatch 0;
BA_ "Confidence" SG_ 681 EPBL_brakeConfirmedPressed 0;
BA_ "Confidence" SG_ 681 EPBL_requestUserConfirmation 0;
BA_ "Confidence" SG_ 681 EPBL_uiWinchModeMiscBlocking 0;
BA_ "Confidence" SG_ 681 EPBL_winchModeActive 0;
BA_ "Confidence" SG_ 681 EPBL_updateMode 0;
BA_ "Confidence" SG_ 681 EPBL_winchModePermissive 0;
BA_ "Confidence" SG_ 681 EPBL_winchModePending 0;
BA_ "Confidence" SG_ 681 EPBL_cdpRequest 0;
BA_ "Confidence" SG_ 681 EPBL_uiParkAvailable 0;
BA_ "Confidence" SG_ 681 EPBL_brakeDiscWipeRequest 0;
BA_ "GenSigSNA" SG_ 681 EPBL_brakeDiscWipeRequest "3";
BA_ "Confidence" SG_ 681 EPBL_showUiGearShifter 0;
BA_ "Confidence" SG_ 681 EPBL_uiWinchModeLvStatus 0;
BA_ "Confidence" SG_ 681 EPBL_showStalkFaultedOnUi 0;
BA_ "Confidence" SG_ 681 EPBL_espPowerRequest 0;
BA_ "Confidence" SG_ 681 EPBL_okToPark 0;
BA_ "Confidence" SG_ 681 EPBL_hornRequest 0;
BA_ "Confidence" SG_ 681 EPBL_winchModeAvailable 0;
BA_ "Confidence" SG_ 681 EPBL_bothDisconnected 0;
BA_ "Confidence" SG_ 681 EPBL_blockDrive 0;
BA_ "Confidence" SG_ 681 EPBL_statusCounter 0;
BA_ "Confidence" SG_ 681 EPBL_statusChecksum 0;
BA_ "Confidence" SG_ 742 EPBR_frontSeatCushionFanCur 0;
BA_ "Confidence" SG_ 742 EPBR_frontSeatBackrestFanCur 0;
BA_ "Confidence" SG_ 742 EPBR_frontSeatCushionFanDuty 0;
BA_ "Confidence" SG_ 742 EPBR_frontSeatCushionFanEn 0;
BA_ "Confidence" SG_ 742 EPBR_frontSeatBackrestFanEn 0;
BA_ "Confidence" SG_ 742 EPBR_frontSeatBackrestFanDuty 0;
BA_ "Confidence" SG_ 744 EPBR_systemStatus 0;
BA_ "Confidence" SG_ 744 EPBR_freeRollModeStatus 0;
BA_ "Confidence" SG_ 744 EPBR_driverIsLeaving 0;
BA_ "Confidence" SG_ 744 EPBR_driverIsLeavingAnySpeed 0;
BA_ "Confidence" SG_ 744 EPBR_systemCdpAvailable 0;
BA_ "Confidence" SG_ 744 EPBR_chimeRequest 0;
BA_ "Confidence" SG_ 744 EPBR_telltale 0;
BA_ "GenSigSNA" SG_ 744 EPBR_telltale "7";
BA_ "Confidence" SG_ 744 EPBR_audioCurrentSpikeDetected 0;
BA_ "Confidence" SG_ 744 EPBR_redundantBrakingEnabled 0;
BA_ "Confidence" SG_ 744 EPBR_summonEnabled 0;
BA_ "Confidence" SG_ 744 EPBR_brakeLight 0;
BA_ "Confidence" SG_ 744 EPBR_epbConfigMismatch 0;
BA_ "Confidence" SG_ 744 EPBR_brakeConfirmedPressed 0;
BA_ "Confidence" SG_ 744 EPBR_requestUserConfirmation 0;
BA_ "Confidence" SG_ 744 EPBR_uiWinchModeMiscBlocking 0;
BA_ "Confidence" SG_ 744 EPBR_winchModeActive 0;
BA_ "Confidence" SG_ 744 EPBR_updateMode 0;
BA_ "Confidence" SG_ 744 EPBR_winchModePermissive 0;
BA_ "Confidence" SG_ 744 EPBR_winchModePending 0;
BA_ "Confidence" SG_ 744 EPBR_cdpRequest 0;
BA_ "Confidence" SG_ 744 EPBR_uiParkAvailable 0;
BA_ "Confidence" SG_ 744 EPBR_brakeDiscWipeRequest 0;
BA_ "GenSigSNA" SG_ 744 EPBR_brakeDiscWipeRequest "3";
BA_ "Confidence" SG_ 744 EPBR_showUiGearShifter 0;
BA_ "Confidence" SG_ 744 EPBR_uiWinchModeLvStatus 0;
BA_ "Confidence" SG_ 744 EPBR_contactorCycleNotNeededForW 0;
BA_ "SystemSignalLongSymbol" SG_ 744 EPBR_contactorCycleNotNeededForW "EPBR_contactorCycleNotNeededForWinchEntry";
BA_ "Confidence" SG_ 744 EPBR_showStalkFaultedOnUi 0;
BA_ "Confidence" SG_ 744 EPBR_espPowerRequest 0;
BA_ "Confidence" SG_ 744 EPBR_okToPark 0;
BA_ "Confidence" SG_ 744 EPBR_hornRequest 0;
BA_ "Confidence" SG_ 744 EPBR_winchModeAvailable 0;
BA_ "Confidence" SG_ 744 EPBR_bothDisconnected 0;
BA_ "Confidence" SG_ 744 EPBR_blockDrive 0;
BA_ "Confidence" SG_ 744 EPBR_statusCounter 0;
BA_ "Confidence" SG_ 744 EPBR_statusChecksum 0;
BA_ "Confidence" SG_ 888 GTW_GTW_SOS_ECALL_RQST 0;
BA_ "Confidence" SG_ 888 GTW_LTE_ECALL_LOCK 0;
BA_ "Confidence" SG_ 282 GTW_BKP_BATT_MON 1;
BA_ "GenSigSNA" SG_ 282 GTW_BKP_BATT_MON "4095";
BA_ "Confidence" SG_ 282 GTW_BKP_BATT_NTC_P 1;
BA_ "GenSigSNA" SG_ 282 GTW_BKP_BATT_NTC_P "4095";
BA_ "Confidence" SG_ 282 GTW_ECALL_GPS_ANT_BIAS 1;
BA_ "GenSigSNA" SG_ 282 GTW_ECALL_GPS_ANT_BIAS "4095";
BA_ "Confidence" SG_ 282 GTW_ECALL_MIC_DIAG 1;
BA_ "GenSigSNA" SG_ 282 GTW_ECALL_MIC_DIAG "4095";
BA_ "Confidence" SG_ 282 GTW_SOS_ECALL_nRQST_BUF 1;
BA_ "GenSigSNA" SG_ 282 GTW_SOS_ECALL_nRQST_BUF "4095";
BA_ "Confidence" SG_ 838 GTW_autopilotOverrideState 1;
BA_ "Confidence" SG_ 838 GTW_autopilotConfig 1;
BA_ "Confidence" SG_ 838 GTW_autopilotOverrideConfig 1;
BA_ "Confidence" SG_ 838 GTW_autopilotOverrideExpireTime 0;
BA_ "Confidence" SG_ 904 GTW_VEH_canBusActivity 0;
BA_ "Confidence" SG_ 904 GTW_PARTY_canBusActivity 0;
BA_ "Confidence" SG_ 904 GTW_CH_canBusActivity 0;
BA_ "Confidence" SG_ 904 GTW_VEH_txWarning 0;
BA_ "Confidence" SG_ 904 GTW_PARTY_txWarning 0;
BA_ "Confidence" SG_ 904 GTW_CH_txWarning 0;
BA_ "Confidence" SG_ 904 GTW_VEH_rxWarning 0;
BA_ "Confidence" SG_ 904 GTW_PARTY_rxWarning 0;
BA_ "Confidence" SG_ 904 GTW_CH_rxWarning 0;
BA_ "Confidence" SG_ 904 GTW_VEH_faultConfinement 0;
BA_ "Confidence" SG_ 904 GTW_PARTY_faultConfinement 0;
BA_ "Confidence" SG_ 904 GTW_CH_faultConfinement 0;
BA_ "Confidence" SG_ 2047 GTW_deliveryStatus 0;
BA_ "Confidence" SG_ 2047 GTW_cabinPTCHeaterType 0;
BA_ "Confidence" SG_ 2047 GTW_rightHandDrive 0;
BA_ "Confidence" SG_ 2047 GTW_rearLightType 0;
BA_ "Confidence" SG_ 2047 GTW_headlamps 0;
BA_ "Confidence" SG_ 2047 GTW_country 0;
BA_ "Confidence" SG_ 2047 GTW_tireType 0;
BA_ "Confidence" SG_ 2047 GTW_roofGlassType 1;
BA_ "Confidence" SG_ 2047 GTW_dasHw 0;
BA_ "Confidence" SG_ 2047 GTW_brakeHWType 0;
BA_ "Confidence" SG_ 2047 GTW_restraintsHardwareType 0;
BA_ "Confidence" SG_ 2047 GTW_drivetrainType 0;
BA_ "Confidence" SG_ 2047 GTW_radarHeaterType 0;
BA_ "Confidence" SG_ 2047 GTW_exteriorTrimType 0;
BA_ "Confidence" SG_ 2047 GTW_frontSeatHeaters 0;
BA_ "Confidence" SG_ 2047 GTW_rearSeatHeaters 0;
BA_ "Confidence" SG_ 2047 GTW_eCallAntennaHW 0;
BA_ "Confidence" SG_ 2047 GTW_homelinkType 0;
BA_ "Confidence" SG_ 2047 GTW_vdcType 0;
BA_ "Confidence" SG_ 2047 GTW_memoryMirrors 0;
BA_ "Confidence" SG_ 2047 GTW_powerLiftgateType 0;
BA_ "Confidence" SG_ 2047 GTW_lumbarECUType 0;
BA_ "Confidence" SG_ 2047 GTW_rearSeatHeaterType 0;
BA_ "Confidence" SG_ 2047 GTW_auxParkLamps 0;
BA_ "Confidence" SG_ 2047 GTW_interiorCabinRadarType 0;
BA_ "Confidence" SG_ 2047 GTW_hvacPanelVaneType 0;
BA_ "Confidence" SG_ 2047 GTW_intakeAirFilterType 0;
BA_ "Confidence" SG_ 2047 GTW_eBuckConfig 0;
BA_ "Confidence" SG_ 2047 GTW_steeringHeaterEnabled 0;
BA_ "Confidence" SG_ 2047 GTW_activeHighBeam 0;
BA_ "Confidence" SG_ 2047 GTW_airbagCutoffSwitch 0;
BA_ "Confidence" SG_ 2047 GTW_intrusionSensorType 0;
BA_ "Confidence" SG_ 2047 GTW_spoilerType 0;
BA_ "Confidence" SG_ 2047 GTW_rearFogLamps 0;
BA_ "Confidence" SG_ 2047 GTW_roofType 0;
BA_ "Confidence" SG_ 2047 GTW_thirdRowSeatType 0;
BA_ "Confidence" SG_ 2047 GTW_autopilot 0;
BA_ "Confidence" SG_ 2047 GTW_superchargingAccess 0;
BA_ "Confidence" SG_ 2047 GTW_exteriorColor 0;
BA_ "Confidence" SG_ 2047 GTW_pedestrianWarningSound 0;
BA_ "Confidence" SG_ 2047 GTW_steeringColumnUJointType 0;
BA_ "Confidence" SG_ 2047 GTW_bPillarNFCParam 0;
BA_ "Confidence" SG_ 2047 GTW_interiorLighting 0;
BA_ "Confidence" SG_ 2047 GTW_headlightLevelerType 0;
BA_ "Confidence" SG_ 2047 GTW_numberHVILNodes 0;
BA_ "Confidence" SG_ 2047 GTW_mapRegion 0;
BA_ "Confidence" SG_ 2047 GTW_performancePackage 0;
BA_ "Confidence" SG_ 2047 GTW_chassisType 0;
BA_ "Confidence" SG_ 2047 GTW_airSuspension 0;
BA_ "Confidence" SG_ 2047 GTW_centerConsoleControllerType 0;
BA_ "Confidence" SG_ 2047 GTW_autopilotCameraType 0;
BA_ "Confidence" SG_ 2047 GTW_connectivityPackage 0;
BA_ "Confidence" SG_ 2047 GTW_plcSupportType 0;
BA_ "Confidence" SG_ 2047 GTW_packEnergy 0;
BA_ "Confidence" SG_ 2047 GTW_frontSeatReclinerHardware 0;
BA_ "Confidence" SG_ 2047 GTW_brakeLineSwitchType 0;
BA_ "Confidence" SG_ 2047 GTW_softRange 0;
BA_ "Confidence" SG_ 2047 GTW_refrigerantType 0;
BA_ "Confidence" SG_ 2047 GTW_wheelType 0;
BA_ "Confidence" SG_ 2047 GTW_brakeActuationType 0;
BA_ "Confidence" SG_ 2047 GTW_secondRowSeatType 0;
BA_ "Confidence" SG_ 2047 GTW_secondRowSeatMotorType 0;
BA_ "Confidence" SG_ 2047 GTW_birthday 0;
BA_ "Confidence" SG_ 2047 GTW_eCallEnabled 0;
BA_ "Confidence" SG_ 2047 GTW_parkAssistECUType 0;
BA_ "Confidence" SG_ 2047 GTW_passengerAirbagType 0;
BA_ "Confidence" SG_ 2047 GTW_forwardRadarHw 0;
BA_ "Confidence" SG_ 2047 GTW_frontSeatType 0;
BA_ "Confidence" SG_ 2047 GTW_secondRowDisplayType 0;
BA_ "Confidence" SG_ 2047 GTW_wirelessPhoneChargerType 0;
BA_ "Confidence" SG_ 2047 GTW_ethernetTunerType 0;
BA_ "Confidence" SG_ 2047 GTW_interiorTrimType 0;
BA_ "Confidence" SG_ 2047 GTW_gloveboxUSBType 0;
BA_ "Confidence" SG_ 2047 GTW_coolantPumpType 0;
BA_ "Confidence" SG_ 2047 GTW_epblHwType 0;
BA_ "Confidence" SG_ 2047 GTW_epbrHwType 0;
BA_ "Confidence" SG_ 2047 GTW_blowerMotorType 0;
BA_ "Confidence" SG_ 2047 GTW_frontUsbHubType 0;
BA_ "Confidence" SG_ 2047 GTW_superManifoldType 0;
BA_ "Confidence" SG_ 2047 GTW_rcmLocation 0;
BA_ "Confidence" SG_ 2047 GTW_interiorCamFanType 1;
BA_ "Confidence" SG_ 2047 GTW_sirenType 0;
BA_ "Confidence" SG_ 2047 GTW_hornType 0;
BA_ "Confidence" SG_ 2047 GTW_badgingVersion 1;
BA_ "Confidence" SG_ 2047 GTW_steeringColumnMotorType 0;
BA_ "Confidence" SG_ 2047 GTW_refrigACLineType 0;
BA_ "Confidence" SG_ 2047 GTW_refrigFilterType 0;
BA_ "Confidence" SG_ 2047 GTW_diBurnInType 0;
BA_ "Confidence" SG_ 2047 GTW_specialBadgingType 0;
BA_ "Confidence" SG_ 2047 GTW_chassisSubType 1;
BA_ "Confidence" SG_ 2047 GTW_frontSeatVentilationType 1;
BA_ "Confidence" SG_ 2047 GTW_towPackage 0;
BA_ "Confidence" SG_ 2047 GTW_refrigLccType 0;
BA_ "Confidence" SG_ 2047 GTW_caliperColorType 0;
BA_ "Confidence" SG_ 2047 GTW_wiperMotorType 0;
BA_ "Confidence" SG_ 2047 GTW_frontOverheadConsoleType 0;
BA_ "Confidence" SG_ 2047 GTW_shifterType 0;
BA_ "Confidence" SG_ 2047 GTW_compressorType 0;
BA_ "Confidence" SG_ 2047 GTW_twelveVBatteryType 0;
BA_ "Confidence" SG_ 2047 GTW_efuseSWConfig 0;
BA_ "Confidence" SG_ 2047 GTW_tollCollectionModuleType 0;
BA_ "Confidence" SG_ 2047 GTW_bleEndpointUpdateMethod 0;
BA_ "Confidence" SG_ 2047 GTW_steeringWheelControllerType 0;
BA_ "Confidence" SG_ 2047 GTW_frontSeatVentilationEnabled 0;
BA_ "Confidence" SG_ 2047 GTW_gloveboxActuatorType 0;
BA_ "Confidence" SG_ 2047 GTW_epasType 0;
BA_ "Confidence" SG_ 2047 GTW_homologationRegionOverride 0;
BA_ "Confidence" SG_ 2047 GTW_windowCommandsPermissionType 0;
BA_ "Confidence" SG_ 2047 GTW_rgbInteriorLightingEnabled 0;
BA_ "Confidence" SG_ 2047 GTW_windshieldWiperHeaterType 0;
BA_ "Confidence" SG_ 2047 GTW_driveInterfaceType 0;
BA_ "Confidence" SG_ 2047 GTW_efficiencyPackage 0;
BA_ "Confidence" SG_ 2047 GTW_visorLightType 0;
BA_ "Confidence" SG_ 2047 GTW_gnssAntennaType 0;
BA_ "Confidence" SG_ 2047 GTW_frontSeatHeatersEnabled 0;
BA_ "Confidence" SG_ 2047 GTW_windshieldWiperHeaterEnabled 0;
BA_ "Confidence" SG_ 2047 GTW_tcuType 1;
BA_ "Confidence" SG_ 2047 GTW_fasciaType 0;
BA_ "Confidence" SG_ 2047 GTW_powerSteeringColumn 0;
BA_ "Confidence" SG_ 2047 GTW_frontSeatHeaterType 0;
BA_ "Confidence" SG_ 2047 GTW_softPerformanceLimit 0;
BA_ "Confidence" SG_ 2047 GTW_alcoholInterlockType 1;
BA_ "Confidence" SG_ 2047 GTW_immersiveAudio 0;
BA_ "Confidence" SG_ 2047 GTW_passengerOccupancySensorType 0;
BA_ "Confidence" SG_ 2047 GTW_packPerformanceDeviation 0;
BA_ "Confidence" SG_ 2047 GTW_frontFogLamps 0;
BA_ "Confidence" SG_ 2047 GTW_driverOccupancySensorType 0;
BA_ "Confidence" SG_ 2047 GTW_audioType 0;
BA_ "Confidence" SG_ 2047 GTW_occupancyClassificationFeatu 0;
BA_ "SystemSignalLongSymbol" SG_ 2047 GTW_occupancyClassificationFeatu "GTW_occupancyClassificationFeatureType";
BA_ "Confidence" SG_ 2047 GTW_domeLightType 0;
BA_ "Confidence" SG_ 2047 GTW_tpmsType 0;
BA_ "Confidence" SG_ 2047 GTW_authenticationEndpointLayout 0;
BA_ "Confidence" SG_ 2047 GTW_socSleepOverride 0;
BA_ "Confidence" SG_ 2047 GTW_r79BehaviorOverride 0;
BA_ "Confidence" SG_ 2047 GTW_steeringHeaterType 0;
BA_ "Confidence" SG_ 2047 GTW_sohRegulatoryStatus 0;
BA_ "Confidence" SG_ 2047 GTW_m3yBusArchitecture 0;
BA_ "Confidence" SG_ 2047 GTW_blindSpotIndicatorLightType 1;
BA_ "Confidence" SG_ 2047 GTW_hvacCaseDoorType 0;
BA_ "Confidence" SG_ 2047 GTW_rduCableType 0;
BA_ "Confidence" SG_ 2047 GTW_interiorCameraType 0;
BA_ "Confidence" SG_ 2047 GTW_frontFasciaCameraType 0;
BA_ "Confidence" SG_ 1638 GTW_diagRemainingSeconds 0;
BA_ "Confidence" SG_ 1638 GTW_diagSessionActive 0;
BA_ "Confidence" SG_ 1638 GTW_diagLevel 0;
BA_ "Confidence" SG_ 1638 GTW_diagUnlockProcedureActive 0;
BA_ "Confidence" SG_ 1638 GTW_diagOverrideActive 0;
BA_ "Confidence" SG_ 1638 GTW_diagPhysicalLinkEstablished 0;
BA_ "Confidence" SG_ 1080 GTW_ethGotoSleep 0;
BA_ "Confidence" SG_ 1080 GTW_ethWakeUpBus 0;
BA_ "Confidence" SG_ 1080 GTW_vehBusAsleep 0;
BA_ "Confidence" SG_ 1080 GTW_ethHeartBeatCounter 0;
BA_ "Confidence" SG_ 1080 GTW_ethWakeUpReason 1;
BA_ "Confidence" SG_ 1656 GTW_gearControlChecksum 0;
BA_ "Confidence" SG_ 1656 GTW_gearControlCounter 0;
BA_ "Confidence" SG_ 1656 GTW_gearShiftRequest 0;
BA_ "GenSigSNA" SG_ 1656 GTW_gearShiftRequest "0";
BA_ "Confidence" SG_ 1656 GTW_osdActive 0;
BA_ "Confidence" SG_ 1656 GTW_primaryGearControlStatus 0;
BA_ "Confidence" SG_ 1656 GTW_gearStripEnable 0;
BA_ "Confidence" SG_ 1656 GTW_showNeutralButton 0;
BA_ "Confidence" SG_ 1656 GTW_showAutoParkButton 0;
BA_ "Confidence" SG_ 1656 GTW_autoParkRequest 0;
BA_ "Confidence" SG_ 1656 GTW_smartShiftStatus 0;
BA_ "GenSigSNA" SG_ 1656 GTW_smartShiftStatus "0";
BA_ "Confidence" SG_ 1656 GTW_processingRDgestures 0;
BA_ "Confidence" SG_ 1656 GTW_processingTapPgestures 0;
BA_ "Confidence" SG_ 1656 GTW_gearStripChangeReason 0;
BA_ "GenSigSNA" SG_ 1656 GTW_gearStripChangeReason "0";
BA_ "Confidence" SG_ 1656 GTW_touchActive 0;
BA_ "Confidence" SG_ 1656 GTW_steamOff 0;
BA_ "Confidence" SG_ 1656 GTW_screenPCBTemperature 1;
BA_ "GenSigSNA" SG_ 1656 GTW_screenPCBTemperature "2047";
BA_ "Confidence" SG_ 2033 GTW_hrlIndex 1;
BA_ "Confidence" SG_ 2033 GTW_hrlState 0;
BA_ "Confidence" SG_ 2033 GTW_hrlTriggerDuration 1;
BA_ "Confidence" SG_ 2033 GTW_hrlTriggerType 0;
BA_ "Confidence" SG_ 2033 GTW_hrlTriggerId 1;
BA_ "Confidence" SG_ 60 GTW_infoIndex 1;
BA_ "Confidence" SG_ 60 GTW_buildType 0;
BA_ "Confidence" SG_ 60 GTW_hardwareId 0;
BA_ "Confidence" SG_ 60 GTW_platformType 0;
BA_ "Confidence" SG_ 60 GTW_appCrc 0;
BA_ "Confidence" SG_ 60 GTW_applicationGitHash 0;
BA_ "Confidence" SG_ 60 GTW_bootGitHash 0;
BA_ "Confidence" SG_ 1370 GTW_mismatchFaultIndex 1;
BA_ "Confidence" SG_ 1370 GTW_mismatchFaultChecksum 0;
BA_ "Confidence" SG_ 1370 GTW_mismatchFaultCounter 0;
BA_ "Confidence" SG_ 1370 GTW_GTWmismatchFault 0;
BA_ "Confidence" SG_ 1370 GTW_BMSmismatchFault 0;
BA_ "Confidence" SG_ 1370 GTW_APSmismatchFault 0;
BA_ "Confidence" SG_ 1370 GTW_BLEEPCENTERmismatchFault 0;
BA_ "Confidence" SG_ 1370 GTW_BLEEPLEFTmismatchFault 0;
BA_ "Confidence" SG_ 1370 GTW_BLEEPREARmismatchFault 0;
BA_ "Confidence" SG_ 1370 GTW_BLEEPRIGHTmismatchFault 0;
BA_ "Confidence" SG_ 1370 GTW_CBCmismatchFault 0;
BA_ "Confidence" SG_ 1370 GTW_CMPmismatchFault 0;
BA_ "Confidence" SG_ 1370 GTW_CPmismatchFault 0;
BA_ "Confidence" SG_ 1370 GTW_DIFmismatchFault 0;
BA_ "Confidence" SG_ 1370 GTW_DIRmismatchFault 0;
BA_ "Confidence" SG_ 1370 GTW_EPAS3PmismatchFault 0;
BA_ "Confidence" SG_ 1370 GTW_EPAS3SmismatchFault 0;
BA_ "Confidence" SG_ 1370 GTW_EPBLmismatchFault 0;
BA_ "Confidence" SG_ 1370 GTW_EPBRmismatchFault 0;
BA_ "Confidence" SG_ 1370 GTW_ESPCALmismatchFault 0;
BA_ "Confidence" SG_ 1370 GTW_ESPmismatchFault 0;
BA_ "Confidence" SG_ 1370 GTW_HCM3LmismatchFault 0;
BA_ "Confidence" SG_ 1370 GTW_HCM3RmismatchFault 0;
BA_ "Confidence" SG_ 1370 GTW_HCMLmismatchFault 0;
BA_ "Confidence" SG_ 1370 GTW_HCMRmismatchFault 0;
BA_ "Confidence" SG_ 1370 GTW_HVPmismatchFault 0;
BA_ "Confidence" SG_ 1370 GTW_IBSTCALmismatchFault 0;
BA_ "Confidence" SG_ 1370 GTW_IBSTmismatchFault 0;
BA_ "Confidence" SG_ 1370 GTW_LVBMSmismatchFault 0;
BA_ "Confidence" SG_ 1370 GTW_OCS1PmismatchFault 0;
BA_ "Confidence" SG_ 1370 GTW_OPCFmismatchFault 0;
BA_ "Confidence" SG_ 1370 GTW_OPCRmismatchFault 0;
BA_ "Confidence" SG_ 1370 GTW_PARKmismatchFault 0;
BA_ "Confidence" SG_ 1370 GTW_PCSCPU2mismatchFault 0;
BA_ "Confidence" SG_ 1370 GTW_PCSmismatchFault 0;
BA_ "Confidence" SG_ 1370 GTW_PMFmismatchFault 0;
BA_ "Confidence" SG_ 1370 GTW_PMRmismatchFault 0;
BA_ "Confidence" SG_ 1370 GTW_PTCmismatchFault 0;
BA_ "Confidence" SG_ 1370 GTW_RCMCALmismatchFault 0;
BA_ "Confidence" SG_ 1370 GTW_RCMmismatchFault 0;
BA_ "Confidence" SG_ 1370 GTW_SCCMmismatchFault 0;
BA_ "Confidence" SG_ 1370 GTW_SDCRmismatchFault 0;
BA_ "Confidence" SG_ 1370 GTW_SWCmismatchFault 0;
BA_ "Confidence" SG_ 1370 GTW_THSmismatchFault 0;
BA_ "Confidence" SG_ 1370 GTW_VCFRONTmismatchFault 0;
BA_ "Confidence" SG_ 1370 GTW_VCLEFTmismatchFault 0;
BA_ "Confidence" SG_ 1370 GTW_VCRIGHTmismatchFault 0;
BA_ "Confidence" SG_ 1370 GTW_VCSECmismatchFault 0;
BA_ "Confidence" SG_ 1370 GTW_PMmismatchFault 0;
BA_ "Confidence" SG_ 840 GTW_vehicleVersionMatchStatus 0;
BA_ "Confidence" SG_ 840 GTW_hwtype 0;
BA_ "GenSigSNA" SG_ 840 GTW_hwtype "0";
BA_ "Confidence" SG_ 840 GTW_jcanProductName 0;
BA_ "GenSigSNA" SG_ 840 GTW_jcanProductName "0";
BA_ "Confidence" SG_ 840 GTW_uptimeSeconds 1;
BA_ "Confidence" SG_ 840 GTW_boardRevision 0;
BA_ "Confidence" SG_ 840 GTW_sentryModeState 1;
BA_ "GenSigSNA" SG_ 840 GTW_sentryModeState "6";
BA_ "Confidence" SG_ 840 GTW_socSleepType 0;
BA_ "GenSigSNA" SG_ 840 GTW_socSleepType "0";
BA_ "Confidence" SG_ 840 GTW_resetType 1;
BA_ "GenSigSNA" SG_ 840 GTW_resetType "0";
BA_ "Confidence" SG_ 1005 GTW_ecuUpdateStarted 0;
BA_ "Confidence" SG_ 1005 GTW_updateStarted 1;
BA_ "Confidence" SG_ 1112 GTW_nmGoingToSleep 0;
BA_ "Confidence" SG_ 1112 GTW_nmWakeUpBus 0;
BA_ "Confidence" SG_ 1112 GTW_chBusAsleep 0;
BA_ "Confidence" SG_ 1112 GTW_ethBusAsleep 0;
BA_ "Confidence" SG_ 1112 GTW_nmKeepAwakeReason 0;
BA_ "GenSigSNA" SG_ 1112 GTW_nmKeepAwakeReason "0";
BA_ "Confidence" SG_ 1112 GTW_nmWakeUpReason 1;
BA_ "Confidence" SG_ 1112 GTW_ethKeepAwakeReason 1;
BA_ "GenSigSNA" SG_ 1112 GTW_ethKeepAwakeReason "0";
BA_ "Confidence" SG_ 1112 GTW_nmDebugWakeUp 1;
BA_ "Confidence" SG_ 1112 GTW_OTAKeepAwake 1;
BA_ "Confidence" SG_ 1112 GTW_smsPokeReceived 1;
VAL_ 634 DIF_hvilStatus 3 "SNA" 2 "CLOSED" 1 "OPEN" 0 "DISABLED" ;
VAL_ 634 DIF_hvilSupplyState 2 "ACTIVE" 1 "INACTIVE" 0 "NOT_AVAILABLE" ;
VAL_ 634 DIF_vBatQF 1 "QUALIFIED" 0 "NOT_QUALIFIED" ;
VAL_ 634 DIF_powerStageSafeState 3 "PSTG_SAFESTATE_3PS_LOW" 2 "PSTG_SAFESTATE_3PS_HIGH" 1 "PSTG_SAFESTATE_ALL_OFF" 0 "PSTG_SAFESTATE_NONE" ;
VAL_ 634 DIF_fluxState 12 "DI_FLUXSTATE_DISABLED" 11 "DI_FLUXSTATE_MAGNET_FLUX_DETECT" 10 "DI_FLUXSTATE_STATIONARY_WASTE" 9 "DI_FLUXSTATE_FAULT" 7 "DI_FLUXSTATE_VCONTROL" 6 "DI_FLUXSTATE_ICONTROL" 5 "DI_FLUXSTATE_ENABLED" 4 "DI_FLUXSTATE_FLUX_DOWN" 3 "DI_FLUXSTATE_FLUX_UP" 2 "DI_FLUXSTATE_STANDBY" 1 "DI_FLUXSTATE_TEST" 0 "DI_FLUXSTATE_START" ;
VAL_ 634 DIF_gateDriveState 4 "PSTG_GD_STATE_NOT_CONFIGURED" 3 "PSTG_GD_STATE_CONFIGURED" 2 "PSTG_GD_STATE_CONFIGURING" 1 "PSTG_GD_STATE_SELFTEST" 0 "PSTG_GD_STATE_INIT" ;
VAL_ 1622 DIF_infoIndex 255 "INFO_END" 44 "TRACKING_DATA_5" 43 "TRACKING_DATA_4" 42 "TRACKING_DATA_3" 41 "TRACKING_DATA_2" 40 "TRACKING_DATA_1" 34 "INFO_SUBCOMPONENT2_HWID" 33 "INFO_SUBCOMPONENT_HWID" 32 "INFO_SUBCOMPONENT2_GITHASH" 31 "INFO_SUBCOMPONENT_GITHASH" 23 "INFO_SUBCOMPONENT2" 20 "INFO_UDS_PROTOCOL_BOOTCRC" 19 "INFO_VERSION_DEPRECATED" 18 "INFO_BOOTLOADER_GITHASH" 17 "INFO_APP_GITHASH" 16 "INFO_SUBCOMPONENT" 15 "INFO_BOOTLOADER_CRC" 14 "INFO_BOOTLOADER_SVN" 13 "INFO_APP_CRC" 11 "INFO_PCBAID_ASSYID_USAGEID" 10 "INFO_BUILD_HWID_COMPONENTID" 9 "INFO_DEPRECATED_9" 8 "INFO_DEPRECATED_8" 7 "INFO_DEPRECATED_7" 6 "INFO_DEPRECATED_6" 5 "INFO_DEPRECATED_5" 4 "INFO_DEPRECATED_4" 3 "INFO_DEPRECATED_3" 2 "INFO_DEPRECATED_2" 1 "INFO_DEPRECATED_1" 0 "INFO_DEPRECATED_0" ;
VAL_ 1622 DIF_buildType 4 "INFO_MFG_BUILD" 3 "INFO_TRACEABLE_CI_BUILD" 2 "INFO_LOCAL_BUILD" 1 "INFO_PLATFORM_BUILD" 0 "INFO_UNKNOWN_BUILD" ;
VAL_ 1622 DIF_hardwareId 252 "CONFIGURABLE_HWID_PLACEHOLDER" ;
VAL_ 1622 DIF_motorType 31 "DI_MOTOR_PM216E" 20 "DI_MOTOR_PM215D_1KV" 18 "DI_MOTOR_IM260E_1KV" 17 "DI_MOTOR_IM260D_1KV" 16 "DI_MOTOR_PM261C" 15 "DI_MOTOR_PM215C_1KV" 14 "DI_MOTOR_IM260C_1KV" 13 "DI_MOTOR_PM215A_1KV" 12 "DI_MOTOR_IM260A_1KV" 11 "DI_MOTOR_IM228HEA" 10 "DI_MOTOR_PM228HEA" 9 "DI_MOTOR_PM275C" 8 "DI_MOTOR_PM291D" 7 "DI_MOTOR_PM291C" 6 "DI_MOTOR_PM228C" 5 "DI_MOTOR_PM350B" 4 "DI_MOTOR_PM275B" 3 "DI_MOTOR_IM130D_AL" 2 "DI_MOTOR_IM130D" 1 "DI_MOTOR_PM216D" 0 "DI_MOTOR_SNA" ;
VAL_ 1622 DIF_siliconType 1 "IGBT" 0 "MOSFET" ;
VAL_ 1622 DIF_mechSafeStateType 2 "DI_MECH_SAFE_STATE_TYPE_PRESENT" 1 "DI_MECH_SAFE_STATE_TYPE_NONE" 0 "DI_MECH_SAFE_STATE_TYPE_SNA" ;
VAL_ 1622 DIF_oilPumpBuildType 4 "INFO_MFG_BUILD" 3 "INFO_TRACEABLE_CI_BUILD" 2 "INFO_LOCAL_BUILD" 1 "INFO_PLATFORM_BUILD" 0 "INFO_UNKNOWN_BUILD" ;
VAL_ 1622 DIF_FPGA_version 255 "SNA" 254 "LOCAL_BUILD" ;
VAL_ 1622 DIF_refRotorOffset -2048 "SNA" ;
VAL_ 1622 DIF_speedWearTotal 255 "SNA" ;
VAL_ 1622 DIF_torqueWearTotal 255 "SNA" ;
VAL_ 421 DIF_targetFluxMode 2 "DI_FLUXMODE_FW" 1 "DI_FLUXMODE_FS" 0 "DI_FLUXMODE_OPTIMUM" ;
VAL_ 725 DIF_state 4 "DI_STATE_ENABLE" 3 "DI_STATE_ABORT" 2 "DI_STATE_FAULT" 1 "DI_STATE_STANDBY" 0 "DI_STATE_UNAVAILABLE" ;
VAL_ 725 DIF_keepAliveRequest 1 "KEEP_ALIVE" 0 "NO_REQUEST" ;
VAL_ 725 DIF_soptState 9 "SOPT_DISABLED" 8 "SOPT_SNA" 7 "SOPT_TEST_FAILED" 6 "SOPT_TEST_SKIPPED" 5 "SOPT_TEST_PASSED" 4 "SOPT_CURRENT_TEST" 3 "SOPT_ASC_TEST" 2 "SOPT_PSTG_BRING_UP_AT_SPEED" 1 "SOPT_PSTG_BRING_UP" 0 "SOPT_INIT" ;
VAL_ 725 DIF_adState 3 "AD_STATE_FAULTED" 2 "AD_STATE_BACKUP" 1 "AD_STATE_NORMAL" 0 "AD_STATE_STARTUP" ;
VAL_ 725 DIF_driveModeState 1 "DM_STATE_DRIVE" 0 "DM_STATE_NONDRIVE" ;
VAL_ 725 DIF_wasteState 3 "DI_WASTE_STATIONARY" 2 "DI_WASTE_ON" 1 "DI_WASTE_AVAILABLE" 0 "DI_WASTE_UNAVAILABLE" ;
VAL_ 725 DIF_haltRequest 2 "DI_HALT_GRACEFUL" 1 "DI_HALT_IMMEDIATE" 0 "DI_HALT_NONE" ;
VAL_ 725 DIF_adDirection 1 "AD_FORWARD" 0 "AD_BACKWARD" ;
VAL_ 725 DIF_spinDownLearningState 9 "SPINDOWN_STATE_DONE" 8 "SPINDOWN_STATE_WRITE" 7 "SPINDOWN_STATE_VERIFY" 6 "SPINDOWN_STATE_CORRECT" 5 "SPINDOWN_STATE_MEASURE" 4 "SPINDOWN_STATE_COAST" 3 "SPINDOWN_STATE_ACCELERATE" 2 "SPINDOWN_STATE_WAIT" 1 "SPINDOWN_STATE_PRECHECK" 0 "SPINDOWN_STATE_INIT" ;
VAL_ 725 DIF_spinDownLearningMode 1 "SPINDOWN_MODE_ON_GROUND" 0 "SPINDOWN_MODE_ON_LIFT" ;
VAL_ 886 DIF_tempIndex 4 "Mux4" 3 "Mux3" 2 "Mux2" 1 "Mux1" 0 "Mux0" ;
VAL_ 886 DIF_inverterTQF 3 "INVERTERT_UNKNOWN" 2 "INVERTERT_RATIONAL" 1 "INVERTERT_IRRATIONAL" 0 "INVERTERT_INIT" ;
VAL_ 886 DIF_pcbT 0 "SNA" ;
VAL_ 886 DIF_statorT 0 "SNA" ;
VAL_ 886 DIF_dcCapT 0 "SNA" ;
VAL_ 886 DIF_heatsinkT 0 "SNA" ;
VAL_ 886 DIF_fluidInTemp 0 "SNA" ;
VAL_ 886 DIF_normalFetBurnIn 65535 "SNA" ;
VAL_ 886 DIF_additionalFetBurnIn 65535 "SNA" ;
VAL_ 886 DIF_currentWeibullMiles 32767 "SNA" ;
VAL_ 886 DIF_endOfServiceWeibullMiles 32767 "SNA" ;
VAL_ 886 DIF_burnInDamageRatio 511 "SNA" 510 "DEFAULT_1" ;
VAL_ 886 DIF_initialBurnInVehicleOdometer 4294967295 "SNA" ;
VAL_ 390 DIF_torqueCommand -4096 "SNA" ;
VAL_ 390 DIF_axleSpeedQF 2 "FAULTED" 1 "VALID" 0 "INVALID" ;
VAL_ 390 DIF_torqueActual -4096 "SNA" ;
VAL_ 390 DIF_axleSpeed -32768 "SNA" ;
VAL_ 390 DIF_axleTorqueQF 2 "FAULTED" 1 "VALID" 0 "INVALID" ;
VAL_ 390 DIF_axlePowerCalcQF 1 "VALID" 0 "INVALID" ;
VAL_ 633 DIR_hvilStatus 3 "SNA" 2 "CLOSED" 1 "OPEN" 0 "DISABLED" ;
VAL_ 633 DIR_hvilSupplyState 2 "ACTIVE" 1 "INACTIVE" 0 "NOT_AVAILABLE" ;
VAL_ 633 DIR_vBatQF 1 "QUALIFIED" 0 "NOT_QUALIFIED" ;
VAL_ 633 DIR_powerStageSafeState 3 "PSTG_SAFESTATE_3PS_LOW" 2 "PSTG_SAFESTATE_3PS_HIGH" 1 "PSTG_SAFESTATE_ALL_OFF" 0 "PSTG_SAFESTATE_NONE" ;
VAL_ 633 DIR_fluxState 12 "DI_FLUXSTATE_DISABLED" 11 "DI_FLUXSTATE_MAGNET_FLUX_DETECT" 10 "DI_FLUXSTATE_STATIONARY_WASTE" 9 "DI_FLUXSTATE_FAULT" 7 "DI_FLUXSTATE_VCONTROL" 6 "DI_FLUXSTATE_ICONTROL" 5 "DI_FLUXSTATE_ENABLED" 4 "DI_FLUXSTATE_FLUX_DOWN" 3 "DI_FLUXSTATE_FLUX_UP" 2 "DI_FLUXSTATE_STANDBY" 1 "DI_FLUXSTATE_TEST" 0 "DI_FLUXSTATE_START" ;
VAL_ 633 DIR_gateDriveState 4 "PSTG_GD_STATE_NOT_CONFIGURED" 3 "PSTG_GD_STATE_CONFIGURED" 2 "PSTG_GD_STATE_CONFIGURING" 1 "PSTG_GD_STATE_SELFTEST" 0 "PSTG_GD_STATE_INIT" ;
VAL_ 821 DIR_infoIndex 255 "INFO_END" 44 "TRACKING_DATA_5" 43 "TRACKING_DATA_4" 42 "TRACKING_DATA_3" 41 "TRACKING_DATA_2" 40 "TRACKING_DATA_1" 34 "INFO_SUBCOMPONENT2_HWID" 33 "INFO_SUBCOMPONENT_HWID" 32 "INFO_SUBCOMPONENT2_GITHASH" 31 "INFO_SUBCOMPONENT_GITHASH" 23 "INFO_SUBCOMPONENT2" 20 "INFO_UDS_PROTOCOL_BOOTCRC" 19 "INFO_VERSION_DEPRECATED" 18 "INFO_BOOTLOADER_GITHASH" 17 "INFO_APP_GITHASH" 16 "INFO_SUBCOMPONENT" 15 "INFO_BOOTLOADER_CRC" 14 "INFO_BOOTLOADER_SVN" 13 "INFO_APP_CRC" 11 "INFO_PCBAID_ASSYID_USAGEID" 10 "INFO_BUILD_HWID_COMPONENTID" 9 "INFO_DEPRECATED_9" 8 "INFO_DEPRECATED_8" 7 "INFO_DEPRECATED_7" 6 "INFO_DEPRECATED_6" 5 "INFO_DEPRECATED_5" 4 "INFO_DEPRECATED_4" 3 "INFO_DEPRECATED_3" 2 "INFO_DEPRECATED_2" 1 "INFO_DEPRECATED_1" 0 "INFO_DEPRECATED_0" ;
VAL_ 821 DIR_buildType 4 "INFO_MFG_BUILD" 3 "INFO_TRACEABLE_CI_BUILD" 2 "INFO_LOCAL_BUILD" 1 "INFO_PLATFORM_BUILD" 0 "INFO_UNKNOWN_BUILD" ;
VAL_ 821 DIR_hardwareId 252 "CONFIGURABLE_HWID_PLACEHOLDER" ;
VAL_ 821 DIR_motorType 31 "DI_MOTOR_PM216E" 20 "DI_MOTOR_PM215D_1KV" 18 "DI_MOTOR_IM260E_1KV" 17 "DI_MOTOR_IM260D_1KV" 16 "DI_MOTOR_PM261C" 15 "DI_MOTOR_PM215C_1KV" 14 "DI_MOTOR_IM260C_1KV" 13 "DI_MOTOR_PM215A_1KV" 12 "DI_MOTOR_IM260A_1KV" 11 "DI_MOTOR_IM228HEA" 10 "DI_MOTOR_PM228HEA" 9 "DI_MOTOR_PM275C" 8 "DI_MOTOR_PM291D" 7 "DI_MOTOR_PM291C" 6 "DI_MOTOR_PM228C" 5 "DI_MOTOR_PM350B" 4 "DI_MOTOR_PM275B" 3 "DI_MOTOR_IM130D_AL" 2 "DI_MOTOR_IM130D" 1 "DI_MOTOR_PM216D" 0 "DI_MOTOR_SNA" ;
VAL_ 821 DIR_siliconType 1 "IGBT" 0 "MOSFET" ;
VAL_ 821 DIR_mechSafeStateType 2 "DI_MECH_SAFE_STATE_TYPE_PRESENT" 1 "DI_MECH_SAFE_STATE_TYPE_NONE" 0 "DI_MECH_SAFE_STATE_TYPE_SNA" ;
VAL_ 821 DIR_oilPumpBuildType 4 "INFO_MFG_BUILD" 3 "INFO_TRACEABLE_CI_BUILD" 2 "INFO_LOCAL_BUILD" 1 "INFO_PLATFORM_BUILD" 0 "INFO_UNKNOWN_BUILD" ;
VAL_ 821 DIR_FPGA_version 255 "SNA" 254 "LOCAL_BUILD" ;
VAL_ 821 DIR_refRotorOffset -2048 "SNA" ;
VAL_ 821 DIR_speedWearTotal 255 "SNA" ;
VAL_ 821 DIR_torqueWearTotal 255 "SNA" ;
VAL_ 2039 DIR_targetFluxMode 2 "DI_FLUXMODE_FW" 1 "DI_FLUXMODE_FS" 0 "DI_FLUXMODE_OPTIMUM" ;
VAL_ 598 DIR_state 4 "DI_STATE_ENABLE" 3 "DI_STATE_ABORT" 2 "DI_STATE_FAULT" 1 "DI_STATE_STANDBY" 0 "DI_STATE_UNAVAILABLE" ;
VAL_ 598 DIR_keepAliveRequest 1 "KEEP_ALIVE" 0 "NO_REQUEST" ;
VAL_ 598 DIR_soptState 9 "SOPT_DISABLED" 8 "SOPT_SNA" 7 "SOPT_TEST_FAILED" 6 "SOPT_TEST_SKIPPED" 5 "SOPT_TEST_PASSED" 4 "SOPT_CURRENT_TEST" 3 "SOPT_ASC_TEST" 2 "SOPT_PSTG_BRING_UP_AT_SPEED" 1 "SOPT_PSTG_BRING_UP" 0 "SOPT_INIT" ;
VAL_ 598 DIR_adState 3 "AD_STATE_FAULTED" 2 "AD_STATE_BACKUP" 1 "AD_STATE_NORMAL" 0 "AD_STATE_STARTUP" ;
VAL_ 598 DIR_driveModeState 1 "DM_STATE_DRIVE" 0 "DM_STATE_NONDRIVE" ;
VAL_ 598 DIR_wasteState 3 "DI_WASTE_STATIONARY" 2 "DI_WASTE_ON" 1 "DI_WASTE_AVAILABLE" 0 "DI_WASTE_UNAVAILABLE" ;
VAL_ 598 DIR_haltRequest 2 "DI_HALT_GRACEFUL" 1 "DI_HALT_IMMEDIATE" 0 "DI_HALT_NONE" ;
VAL_ 598 DIR_adDirection 1 "AD_FORWARD" 0 "AD_BACKWARD" ;
VAL_ 598 DIR_spinDownLearningState 9 "SPINDOWN_STATE_DONE" 8 "SPINDOWN_STATE_WRITE" 7 "SPINDOWN_STATE_VERIFY" 6 "SPINDOWN_STATE_CORRECT" 5 "SPINDOWN_STATE_MEASURE" 4 "SPINDOWN_STATE_COAST" 3 "SPINDOWN_STATE_ACCELERATE" 2 "SPINDOWN_STATE_WAIT" 1 "SPINDOWN_STATE_PRECHECK" 0 "SPINDOWN_STATE_INIT" ;
VAL_ 598 DIR_spinDownLearningMode 1 "SPINDOWN_MODE_ON_GROUND" 0 "SPINDOWN_MODE_ON_LIFT" ;
VAL_ 789 DIR_tempIndex 4 "Mux4" 3 "Mux3" 2 "Mux2" 1 "Mux1" 0 "Mux0" ;
VAL_ 789 DIR_inverterTQF 3 "INVERTERT_UNKNOWN" 2 "INVERTERT_RATIONAL" 1 "INVERTERT_IRRATIONAL" 0 "INVERTERT_INIT" ;
VAL_ 789 DIR_pcbT 0 "SNA" ;
VAL_ 789 DIR_statorT 0 "SNA" ;
VAL_ 789 DIR_dcCapT 0 "SNA" ;
VAL_ 789 DIR_heatsinkT 0 "SNA" ;
VAL_ 789 DIR_fluidInTemp 0 "SNA" ;
VAL_ 789 DIR_normalFetBurnIn 65535 "SNA" ;
VAL_ 789 DIR_additionalFetBurnIn 65535 "SNA" ;
VAL_ 789 DIR_currentWeibullMiles 32767 "SNA" ;
VAL_ 789 DIR_endOfServiceWeibullMiles 32767 "SNA" ;
VAL_ 789 DIR_burnInDamageRatio 511 "SNA" 510 "DEFAULT_1" ;
VAL_ 789 DIR_initialBurnInVehicleOdometer 4294967295 "SNA" ;
VAL_ 264 DIR_torqueCommand -4096 "SNA" ;
VAL_ 264 DIR_axleSpeedQF 2 "FAULTED" 1 "VALID" 0 "INVALID" ;
VAL_ 264 DIR_torqueActual -4096 "SNA" ;
VAL_ 264 DIR_axleSpeed -32768 "SNA" ;
VAL_ 264 DIR_axleTorqueQF 2 "FAULTED" 1 "VALID" 0 "INVALID" ;
VAL_ 264 DIR_axlePowerCalcQF 1 "VALID" 0 "INVALID" ;
VAL_ 1861 DI_chassisControlVideoRequest 15 "CHASSIS_CONTROL_EVENT_15" 14 "CHASSIS_CONTROL_EVENT_14" 13 "CHASSIS_CONTROL_EVENT_13" 12 "CHASSIS_CONTROL_EVENT_12" 11 "CHASSIS_CONTROL_EVENT_11" 10 "CHASSIS_CONTROL_EVENT_10" 9 "CHASSIS_CONTROL_EVENT_9" 8 "CHASSIS_CONTROL_EVENT_8" 7 "CHASSIS_CONTROL_EVENT_7" 6 "CHASSIS_CONTROL_EVENT_6" 5 "CHASSIS_CONTROL_EVENT_5" 4 "CHASSIS_CONTROL_EVENT_4" 3 "CHASSIS_CONTROL_EVENT_3" 2 "CHASSIS_CONTROL_EVENT_2" 1 "CHASSIS_CONTROL_EVENT_1" 0 "CHASSIS_CONTROL_EVENT_NONE" ;
VAL_ 1861 DI_counterSteerTarget 2 "EXPIRED" 1 "ACTIVE" 0 "INACTIVE" ;
VAL_ 1861 DI_turnDirection 1 "VDC_TURNING_LEFT" 0 "VDC_TURNING_RIGHT" ;
VAL_ 1861 DI_oppositeBuildDirFrontAxle 1 "TRUE" 0 "FALSE" ;
VAL_ 1861 DI_oppositeBuildDirRearAxle 1 "TRUE" 0 "FALSE" ;
VAL_ 1861 DI_saturatedEffectiveness 1 "TRUE" 0 "FALSE" ;
VAL_ 1861 DI_preControlOpposingTurnDir 1 "TRUE" 0 "FALSE" ;
VAL_ 694 DI_vdcTelltaleFlash 1 "TELLTALE_ON" 0 "TELLTALE_OFF" ;
VAL_ 694 DI_vdcTelltaleOn 1 "TELLTALE_ON" 0 "TELLTALE_OFF" ;
VAL_ 694 DI_tcTelltaleFlash 1 "TELLTALE_ON" 0 "TELLTALE_OFF" ;
VAL_ 694 DI_tcTelltaleOn 1 "TELLTALE_ON" 0 "TELLTALE_OFF" ;
VAL_ 694 DI_tractionControlModeUI 7 "TC_SLIPPERY_SURFACE" 6 "TC_OFFROAD_ASSIST" 5 "TC_DYNO_MODE" 4 "TC_ROLLS_MODE" 3 "TC_DEV_MODE_2" 2 "TC_DEV_MODE_1" 1 "TC_SLIP_START" 0 "TC_NORMAL" ;
VAL_ 694 DI_ptcStateGlobalUI 3 "GLOBAL_PTC_STATE_SNA" 2 "GLOBAL_PTC_STATE_ON" 1 "GLOBAL_PTC_STATE_BACKUP" 0 "GLOBAL_PTC_STATE_FAULTED" ;
VAL_ 694 DI_btcStateUI 1 "ON" 0 "OFF" ;
VAL_ 694 DI_vehicleHoldTelltaleOn 1 "TELLTALE_ON" 0 "TELLTALE_OFF" ;
VAL_ 694 DI_slipperySurfaceOnUI 1 "SLIPPERY_SURFACE_ON" 0 "SLIPPERY_SURFACE_OFF" ;
VAL_ 694 DI_yellowBrakeTelltaleOn 1 "TELLTALE_ON" 0 "TELLTALE_OFF" ;
VAL_ 694 DI_greenABSTelltaleOn 1 "TELLTALE_ON" 0 "TELLTALE_OFF" ;
VAL_ 1866 DI_brakeFLTemp 1023 "SNA" ;
VAL_ 1866 DI_brakeFRTemp 1023 "SNA" ;
VAL_ 1866 DI_brakeRLTemp 1023 "SNA" ;
VAL_ 1866 DI_brakeRRTemp 1023 "SNA" ;
VAL_ 1623 DI_infoIndex 255 "INFO_END" 44 "TRACKING_DATA_5" 43 "TRACKING_DATA_4" 42 "TRACKING_DATA_3" 41 "TRACKING_DATA_2" 40 "TRACKING_DATA_1" 34 "INFO_SUBCOMPONENT2_HWID" 33 "INFO_SUBCOMPONENT_HWID" 32 "INFO_SUBCOMPONENT2_GITHASH" 31 "INFO_SUBCOMPONENT_GITHASH" 23 "INFO_SUBCOMPONENT2" 20 "INFO_UDS_PROTOCOL_BOOTCRC" 19 "INFO_VERSION_DEPRECATED" 18 "INFO_BOOTLOADER_GITHASH" 17 "INFO_APP_GITHASH" 16 "INFO_SUBCOMPONENT" 15 "INFO_BOOTLOADER_CRC" 14 "INFO_BOOTLOADER_SVN" 13 "INFO_APP_CRC" 11 "INFO_PCBAID_ASSYID_USAGEID" 10 "INFO_BUILD_HWID_COMPONENTID" 9 "INFO_DEPRECATED_9" 8 "INFO_DEPRECATED_8" 7 "INFO_DEPRECATED_7" 6 "INFO_DEPRECATED_6" 5 "INFO_DEPRECATED_5" 4 "INFO_DEPRECATED_4" 3 "INFO_DEPRECATED_3" 2 "INFO_DEPRECATED_2" 1 "INFO_DEPRECATED_1" 0 "INFO_DEPRECATED_0" ;
VAL_ 1623 DI_buildType 4 "INFO_MFG_BUILD" 3 "INFO_TRACEABLE_CI_BUILD" 2 "INFO_LOCAL_BUILD" 1 "INFO_PLATFORM_BUILD" 0 "INFO_UNKNOWN_BUILD" ;
VAL_ 1623 DI_hardwareId 252 "CONFIGURABLE_HWID_PLACEHOLDER" ;
VAL_ 1270 DI_doublePedalState 12 "DBL_BRKSTAND_TRQ_RAMPUP_DONE" 11 "DBL_BRKSTAND_LAUNCH" 10 "DBL_BRKSTAND_TRQ_HOLD" 9 "DBL_BRKSTAND_INIT_TRQ_RAMPUP" 8 "DBL_BRKSTAND_ARMED2" 7 "DBL_BRKSTAND_ARMED1" 6 "DBL_BRKOVR_RAMPUP" 5 "DBL_BRKOVR_RAMPDOWN" 4 "DBL_BRKPRESS_PREOVR" 3 "DBL_BRKPRESS_RAMPUP" 2 "DBL_BRKPRESS_RAMPDOWN" 1 "DBL_DRIVING" 0 "DBL_IDLE" ;
VAL_ 1270 DI_autopilotRequest 1 "DI_AP_RQST_ACTIVATE" 0 "DI_AP_RQST_IDLE" ;
VAL_ 1270 DI_rollPreventionState 7 "DI_RP_STATE_INIT" 6 "DI_RP_STATE_FAULT" 5 "DI_RP_STATE_MAX_BRAKE_TORQUE" 4 "DI_RP_STATE_HOLD" 3 "DI_RP_STATE_BUILD" 2 "DI_RP_STATE_READY" 1 "DI_RP_STATE_STANDBY" 0 "DI_RP_STATE_UNAVAILABLE" ;
VAL_ 1270 DI_regenBlendingState 3 "BLEND_FRICTION_ONLY" 2 "BLEND_ACTIVE" 1 "BLEND_STANDBY" 0 "BLEND_UNAVAILABLE" ;
VAL_ 1270 DI_pedalAssistCurveSelectForSX 15 "PEDAL_ASSIST_CURVE_15" 12 "PEDAL_ASSIST_CURVE_12" 11 "PEDAL_ASSIST_CURVE_11" 8 "PEDAL_ASSIST_CURVE_8" 6 "PEDAL_ASSIST_CURVE_6" 3 "PEDAL_ASSIST_CURVE_3" 0 "PEDAL_ASSIST_CURVE_0" ;
VAL_ 1270 DI_longitudinalControlStack 7 "VELOCITY_PROFILE_CONTROL_SUPPRESS_CANCEL" 6 "DIRECT_TORQUE_CONTROL" 5 "DIRECT_PEDAL_CONTROL" 4 "AEB_CONTROL" 3 "VELOCITY_PROFILE_CONTROL" 2 "LONC_TORQUE_PROFILER" 1 "LEGACY_CRUISE" 0 "REQUEST_SNA" ;
VAL_ 822 DI_sysDrivePowerRated 511 "SNA" ;
VAL_ 822 DI_sysRegenPowerRated 255 "SNA" ;
VAL_ 950 DI_odometer 4294967295 "SNA" ;
VAL_ 599 DI_uiSpeed 511 "DI_UI_SPEED_SNA" ;
VAL_ 599 DI_uiSpeedUnits 1 "DI_SPEED_KPH" 0 "DI_SPEED_MPH" ;
VAL_ 599 DI_vehicleSpeed 8191 "SNA" ;
VAL_ 599 DI_velocityEstimatorState 5 "VE_STATE_BACKUP_MOTOR" 4 "VE_STATE_BACKUP_WHEELS_B" 3 "VE_STATE_BACKUP_WHEELS_A" 2 "VE_STATE_WHEELS_REDUCED" 1 "VE_STATE_WHEELS_NORMAL" 0 "VE_STATE_NOT_INITIALIZED" ;
VAL_ 296 DI_vehicleSpeedLimitType 2 "POWERTRAIN" 1 "USER" 0 "NONE" ;
VAL_ 296 DI_vehicleSpeedLimit 511 "SNA" ;
VAL_ 296 DI_vehicleSpeedLimitReason 15 "FACTORY_BRAKE_BURNISHING" 14 "TAS_OFFROAD" 13 "SLIP_START_LIMIT" 12 "LV_DEGRADED" 11 "MAX_TIRE_TYPE" 10 "USER" 9 "FRUNK_OPEN" 8 "DAS_PEDAL_CONTROL" 7 "TAS" 6 "TRAILER_MODE" 5 "MAX_CAR_CONFIG" 4 "SERVICE_MODE" 3 "FACTORY_MODE" 2 "FACTORY_LOW_BRAKE_FLUID" 1 "DRIVE_UNIT_LIMIT" 0 "NONE" ;
VAL_ 280 DI_secondaryGearControlStatus 1 "ACTIVE" 0 "NOT_ACTIVE" ;
VAL_ 280 DI_immobilizerState 6 "DI_IMM_STATE_FAULT" 5 "DI_IMM_STATE_RESET" 4 "DI_IMM_STATE_IDLE" 3 "DI_IMM_STATE_DISARMED" 2 "DI_IMM_STATE_AUTHENTICATING" 1 "DI_IMM_STATE_REQUEST" 0 "DI_IMM_STATE_INIT_SNA" ;
VAL_ 280 DI_systemState 5 "DI_SYS_ENABLE" 4 "DI_SYS_ABORT" 3 "DI_SYS_FAULT" 2 "DI_SYS_STANDBY" 1 "DI_SYS_IDLE" 0 "DI_SYS_UNAVAILABLE" ;
VAL_ 280 DI_brakePedalState 2 "INVALID" 1 "ON" 0 "OFF" ;
VAL_ 280 DI_gear 7 "DI_GEAR_SNA" 4 "DI_GEAR_D" 3 "DI_GEAR_N" 2 "DI_GEAR_R" 1 "DI_GEAR_P" 0 "DI_GEAR_INVALID" ;
VAL_ 280 DI_driveBlocked 4 "DRIVE_BLOCKED_TRUNK" 3 "DRIVE_BLOCKED_FALCON" 2 "DRIVE_BLOCKED_PROX" 1 "DRIVE_BLOCKED_FRUNK" 0 "DRIVE_BLOCKED_NONE" ;
VAL_ 280 DI_hvilSystemStatus 3 "SNA" 2 "CLOSED" 1 "OPEN" 0 "DISABLED" ;
VAL_ 280 DI_driveModeState 1 "DM_STATE_DRIVE" 0 "DM_STATE_NONDRIVE" ;
VAL_ 280 DI_shiftRequestType 3 "SMART_SHIFT" 2 "CCCM_SHIFT" 1 "GTW_SHIFT" 0 "NONE" ;
VAL_ 280 DI_accelPedalPos 255 "SNA" ;
VAL_ 280 DI_tractionControlMode 7 "TC_SLIPPERY_SURFACE" 6 "TC_OFFROAD_ASSIST" 5 "TC_DYNO_MODE" 4 "TC_ROLLS_MODE" 3 "TC_DEV_MODE_2" 2 "TC_DEV_MODE_1" 1 "TC_SLIP_START" 0 "TC_NORMAL" ;
VAL_ 280 DI_epbRequest 2 "DI_EPBREQUEST_UNPARK" 1 "DI_EPBREQUEST_PARK" 0 "DI_EPBREQUEST_NO_REQUEST" ;
VAL_ 280 DI_keepDrivePowerStateRequest 1 "KEEP_ALIVE" 0 "NO_REQUEST" ;
VAL_ 280 DI_trackModeState 2 "TRACK_MODE_ON" 1 "TRACK_MODE_AVAILABLE" 0 "TRACK_MODE_UNAVAILABLE" ;
VAL_ 280 DI_vehicleAcceleration -2048 "SNA" ;
VAL_ 883 EPAS3P_steeringRackForce 1023 "SNA" 1022 "NOT_IN_SPEC" ;
VAL_ 883 EPAS3P_steeringFault 1 "FAULT" 0 "NO_FAULT" ;
VAL_ 883 EPAS3P_steeringReduced 1 "REDUCED_ASSIST" 0 "NORMAL_ASSIST" ;
VAL_ 883 EPAS3P_internalSASQF 1 "IN_SPEC" 0 "UNDEFINABLE_ACCURACY" ;
VAL_ 883 EPAS3P_currentTuneMode 5 "STEERING_TUNE_RWD_SPORT" 4 "STEERING_TUNE_RWD_STANDARD" 3 "STEERING_TUNE_RWD_COMFORT" 2 "STEERING_TUNE_DM_SPORT" 1 "STEERING_TUNE_DM_STANDARD" 0 "STEERING_TUNE_DM_COMFORT" ;
VAL_ 883 EPAS3P_torsionBarTorque 4095 "SNA" 4094 "UNDEFINABLE_DATA" ;
VAL_ 883 EPAS3P_eacErrorCode 15 "SNA" 14 "EAC_EXTERNAL_MONITOR_INHIBIT" 13 "EAC_ERROR_PINION_VEL_DIFF" 12 "EAC_ERROR_LOW_ASSIST" 11 "EAC_ERROR_HIGH_TORSION_SAFETY" 10 "EAC_ERROR_HIGH_MMOT_SAFETY" 9 "EAC_ERROR_HIGH_ANGLE_RATE_SAFETY" 8 "EAC_ERROR_HIGH_ANGLE_SAFETY" 7 "EAC_ERROR_HIGH_ANGLE_RATE_REQ" 6 "EAC_ERROR_HIGH_ANGLE_REQ" 5 "EAR_ERROR_MAX_STEER_DELTA" 4 "EAC_ERROR_TMP_FAULT" 3 "EAC_ERROR_HANDS_ON" 2 "EAC_ERROR_MAX_SPEED" 1 "EAC_ERROR_MIN_SPEED" 0 "EAC_ERROR_IDLE" ;
VAL_ 883 EPAS3P_handsOnLevel 3 "LEVEL_3" 2 "LEVEL_2" 1 "LEVEL_1" 0 "LEVEL_0" ;
VAL_ 883 EPAS3P_eacStatus 7 "EAC_ELK_ACTIVE" 6 "EAC_ELK_AVAILABLE" 5 "EAC_LKA_ACTIVE" 4 "EAC_LKA_ELK_AVAILABLE" 3 "EAC_FAULT" 2 "EAC_ACTIVE" 1 "EAC_AVAILABLE" 0 "EAC_INHIBITED" ;
VAL_ 882 EPAS3S_steeringRackForce 1023 "SNA" 1022 "NOT_IN_SPEC" ;
VAL_ 882 EPAS3S_steeringFault 1 "FAULT" 0 "NO_FAULT" ;
VAL_ 882 EPAS3S_steeringReduced 1 "REDUCED_ASSIST" 0 "NORMAL_ASSIST" ;
VAL_ 882 EPAS3S_internalSASQF 1 "IN_SPEC" 0 "UNDEFINABLE_ACCURACY" ;
VAL_ 882 EPAS3S_currentTuneMode 5 "STEERING_TUNE_RWD_SPORT" 4 "STEERING_TUNE_RWD_STANDARD" 3 "STEERING_TUNE_RWD_COMFORT" 2 "STEERING_TUNE_DM_SPORT" 1 "STEERING_TUNE_DM_STANDARD" 0 "STEERING_TUNE_DM_COMFORT" ;
VAL_ 882 EPAS3S_torsionBarTorque 4095 "SNA" 4094 "UNDEFINABLE_DATA" ;
VAL_ 882 EPAS3S_eacErrorCode 15 "SNA" 14 "EAC_EXTERNAL_MONITOR_INHIBIT" 13 "EAC_ERROR_PINION_VEL_DIFF" 12 "EAC_ERROR_LOW_ASSIST" 11 "EAC_ERROR_HIGH_TORSION_SAFETY" 10 "EAC_ERROR_HIGH_MMOT_SAFETY" 9 "EAC_ERROR_HIGH_ANGLE_RATE_SAFETY" 8 "EAC_ERROR_HIGH_ANGLE_SAFETY" 7 "EAC_ERROR_HIGH_ANGLE_RATE_REQ" 6 "EAC_ERROR_HIGH_ANGLE_REQ" 5 "EAR_ERROR_MAX_STEER_DELTA" 4 "EAC_ERROR_TMP_FAULT" 3 "EAC_ERROR_HANDS_ON" 2 "EAC_ERROR_MAX_SPEED" 1 "EAC_ERROR_MIN_SPEED" 0 "EAC_ERROR_IDLE" ;
VAL_ 882 EPAS3S_handsOnLevel 3 "LEVEL_3" 2 "LEVEL_2" 1 "LEVEL_1" 0 "LEVEL_0" ;
VAL_ 882 EPAS3S_eacStatus 7 "EAC_ELK_ACTIVE" 6 "EAC_ELK_AVAILABLE" 5 "EAC_LKA_ACTIVE" 4 "EAC_LKA_ELK_AVAILABLE" 3 "EAC_FAULT" 2 "EAC_ACTIVE" 1 "EAC_AVAILABLE" 0 "EAC_INHIBITED" ;
VAL_ 681 EPBL_systemStatus 8 "EPB_VEHICLE_STATUS_MISMATCH" 7 "EPB_VEHICLE_STATUS_FAULT_SECURE" 6 "EPB_VEHICLE_STATUS_FAULT" 5 "EPB_VEHICLE_STATUS_RELEASING" 4 "EPB_VEHICLE_STATUS_PARKING" 3 "EPB_VEHICLE_STATUS_DYNAMIC" 2 "EPB_VEHICLE_STATUS_PARKED" 1 "EPB_VEHICLE_STATUS_RELEASED" 0 "EPB_VEHICLE_STATUS_UNKNOWN" ;
VAL_ 681 EPBL_freeRollModeStatus 2 "EPB_FREE_ROLL_MODE_ENABLED" 1 "EPB_FREE_ROLL_MODE_AVAILABLE" 0 "EPB_FREE_ROLL_MODE_UNAVAILABLE" ;
VAL_ 681 EPBL_chimeRequest 4 "EPB_CHIME_REQUEST_ACTIVE_DECEL" 3 "EPB_CHIME_REQUEST_ABOUT_TO_ACTIVE_DECEL" 2 "EPB_CHIME_REQUEST_GPO" 1 "EPB_CHIME_REQUEST_GENERAL" 0 "EPB_CHIME_REQUEST_NONE" ;
VAL_ 681 EPBL_telltale 7 "EPB_TELLTALE_SNA" 4 "EPB_TELLTALE_LAMP_RED_FLASH" 3 "EPB_TELLTALE_LAMP_AMBER_ON" 2 "EPB_TELLTALE_LAMP_RED_ON" 1 "EPB_TELLTALE_LAMP_RED_PARKED" 0 "EPB_TELLTALE_LAMP_OFF" ;
VAL_ 681 EPBL_cdpRequest 1 "EPB_CDP_REQUESTED" 0 "EPB_CDP_NOT_REQUESTED" ;
VAL_ 681 EPBL_uiParkAvailable 2 "EPB_AVAIL_REAPPLIED" 1 "EPB_AVAIL_AVAILABLE" 0 "EPB_AVAIL_NOT_AVAILABLE" ;
VAL_ 681 EPBL_brakeDiscWipeRequest 3 "EPB_BRAKEDISCWIPE_REQUEST_SNA" 2 "EPB_BRAKEDISCWIPE_REQUEST_STRONG" 1 "EPB_BRAKEDISCWIPE_REQUEST_LIGHT" 0 "EPB_BRAKEDISCWIPE_REQUEST_NONE" ;
VAL_ 681 EPBL_uiWinchModeLvStatus 3 "EPB_LV_OK" 2 "EPB_LV_BLOCKED_TIMER_RUNNING" 1 "EPB_LV_BLOCKED_INPUT_VOLTAGE_LOW" 0 "EPB_LV_BLOCKED_BATTERY" ;
VAL_ 744 EPBR_systemStatus 8 "EPB_VEHICLE_STATUS_MISMATCH" 7 "EPB_VEHICLE_STATUS_FAULT_SECURE" 6 "EPB_VEHICLE_STATUS_FAULT" 5 "EPB_VEHICLE_STATUS_RELEASING" 4 "EPB_VEHICLE_STATUS_PARKING" 3 "EPB_VEHICLE_STATUS_DYNAMIC" 2 "EPB_VEHICLE_STATUS_PARKED" 1 "EPB_VEHICLE_STATUS_RELEASED" 0 "EPB_VEHICLE_STATUS_UNKNOWN" ;
VAL_ 744 EPBR_freeRollModeStatus 2 "EPB_FREE_ROLL_MODE_ENABLED" 1 "EPB_FREE_ROLL_MODE_AVAILABLE" 0 "EPB_FREE_ROLL_MODE_UNAVAILABLE" ;
VAL_ 744 EPBR_chimeRequest 4 "EPB_CHIME_REQUEST_ACTIVE_DECEL" 3 "EPB_CHIME_REQUEST_ABOUT_TO_ACTIVE_DECEL" 2 "EPB_CHIME_REQUEST_GPO" 1 "EPB_CHIME_REQUEST_GENERAL" 0 "EPB_CHIME_REQUEST_NONE" ;
VAL_ 744 EPBR_telltale 7 "EPB_TELLTALE_SNA" 4 "EPB_TELLTALE_LAMP_RED_FLASH" 3 "EPB_TELLTALE_LAMP_AMBER_ON" 2 "EPB_TELLTALE_LAMP_RED_ON" 1 "EPB_TELLTALE_LAMP_RED_PARKED" 0 "EPB_TELLTALE_LAMP_OFF" ;
VAL_ 744 EPBR_cdpRequest 1 "EPB_CDP_REQUESTED" 0 "EPB_CDP_NOT_REQUESTED" ;
VAL_ 744 EPBR_uiParkAvailable 2 "EPB_AVAIL_REAPPLIED" 1 "EPB_AVAIL_AVAILABLE" 0 "EPB_AVAIL_NOT_AVAILABLE" ;
VAL_ 744 EPBR_brakeDiscWipeRequest 3 "EPB_BRAKEDISCWIPE_REQUEST_SNA" 2 "EPB_BRAKEDISCWIPE_REQUEST_STRONG" 1 "EPB_BRAKEDISCWIPE_REQUEST_LIGHT" 0 "EPB_BRAKEDISCWIPE_REQUEST_NONE" ;
VAL_ 744 EPBR_uiWinchModeLvStatus 3 "EPB_LV_OK" 2 "EPB_LV_BLOCKED_TIMER_RUNNING" 1 "EPB_LV_BLOCKED_INPUT_VOLTAGE_LOW" 0 "EPB_LV_BLOCKED_BATTERY" ;
VAL_ 282 GTW_BKP_BATT_MON 4095 "SNA" ;
VAL_ 282 GTW_BKP_BATT_NTC_P 4095 "SNA" ;
VAL_ 282 GTW_ECALL_GPS_ANT_BIAS 4095 "SNA" ;
VAL_ 282 GTW_ECALL_MIC_DIAG 4095 "SNA" ;
VAL_ 282 GTW_SOS_ECALL_nRQST_BUF 4095 "SNA" ;
VAL_ 838 GTW_autopilotOverrideState 3 "TIMEBOUND_SUBSCRIPTION" 2 "TRIAL" 1 "SUBSCRIPTION" 0 "BASE" ;
VAL_ 838 GTW_autopilotConfig 4 "BASIC" 3 "SELF_DRIVING" 2 "ENHANCED" 1 "HIGHWAY" 0 "NONE" ;
VAL_ 838 GTW_autopilotOverrideConfig 4 "BASIC" 3 "SELF_DRIVING" 2 "ENHANCED" 1 "HIGHWAY" 0 "NONE" ;
VAL_ 904 GTW_VEH_faultConfinement 2 "BUS_OFF" 1 "ERROR_PASSIVE" 0 "ERROR_ACTIVE" ;
VAL_ 904 GTW_PARTY_faultConfinement 2 "BUS_OFF" 1 "ERROR_PASSIVE" 0 "ERROR_ACTIVE" ;
VAL_ 904 GTW_CH_faultConfinement 2 "BUS_OFF" 1 "ERROR_PASSIVE" 0 "ERROR_ACTIVE" ;
VAL_ 2047 GTW_deliveryStatus 1 "DELIVERED" 0 "NOT_DELIVERED" ;
VAL_ 2047 GTW_cabinPTCHeaterType 1 "NONE" 0 "BORGWARNER" ;
VAL_ 2047 GTW_rightHandDrive 1 "RIGHT" 0 "LEFT" ;
VAL_ 2047 GTW_rearLightType 2 "GLOBAL" 1 "EU_CN" 0 "NA" ;
VAL_ 2047 GTW_headlamps 2 "GLOBAL" 1 "PREMIUM" 0 "BASE" ;
VAL_ 2047 GTW_tireType 38 "HANKOOK_SUMMER_18" 37 "GITI_SUMMER_18" 36 "KUMHO_ALL_SEASON_18" 35 "GOODYEAR_ALL_SEASON_18" 34 "CONTI_SUMMER_19" 33 "BRIDGESTONE_ALL_SEASON_20" 32 "HANKOOK_ALL_SEASON_20" 31 "GOODYEAR_SUMMER_19" 30 "KUMHO_ALL_SEASON_19" 29 "HANKOOK_ALL_SEASON_21" 28 "PIRELLI_ALL_SEASON_19" 27 "GOODYEAR_ALL_SEASON_21" 26 "HANKOOK_ALL_SEASON_18" 25 "PIRELLI_ALL_SEASON_22" 24 "CONTI_SUMMER_22" 23 "CONTI_ALL_SEASON_20" 22 "MICHELIN_SUMMER_21" 21 "PIRELLI_SUMMER_20" 20 "PIRELLI_SUMMER_19" 19 "MICHELIN_ALL_SEASON_21" 18 "PIRELLI_SUMMER_21" 17 "GOODYEAR_ALL_SEASON_20" 16 "BRIDGESTONE_SUMMER_18" 7 "GOODYEAR_ALL_TERRAIN_20" 6 "PIRELLI_ALL_SEASON_20" 5 "MICHELIN_SUMMER_20" 4 "CONTI_ALL_SEASON_19" 3 "HANKOOK_SUMMER_19" 2 "MICHELIN_SUMMER_18" 1 "MICHELIN_ALL_SEASON_18" 0 "UNKNOWN" ;
VAL_ 2047 GTW_roofGlassType 3 "UNCOATED" 2 "NONE" 1 "TSA5_NOPET" 0 "TSA3_PET" ;
VAL_ 2047 GTW_dasHw 5 "TESLA_AP4" 4 "TESLA_AP3" 3 "PARKER_PASCAL_2_5" ;
VAL_ 2047 GTW_brakeHWType 21 "HITACHI_P42_V2_MANDO_43MOC_LOW_DRAG" 20 "BREMBO_LARGE_P42_V2_MANDO_43MOC_LOW_DRAG" 18 "BREMBO_LARGE_P42_V2_BREMBO_44MOC_GA" 17 "HITACHI_P42_V2_MANDO_43MOC" 16 "BREMBO_P42LD_V2_MANDO_43MOC" 15 "BREMBO_P42LD_ZF_43MOC" 13 "BREMBO_P42_ZF_43MOC" 9 "BREMBO_P42_V2_MANDO_43MOC" 8 "BREMBO_LARGE_P42_V2_MANDO_43MOC" 7 "BREMBO_LARGE_P42_V2_BREMBO_LARGE_44MOC" 6 "BREMBO_LARGE_P42_V2_BREMBO_44MOC" 3 "BREMBO_LARGE_P42_BREMBO_LARGE_44MOC" 2 "BREMBO_LARGE_P42_MANDO_43MOC" 1 "BREMBO_LARGE_P42_BREMBO_44MOC" 0 "BREMBO_P42_MANDO_43MOC" ;
VAL_ 2047 GTW_restraintsHardwareType 239 "NA_NO_KAB_MYB" 238 "ROW_ECALL_E41_MYB" 237 "EU_ECALL_E41_MYB" 236 "NA_E41_MYB" 233 "NA_MYL" 232 "ECE_ECALL_PEDPRO_MYL" 89 "ROW_ECALL_PEDPRO_MYL" 88 "ROW_PEDPRO_MYB" 87 "ROW_PERF_ECALL_PEDPRO_MYB" 86 "EU_PERF_ECALL_PEDPRO_MYB" 85 "EU_ECALL_PEDPRO_MYB" 84 "ROW_ECALL_PEDPRO_MYB" 83 "ROW_MYB" 82 "ROW_ECALL_MYB" 81 "NA_MYB" ;
VAL_ 2047 GTW_drivetrainType 1 "AWD" 0 "RWD" ;
VAL_ 2047 GTW_radarHeaterType 1 "MODELY_BACKER_THIN_3M" 0 "NONE" ;
VAL_ 2047 GTW_exteriorTrimType 1 "SATIN_BLACK" 0 "STANDARD_CHROME" ;
VAL_ 2047 GTW_frontSeatHeaters 1 "KONGSBERG_LOW_POWER" 0 "NONE" ;
VAL_ 2047 GTW_rearSeatHeaters 1 "KONGSBERG_LOW_POWER" 0 "NONE" ;
VAL_ 2047 GTW_eCallAntennaHW 1 "MAIN_ANT_ONLY" 0 "BACKUP_OR_MAIN_ANT" ;
VAL_ 2047 GTW_homelinkType 1 "HOMELINK_V_OPT_2" 0 "NONE" ;
VAL_ 2047 GTW_vdcType 1 "TESLA_VDC" 0 "BOSCH_VDC" ;
VAL_ 2047 GTW_memoryMirrors 1 "SMR" 0 "NOT_INSTALLED" ;
VAL_ 2047 GTW_powerLiftgateType 2 "HUADE_REV1" 1 "TESLA_REV1" 0 "NOT_INSTALLED" ;
VAL_ 2047 GTW_lumbarECUType 10 "AEW_SINGLE_AXIS_DRIVER_ONLY_RHD" 9 "AEW_SINGLE_AXIS_DRIVER_ONLY_LHD" 8 "ND_DRIVER_ONLY_RHD" 7 "ND_DRIVER_ONLY_LHD" 6 "AEW_DRIVER_ONLY_RHD" 5 "AEW_DRIVER_ONLY_LHD" 4 "AEW" 3 "ALFMEIER_DRIVER_ONLY_RHD" 2 "ALFMEIER_DRIVER_ONLY_LHD" 1 "ALFMEIER" 0 "NONE" ;
VAL_ 2047 GTW_rearSeatHeaterType 3 "LEFT_RIGHT_ONLY_GENTHERM" 2 "NONE" 1 "LEFT_RIGHT_ONLY_KONGSBERG" ;
VAL_ 2047 GTW_auxParkLamps 3 "NONE" 2 "EU" 1 "NA_PREMIUM" 0 "NA_BASE" ;
VAL_ 2047 GTW_interiorCabinRadarType 1 "TESLA" 0 "NONE" ;
VAL_ 2047 GTW_hvacPanelVaneType 1 "CONVERGENT_V1" 0 "PARALLEL_V1" ;
VAL_ 2047 GTW_intakeAirFilterType 1 "HEPA" 0 "STANDARD" ;
VAL_ 2047 GTW_eBuckConfig 1 "DEV_BUCK" 0 "NONE" ;
VAL_ 2047 GTW_steeringHeaterEnabled 1 "ENABLED" 0 "DISABLED" ;
VAL_ 2047 GTW_activeHighBeam 1 "ACTIVE" 0 "NOT_ACTIVE" ;
VAL_ 2047 GTW_airbagCutoffSwitch 1 "CUTOFF_SWITCH_ENABLED" 0 "CUTOFF_SWITCH_DISABLED" ;
VAL_ 2047 GTW_intrusionSensorType 1 "VODAFONE" 0 "NOT_INSTALLED" ;
VAL_ 2047 GTW_spoilerType 1 "PASSIVE" 0 "NOT_INSTALLED" ;
VAL_ 2047 GTW_rearFogLamps 1 "INSTALLED" 0 "NOT_INSTALLED" ;
VAL_ 2047 GTW_roofType 1 "FIXED_GLASS" ;
VAL_ 2047 GTW_thirdRowSeatType 1 "FLAT_FOLD" 0 "NONE" ;
VAL_ 2047 GTW_autopilot 4 "BASIC" 3 "SELF_DRIVING" 2 "ENHANCED" 1 "HIGHWAY" 0 "NONE" ;
VAL_ 2047 GTW_superchargingAccess 2 "PAY_AS_YOU_GO" 1 "ALLOWED" 0 "NOT_ALLOWED" ;
VAL_ 2047 GTW_exteriorColor 20 "COASTAL_BLUE" 17 "MARINE_BLUE" 16 "SILKROAD_SILVER" 15 "DIAMOND_BLACK" 14 "GLACIER_BLUE" 13 "FROST_BLUE" 11 "STEALTH_GREY" 10 "ULTRA_RED" 9 "QUICKSILVER" 8 "ABYSS_BLUE" 7 "MIDNIGHT_CHERRY_RED" 6 "PEARL_WHITE" 5 "DEEP_BLUE" 3 "MIDNIGHT_SILVER" 2 "SILVER_METALLIC" 1 "SOLID_BLACK" 0 "RED_MULTICOAT" ;
VAL_ 2047 GTW_pedestrianWarningSound 2 "EXT_SPEAKER_V2" 1 "SPEAKER" 0 "NONE" ;
VAL_ 2047 GTW_steeringColumnUJointType 1 "C_SAMPLE_PHASING" ;
VAL_ 2047 GTW_bPillarNFCParam 1 "MODEL_Y" 0 "MODEL_3" ;
VAL_ 2047 GTW_interiorLighting 6 "FOOTWELL" 5 "FOOTWELL_RGB_IP" 4 "PREMIUM_WITH_RGB_IP_ONLY" 3 "PREMIUM_WITH_RGB" 2 "PREMIUM_NO_POCKET_LIGHT" 1 "PREMIUM" 0 "BASE" ;
VAL_ 2047 GTW_headlightLevelerType 2 "VIRTUAL_PITCH_SENSOR" 1 "GEN1" 0 "NONE" ;
VAL_ 2047 GTW_numberHVILNodes 3 "HVIL_NODES_3" 2 "HVIL_NODES_2" 0 "HVIL_NODES_0" ;
VAL_ 2047 GTW_mapRegion 13 "LA" 12 "IN" 11 "SE" 10 "MO" 9 "HK" 8 "ME" 7 "KR" 6 "TW" 5 "JP" 4 "AU" 3 "CN" 2 "NONE" 1 "EU" 0 "US" ;
VAL_ 2047 GTW_performancePackage 4 "BASE_2022" 3 "BASE_PLUS" 2 "BASE_2024" 1 "PERFORMANCE" 0 "BASE" ;
VAL_ 2047 GTW_chassisType 7 "MODEL_Y_LONG_WHEELBASE_CHASSIS_PATRONUS" 3 "MODEL_Y_CHASSIS" 2 "MODEL_3_CHASSIS" ;
VAL_ 2047 GTW_airSuspension 3 "COIL_ADAPTIVE_DAMPING" 0 "NONE" ;
VAL_ 2047 GTW_centerConsoleControllerType 2 "INSTALLED_NO_AIRWAVE" 1 "INSTALLED_V1" 0 "NONE" ;
VAL_ 2047 GTW_autopilotCameraType 1 "RGGB_CAMERAS" 0 "RCCB_CAMERAS" ;
VAL_ 2047 GTW_connectivityPackage 1 "PREMIUM" 0 "BASE" ;
VAL_ 2047 GTW_plcSupportType 2 "NATIVE_CHARGE_PORT" 1 "ONBOARD_ADAPTER" 0 "NONE" ;
VAL_ 2047 GTW_packEnergy 2 "MR" 1 "LR" 0 "SR" ;
VAL_ 2047 GTW_frontSeatReclinerHardware 3 "LEFT_RIGHT_SEAT_REDUCED_RANGE" 2 "LEFT_SEAT_REDUCED_RANGE" 1 "RIGHT_SEAT_REDUCED_RANGE" 0 "STANDARD_RANGE" ;
VAL_ 2047 GTW_brakeLineSwitchType 1 "VC_ONLY" 0 "DI_VC_SHARED" ;
VAL_ 2047 GTW_softRange 4 "RANGE_260_MILES" 3 "RANGE_343_MILES" 2 "RANGE_93_MILES" 1 "RANGE_220_MILES" 0 "STANDARD" ;
VAL_ 2047 GTW_refrigerantType 2 "R1234YF" 1 "R134A" 0 "Default" ;
VAL_ 2047 GTW_wheelType 52 "UBERHELIX_20" 51 "GEMINI_19_DARK_STAGGERED" 50 "HELIX_V2_20_DARK" 48 "MACHINA_V2_19_STAGGERED" 47 "GLIDER_18_CAP_KIT" 46 "APERTURE_18" 41 "ARACHNID_V2_21" 40 "HELIX_V2_20" 39 "CROSSFLOW_19" 33 "WISHBONE_20_STAGGERED" 31 "HELIX_19" 30 "GLIDER_18" 27 "ZEROG_19_GUNPOWDER" 24 "PINWHEEL_REFRESH_18_CAP_KIT" 23 "UBERTURBINE_20_GUNPOWDER" 22 "PINWHEEL_REFRESH_18" 21 "STILETTO_REFRESH_19" 19 "ZEROG_20_GUNPOWDER" 18 "PINWHEEL_18_CAP_KIT" 14 "STILETTO_20_DARK_SQUARE" 5 "GEMINI_19_STAGGERED" 4 "GEMINI_19_SQUARE" 3 "STILETTO_20_DARK_STAGGERED" 2 "STILETTO_20" 1 "STILETTO_19" 0 "PINWHEEL_18" ;
VAL_ 2047 GTW_brakeActuationType 2 "ESP_DPB" 1 "IDB_RCU" 0 "ESP_IBST" ;
VAL_ 2047 GTW_secondRowSeatType 6 "TWO_SEATS_POWERED_RECLINE" 5 "FLAT_FOLD_V2" 4 "EASY_ENTRY_POWERED_RECLINE" 3 "POWERED_RECLINE" ;
VAL_ 2047 GTW_secondRowSeatMotorType 1 "KEIPER" 0 "SHB" ;
VAL_ 2047 GTW_eCallEnabled 2 "ENABLED_UI_SOS" 1 "ENABLED_OHC_SOS" 0 "DISABLED" ;
VAL_ 2047 GTW_parkAssistECUType 2 "NONE" 1 "TESLA" 0 "VALEO" ;
VAL_ 2047 GTW_passengerAirbagType 2 "EUROW" 1 "SAFETY_VENT" 0 "FULL_SUPPRESSION" ;
VAL_ 2047 GTW_forwardRadarHw 2 "NONE" 0 "CONTI_ARS410" ;
VAL_ 2047 GTW_frontSeatType 13 "PREMIUM_L_YANFENG_MINITILT_R_TESLA_MINITILT" 12 "PREMIUM_L_YANFENG_MINITILT_R_YANFENG_MINITILT" 11 "PREMIUM_L_YANFENG_MINITILT_R_YANFENG" 10 "PREMIUM_L_YANFENG_R_YANFENG_MINITILT" 9 "PREMIUM_L_TESLA_MINITILT_R_YANFENG_MINITILT" 8 "PREMIUM_L_TESLA_MINITILT_R_TESLA_MINITILT" 7 "PREMIUM_L_TESLA_MINITILT_R_TESLA" 6 "PREMIUM_L_TESLA_R_TESLA_MINITILT" 5 "PREMIUM_BROSE" 4 "PREMIUM_YANFENG" 3 "PREMIUM_L_TESLA_R_YANFENG" 2 "PREMIUM_L_YANFENG_R_TESLA" 1 "PREMIUM_TESLA" 0 "BASE_TESLA" ;
VAL_ 2047 GTW_secondRowDisplayType 1 "TYPE_1" 0 "NONE" ;
VAL_ 2047 GTW_wirelessPhoneChargerType 3 "FRONT_HIGH_POWER_UART" 1 "FRONT_LIN" 0 "NONE_OR_USB" ;
VAL_ 2047 GTW_ethernetTunerType 3 "HARMAN_GEN3" 2 "HIRSCHMANN" 1 "NONE" 0 "HARMAN" ;
VAL_ 2047 GTW_interiorTrimType 3 "WHITE_CONSOLE_2" 2 "BLACK_CONSOLE_2" 1 "WHITE" 0 "BLACK" ;
VAL_ 2047 GTW_gloveboxUSBType 2 "TSC_USB3_A_PLUS_BT" 1 "TSC_USB3_A" 0 "NOT_INSTALLED" ;
VAL_ 2047 GTW_coolantPumpType 5 "DUAL_MIX" 4 "DUAL_SAN_P4_LUB" 2 "DUAL_SAN_P4" 1 "SINGLE_PUMP_BATT" 0 "DUAL" ;
VAL_ 2047 GTW_epblHwType 8 "ZF" 5 "BREMBO_V2" 4 "BREMBO_V1" 2 "MANDO_V2" 1 "MANDO_V1" 0 "NOT_SET" ;
VAL_ 2047 GTW_epbrHwType 8 "ZF" 5 "BREMBO_V2" 4 "BREMBO_V1" 2 "MANDO_V2" 1 "MANDO_V1" 0 "NOT_SET" ;
VAL_ 2047 GTW_blowerMotorType 1 "DELTA" 0 "SHINANO" ;
VAL_ 2047 GTW_frontUsbHubType 4 "NO_DATA" 0 "2" ;
VAL_ 2047 GTW_superManifoldType 2 "TYPE2" 1 "TYPE1" 0 "TYPE0" ;
VAL_ 2047 GTW_rcmLocation 0 "CENTER_CONSOLE" ;
VAL_ 2047 GTW_interiorCamFanType 3 "NIDEC" 2 "DELTA_FDB" 0 "NONE" ;
VAL_ 2047 GTW_sirenType 1 "VODAPHONE_IF_INTRUSION" 0 "NONE" ;
VAL_ 2047 GTW_hornType 1 "EXT_SPEAKER_V2" 0 "TRUMPET" ;
VAL_ 2047 GTW_badgingVersion 1 "VERSION_1" 0 "VERSION_0" ;
VAL_ 2047 GTW_steeringColumnMotorType 3 "NEXTEER" 2 "BOSCH_COMMON_TO_JE" 1 "JE" 0 "BOSCH" ;
VAL_ 2047 GTW_refrigACLineType 2 "CONTI_LIMITED" 1 "SAAA_LIMITED" 0 "UNLIMITED" ;
VAL_ 2047 GTW_refrigFilterType 2 "BLOCKED_V2" 1 "BLOCKED_V1" 0 "UNBLOCKED" ;
VAL_ 2047 GTW_diBurnInType 1 "ENABLED_V1" 0 "NONE" ;
VAL_ 2047 GTW_specialBadgingType 2 "LAUNCH_SERIES" 0 "NONE" ;
VAL_ 2047 GTW_chassisSubType 3 "TRIM_DEVIATION_1" 2 "PERFORMANCE" 1 "BASE" 0 "UNKNOWN" ;
VAL_ 2047 GTW_frontSeatVentilationType 1 "TYPE_1" 0 "NONE" ;
VAL_ 2047 GTW_towPackage 2 "TESLA_REV2" 1 "TESLA_REV1" 0 "NONE" ;
VAL_ 2047 GTW_refrigLccType 1 "LCCR" 0 "LCC" ;
VAL_ 2047 GTW_caliperColorType 2 "RED" 1 "GREY" 0 "UNKNOWN" ;
VAL_ 2047 GTW_wiperMotorType 1 "SHB" 0 "NOT_UPDATEABLE" ;
VAL_ 2047 GTW_frontOverheadConsoleType 3 "KOSTAL" 2 "PREH" 1 "BITRON" 0 "VALEO" ;
VAL_ 2047 GTW_shifterType 1 "DISPLAY" 0 "STALK" ;
VAL_ 2047 GTW_compressorType 10 "SANDEN_V4_1" 8 "SANDEN_V4" 7 "SANDEN_V3" 6 "SANDEN_V1_1" 5 "SANDEN_V2" 4 "DENSO_11K_COP1_ENABLED" 3 "SANDEN" 2 "DENSO_41CC_11K" 1 "DENSO_41CC_8K" 0 "HANON_33CC" ;
VAL_ 2047 GTW_twelveVBatteryType 3 "TESLA_16V_LI_ION" 2 "CATL_LI_ION" 1 "CLARIOS_B24_FLOODED" 0 "ATLASBX_B24_FLOODED" ;
VAL_ 2047 GTW_efuseSWConfig 3 "ALL_ENABLED" 2 "SQUARE_ENABLED" 1 "ROUND_ENABLED" 0 "DISABLED" ;
VAL_ 2047 GTW_tollCollectionModuleType 1 "WANJI_V1" 0 "NONE" ;
VAL_ 2047 GTW_bleEndpointUpdateMethod 1 "BOOTLOADER_UPDATE" ;
VAL_ 2047 GTW_steeringWheelControllerType 5 "DUAL_TESLA_GEN5" 2 "DUAL_KOSTAL" 1 "DUAL_PREH" ;
VAL_ 2047 GTW_frontSeatVentilationEnabled 1 "ENABLED" 0 "DISABLED" ;
VAL_ 2047 GTW_gloveboxActuatorType 2 "ELECTROMAGNET" 1 "SMA" 0 "SOLENOID" ;
VAL_ 2047 GTW_epasType 8 "THYSSENKRUPP_CGR65" 7 "MANDO_CGR65" 6 "THYSSENKRUPP_VGR69" 5 "MANDO_CGR69_SINGLE_ECU" 4 "MANDO_CGR69" 3 "MANDO_VGR69_GEN3_SINGLE_ECU" 0 "MANDO_VGR69_GEN3" ;
VAL_ 2047 GTW_homologationRegionOverride 2 "MX_UNECE" 1 "KR_UNECE" 0 "DEFAULT_FOR_COUNTRY_CODE" ;
VAL_ 2047 GTW_windowCommandsPermissionType 2 "US_FMVSS_S6" 1 "US_FMVSS_S4" 0 "ROW_OR_US_FMVSS_S5" ;
VAL_ 2047 GTW_rgbInteriorLightingEnabled 2 "ALL_COLORS" 1 "WHITE_ONLY" 0 "DISABLED_OR_NA" ;
VAL_ 2047 GTW_windshieldWiperHeaterType 1 "TYPE_1" 0 "NOT_INSTALLED" ;
VAL_ 2047 GTW_driveInterfaceType 1 "EXTERNAL" 0 "COMBINED" ;
VAL_ 2047 GTW_efficiencyPackage 42 "MY_2026_US" 39 "MY_2025_CN_PLUS" 38 "MY_2026_M53" 34 "MY_STANDARD_2026" 33 "MY_REFRESH_2025_CN_ALL_US_LR_RWD" 32 "MY_REFRESH_2025_ROW" 24 "MY_2024_GFSH_EXPORT_NA_SR_RWD" 23 "MY_2024C" 20 "MY_2023_SR_RWD" 16 "MY_2024" 15 "MY_2023_GFSH_EXPORT_NA" 12 "MY_RWD_EU_2022" 11 "MY_SR_PLUS_2022_Q1_TX" 9 "MY_SR_PLUS_2021_Q3_GFSH" 7 "MY_2021" 5 "MY_2020" 0 "DEFAULT" ;
VAL_ 2047 GTW_visorLightType 1 "DIMMABLE_TYPE_1" 0 "NON_DIMMABLE" ;
VAL_ 2047 GTW_gnssAntennaType 2 "GEN2_WITH_METAL_INSERT" 1 "GEN2_NO_METAL_INSERT" 0 "NA_OR_GEN1" ;
VAL_ 2047 GTW_frontSeatHeatersEnabled 1 "ENABLED" 0 "DISABLED" ;
VAL_ 2047 GTW_windshieldWiperHeaterEnabled 1 "ENABLED_OR_NA" 0 "DISABLED" ;
VAL_ 2047 GTW_tcuType 1 "5G" 0 "4G" ;
VAL_ 2047 GTW_fasciaType 8 "E41_BAYBERRY" 4 "PERFORMANCE_BAYBERRY" 3 "BASE_BAYBERRY" 0 "ORIGINAL" ;
VAL_ 2047 GTW_powerSteeringColumn 1 "TK" 0 "NOT_INSTALLED" ;
VAL_ 2047 GTW_frontSeatHeaterType 1 "GENTHERM" 0 "KONGSBERG" ;
VAL_ 2047 GTW_softPerformanceLimit 6 "LIMIT_230_KW" 4 "LIMIT_110_MPH" 2 "LIMIT_110_KW" 1 "LIMIT_160_KW" 0 "NONE" ;
VAL_ 2047 GTW_alcoholInterlockType 1 "TYPE_1" 0 "NONE" ;
VAL_ 2047 GTW_immersiveAudio 2 "PREMIUM" 1 "BASE" 0 "DISABLED" ;
VAL_ 2047 GTW_passengerOccupancySensorType 4 "NONE" 1 "RESISTIVE_PAD" 0 "OCS" ;
VAL_ 2047 GTW_packPerformanceDeviation 5 "PACK_POWER_DEVIATION_2" 4 "PACK_MASS_DEVIATION_2" 3 "PACK_STRUCTURAL_DEVIATION_1" 2 "PACK_POWER_DEVIATION_1" 1 "PACK_MASS_DEVIATION_1" 0 "NO_DEVIATION" ;
VAL_ 2047 GTW_frontFogLamps 1 "INSTALLED" 0 "NOT_INSTALLED" ;
VAL_ 2047 GTW_driverOccupancySensorType 1 "NONE" 0 "RESISTIVE_PAD" ;
VAL_ 2047 GTW_audioType 4 "ESSENTIAL_WITH_COMMODITY100" 3 "ESSENTIAL" 1 "PREMIUM" 0 "BASE" ;
VAL_ 2047 GTW_occupancyClassificationFeatu 1 "TESLA_CABIN_RADAR" 0 "DISCRETE_SENSOR_OR_NA" ;
VAL_ 2047 GTW_domeLightType 2 "TESLA_2R" ;
VAL_ 2047 GTW_tpmsType 2 "INDIRECT" 1 "TESLA_BLE" 0 "CONTI_2" ;
VAL_ 2047 GTW_authenticationEndpointLayout 2 "MY_LAYOUT_2" 1 "M3_LAYOUT_2" 0 "LAYOUT_1" ;
VAL_ 2047 GTW_socSleepOverride 2 "FORCE_SHALLOW" 1 "FORCE_S3" 0 "PN_DERIVED" ;
VAL_ 2047 GTW_r79BehaviorOverride 1 "R79_ENABLED" 0 "NO_OVERRIDE" ;
VAL_ 2047 GTW_steeringHeaterType 7 "YF_V2" 4 "ZF_ROUND" 0 "NONE" ;
VAL_ 2047 GTW_sohRegulatoryStatus 1 "REGULATED_SOH" 0 "NON_REGULATED_SOH" ;
VAL_ 2047 GTW_m3yBusArchitecture 2 "PRIVATE_TORQUE_CHASSIS" 1 "PRIVATE_TORQUE" 0 "PUBLIC_TORQUE" ;
VAL_ 2047 GTW_blindSpotIndicatorLightType 1 "INSTALLED_TYPE_1" 0 "NOT_INSTALLED" ;
VAL_ 2047 GTW_hvacCaseDoorType 1 "FLAT_EDGE" 0 "SERRATED_EDGE" ;
VAL_ 2047 GTW_rduCableType 1 "COPPER" 0 "ALUMINUM" ;
VAL_ 2047 GTW_interiorCameraType 1 "VD6763" 0 "AR0136" ;
VAL_ 2047 GTW_frontFasciaCameraType 2 "IMX00N" 1 "IMX963" 0 "NONE" ;
VAL_ 1638 GTW_diagLevel 100 "LEVEL_NORMAL_OPERATION" 80 "LEVEL_PARK" 70 "LEVEL_PARK_ROBOTAXI" 50 "LEVEL_SERVICE_DRIVE" 25 "LEVEL_SERVICE" 10 "LEVEL_DIAG_LINK_ACTIVE" 0 "LEVEL_FACTORY" ;
VAL_ 1080 GTW_ethWakeUpReason 15 "GTW_WAKEUP_REASON_RCMPRIVATE_CAN" 14 "GTW_WAKEUP_REASON_VCLEFT" 13 "GTW_WAKEUP_REASON_LOOP" 12 "GTW_WAKEUP_REASON_DISPLAY_TAP" 11 "GTW_WAKEUP_REASON_URGENT_TRANSMIT_ALERT" 10 "GTW_WAKEUP_REASON_BDY_CAN" 9 "GTW_WAKEUP_REASON_PT_CAN" 8 "GTW_WAKEUP_REASON_UI_SCHEDULED" 7 "GTW_WAKEUP_REASON_RTC_ALARM" 6 "GTW_WAKEUP_REASON_VCFRONT" 5 "GTW_WAKEUP_REASON_VEH_CAN" 4 "GTW_WAKEUP_REASON_ETH_CAN" 3 "GTW_WAKEUP_REASON_CH_CAN" 2 "GTW_WAKEUP_REASON_GSM_RI" 1 "GTW_WAKEUP_REASON_RESET" 0 "GTW_WAKEUP_REASON_NONE" ;
VAL_ 1656 GTW_gearShiftRequest 4 "GEAR_REQUEST_DRIVE" 3 "GEAR_REQUEST_NEUTRAL" 2 "GEAR_REQUEST_REVERSE" 1 "GEAR_REQUEST_PARK" 0 "GEAR_REQUEST_IDLE_SNA" ;
VAL_ 1656 GTW_primaryGearControlStatus 14 "NOT_QUALIFIED_RHD_CONFIG_UNAVAILABLE" 13 "NOT_QUALIFIED_DISPLAY_KNOWN_FROZEN_SCREEN" 12 "NOT_QUALIFIED_DISPLAY_ASIL_VIDEO_ERROR" 11 "NOT_QUALIFIED_GEAR_STRIP_MISMATCH" 10 "NOT_QUALIFIED_DISPLAY_UNTRAINED" 9 "NOT_QUALIFIED_UI_NO_RESP_GEAR_STRIP" 8 "NOT_QUALIFIED_CENTER_DISP_UI_UNHEALTHY" 7 "NOT_QUALIFIED_DISPLAY_FROZEN_ON_GESTURE" 6 "NOT_QUALIFIED_LOW_BRIGHTNESS" 5 "NOT_QUALIFIED_FALSE_TOUCH" 4 "NOT_QUALIFIED_MANUAL" 3 "NOT_QUALIFIED_DISPLAY_ERRS" 2 "NOT_QUALIFIED_FULLSCREEN" 1 "QUALIFIED" 0 "NOT_QUALIFIED" ;
VAL_ 1656 GTW_autoParkRequest 1 "ACTIVE" 0 "IDLE" ;
VAL_ 1656 GTW_smartShiftStatus 9 "DISABLED_AUDIO_NOT_READY" 8 "DISABLED_OSD_ACTIVATED" 7 "DISABLED_DISQUALIFIED" 6 "DISABLED_FULLSCREEN" 5 "DISABLED_UI_MIA" 4 "DISABLED_CLUSTER_DISP_ERR" 3 "DISABLED_CENTER_DISP_ERR" 2 "DISABLED_UI_CONFIG" 1 "ENABLED" 0 "DISABLED_SNA" ;
VAL_ 1656 GTW_gearStripChangeReason 27 "EBUCK_DISABLE" 26 "SLEEP_DISABLE" 25 "VC_MIA_GRACE_DISABLE" 24 "VC_MIA_ENABLE" 23 "DRIVERLESS_NO_TAKEOVER_DISABLE" 22 "EMERGENCY_OPERATION_ENABLE" 21 "WOT_ENABLE" 20 "PARK_ENGAGED_ENABLE" 19 "MISSING_SPEED_OR_STEERING_ESTIMATE_IN_D_ENABLE" 18 "UI_MIA_ENABLE" 16 "NOT_DRIVE_STATE_DISABLE" 15 "FULLSCREEN_DISABLE" 14 "DEFAULT_DISABLE" 13 "REVERSE_ENABLE" 12 "NEUTRAL_ENABLE" 11 "P_AND_BRAKE_ENABLE" 10 "CHARGING_DISABLE" 9 "CRUISE_ACTIVE_DISABLE" 8 "DI_MIA_ENABLE" 7 "HIGH_ACCEL_DISABLE" 6 "MEDIUM_SPEED_DISABLE" 5 "TRAFFIC_CONTROL_NO_CHANGE" 4 "VERY_LOW_SPEED_ENABLE" 3 "HIGH_STEERING_ANGLE_ENABLE" 2 "HIGH_JERK_ENABLE" 1 "DRIVER_BRAKE_APPLY_ENABLE" 0 "SNA" ;
VAL_ 1656 GTW_screenPCBTemperature 2047 "GTW_I2C_TEMP_SNA" ;
VAL_ 2033 GTW_hrlIndex 2 "Mux2" 1 "Mux1" ;
VAL_ 2033 GTW_hrlState 1 "ENABLED" 0 "DISABLED" ;
VAL_ 2033 GTW_hrlTriggerType 15 "HRL_TRIGGER_NONE" 5 "HRL_TRIGGER_EVENT_EXTERNAL" 4 "HRL_TRIGGER_PSEUDONYMOUS" 3 "HRL_TRIGGER_CONTINUOUS" 2 "HRL_TRIGGER_GAME_MODE" 1 "HRL_TRIGGER_EVENT" 0 "HRL_TRIGGER_UDPAPI" ;
VAL_ 60 GTW_infoIndex 255 "END" 31 "SUBCOMPONENT_GITHASH" 30 "PACKAGE_SN_8_14" 29 "PACKAGE_SN_1_7" 27 "PACKAGE_PN_15_20" 26 "PACKAGE_PN_8_14" 25 "PACKAGE_PN_1_7" 23 "SUBCOMPONENT2" 22 "VARIANTCRC" 20 "UDS_PROTOCOL_BOOTCRC" 19 "VERSION_DEPRECATED" 18 "BOOTLOADER_GITHASH" 17 "APP_GITHASH" 16 "SUBCOMPONENT" 15 "BOOTLOADER_CRC" 14 "BOOTLOADER_SVN" 13 "APP_CRC" 11 "PCBAID_ASSYID_USAGEID" 10 "BUILD_HWID_COMPONENTID" 9 "DEPRECATED_9" 8 "DEPRECATED_8" 7 "DEPRECATED_7" 6 "DEPRECATED_6" 5 "DEPRECATED_5" 4 "DEPRECATED_4" 3 "DEPRECATED_3" 2 "DEPRECATED_2" 1 "DEPRECATED_1" 0 "DEPRECATED_0" ;
VAL_ 60 GTW_buildType 4 "INFO_MFG_BUILD" 3 "INFO_TRACEABLE_CI_BUILD" 2 "INFO_LOCAL_BUILD" 1 "INFO_PLATFORM_BUILD" 0 "INFO_UNKNOWN_BUILD" ;
VAL_ 60 GTW_platformType 255 "GTW_PLATFORM_END" 3 "GTW_PLATFORM_MODEL3" 0 "GTW_PLATFORM_UNKNOWN" ;
VAL_ 1370 GTW_mismatchFaultIndex 4 "Mux4" 3 "Mux3" 2 "Mux2" 1 "Mux1" ;
VAL_ 840 GTW_vehicleVersionMatchStatus 2 "MATCHED" 1 "MISMATCHED" 0 "NOT_CALCULATED_YET" ;
VAL_ 840 GTW_hwtype 3 "TRAVEO2" 2 "SPC58" 1 "MPC57" 0 "SNA" ;
VAL_ 840 GTW_jcanProductName 11 "SEMITRUCKV2" 10 "GOLDENSNITCH" 8 "BAYBERRY" 7 "CYBERTRUCK" 6 "POPPYSEED" 5 "SEMITRUCK" 4 "TAMARIND" 3 "LYCHEE" 2 "MODELY" 1 "MODEL3" 0 "SNA" ;
VAL_ 840 GTW_sentryModeState 6 "SNA" 5 "QUIET" 4 "PANIC" 3 "AWARE" 2 "ARMED" 1 "IDLE" 0 "OFF" ;
VAL_ 840 GTW_socSleepType 2 "SHALLOW" 1 "S3" 0 "SNA" ;
VAL_ 840 GTW_resetType 7 "TOUCHCORE_WATCHDOG" 6 "CANCORE_WATCHDOG" 5 "MAINCORE_WATCHDOG" 4 "WAKE" 3 "BUTTON" 2 "SOFTWARE" 1 "POR" 0 "SNA" ;
VAL_ 1112 GTW_nmKeepAwakeReason 15 "GTW_KEEPAWAKE_REASON_TBD" 7 "GTW_KEEPAWAKE_REASON_TCU_TC10_VERSION_UNSUPPORTED" 6 "GTW_KEEPAWAKE_REASON_TCU_TC10_VERSION_CHECK" 5 "GTW_KEEPAWAKE_REASON_EGGLEFT_LINK_DOWN" 4 "GTW_KEEPAWAKE_REASON_URGENT_TRANSMIT_ALERT" 3 "GTW_KEEPAWAKE_REASON_FCSM_ACTIVE" 2 "GTW_KEEPAWAKE_REASON_GSM_RI" 1 "GTW_KEEPAWAKE_REASON_UI_SCHEDULED" 0 "GTW_KEEPAWAKE_REASON_NONE_SNA" ;
VAL_ 1112 GTW_nmWakeUpReason 15 "GTW_WAKEUP_REASON_RCMPRIVATE_CAN" 14 "GTW_WAKEUP_REASON_VCLEFT" 13 "GTW_WAKEUP_REASON_LOOP" 12 "GTW_WAKEUP_REASON_DISPLAY_TAP" 11 "GTW_WAKEUP_REASON_URGENT_TRANSMIT_ALERT" 10 "GTW_WAKEUP_REASON_BDY_CAN" 9 "GTW_WAKEUP_REASON_PT_CAN" 8 "GTW_WAKEUP_REASON_UI_SCHEDULED" 7 "GTW_WAKEUP_REASON_RTC_ALARM" 6 "GTW_WAKEUP_REASON_VCFRONT" 5 "GTW_WAKEUP_REASON_VEH_CAN" 4 "GTW_WAKEUP_REASON_ETH_CAN" 3 "GTW_WAKEUP_REASON_CH_CAN" 2 "GTW_WAKEUP_REASON_GSM_RI" 1 "GTW_WAKEUP_REASON_RESET" 0 "GTW_WAKEUP_REASON_NONE" ;
VAL_ 1112 GTW_ethKeepAwakeReason 3 "TCU_TC10_VERSION_UNSUPPORTED" 2 "TCU_TC10_VERSION_CHECK" 1 "URGENT_TRANSMIT_ALERT" 0 "NONE_SNA" ;
VAL_ 1112 GTW_nmDebugWakeUp 2147483648 "WKPU_31" 1073741824 "WKPU_30" 536870912 "WKPU_29" 268435456 "WKPU_28" 134217728 "WKPU_27" 67108864 "WKPU_26" 33554432 "WKPU_25" 16777216 "WKPU_24" 8388608 "WKPU_23" 4194304 "WKPU_22" 2097152 "WKPU_21" 1048576 "WKPU_20" 524288 "WKPU_19" 262144 "WKPU_18" 131072 "WKPU_17" 65536 "WKPU_16" 32768 "WKPU_15" 16384 "WKPU_14" 8192 "WKPU_13" 4096 "WKPU_12" 2048 "WKPU_11" 1024 "WKPU_10" 512 "WKPU_9" 256 "WKPU_8" 128 "WKPU_7" 64 "WKPU_6" 32 "WKPU_5" 16 "WKPU_4" 8 "WKPU_3" 4 "WKPU_2" 2 "WKPU_1" 1 "WKPU_0" 0 "WKPU_NONE" ;
